VERSION ""

NS_ :

BS_:

BU_: VMCU TPM RCIOM FCIOM FAS ECUspare4 EBS EAS CCIOM BPMU APM

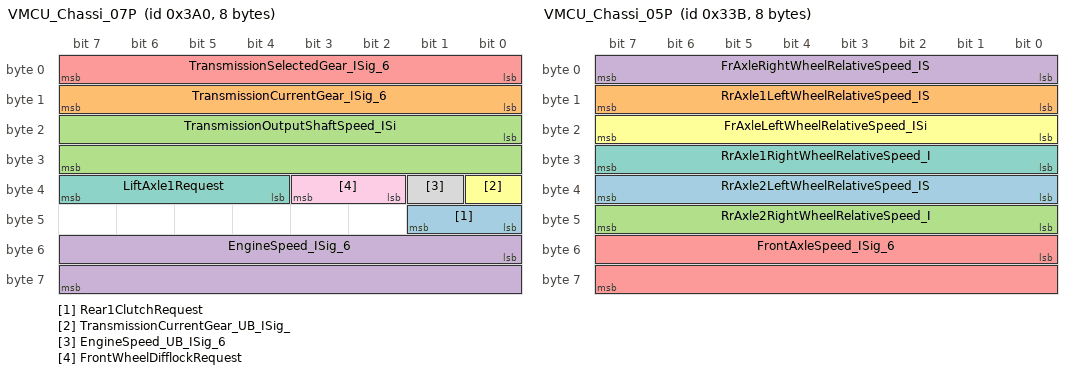
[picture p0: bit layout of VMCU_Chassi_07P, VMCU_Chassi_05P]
BO_ 928 VMCU_Chassi_07P: 8 VMCU
 SG_ Rear1ClutchRequest : 40|2@1+ (1,0) [0|0] ""  RCIOM
 SG_ TransmissionCurrentGear_ISig_6 : 8|8@1+ (1,-125) [-125|130] "GearValue"  CCIOM,APM
 SG_ TransmissionOutputShaftSpeed_ISi : 16|16@1+ (0.125,0) [0|8191.875] "rpm"  APM
 SG_ EngineSpeed_ISig_6 : 48|16@1+ (0.125,0) [0|8191.875] "rpm"  APM,FAS,CCIOM
 SG_ TransmissionSelectedGear_ISig_6 : 0|8@1+ (1,-125) [-125|130] "GearValue"  CCIOM
 SG_ TransmissionCurrentGear_UB_ISig_ : 32|1@1+ (1,0) [0|0] ""  APM,CCIOM
 SG_ LiftAxle1Request : 36|4@1+ (1,0) [0|0] ""  RCIOM
 SG_ EngineSpeed_UB_ISig_6 : 33|1@1+ (1,0) [0|0] ""  CCIOM,FAS,APM
 SG_ FrontWheelDifflockRequest : 34|2@1+ (1,0) [0|0] ""  CCIOM

BO_ 827 VMCU_Chassi_05P: 8 VMCU
 SG_ RrAxle2LeftWheelRelativeSpeed_IS : 32|8@1+ (0.0625,-7.8125) [-7.8125|8.125] "Km_per_h"  APM
 SG_ RrAxle1LeftWheelRelativeSpeed_IS : 8|8@1+ (0.0625,-7.8125) [-7.8125|8.125] "Km_per_h"  APM
 SG_ RrAxle2RightWheelRelativeSpeed_I : 40|8@1+ (0.0625,-7.8125) [-7.8125|8.125] "Km_per_h"  APM
 SG_ FrAxleRightWheelRelativeSpeed_IS : 0|8@1+ (0.0625,-7.8125) [-7.8125|8.125] "Km_per_h"  APM,RCIOM
 SG_ FrontAxleSpeed_ISig_6 : 48|16@1+ (0.00390625,0) [0|255.99609375] "Km_per_h"  CCIOM,APM,RCIOM
 SG_ FrAxleLeftWheelRelativeSpeed_ISi : 16|8@1+ (0.0625,-7.8125) [-7.8125|8.125] "Km_per_h"  RCIOM,APM
 SG_ RrAxle1RightWheelRelativeSpeed_I : 24|8@1+ (0.0625,-7.8125) [-7.8125|8.125] "Km_per_h"  APM

BO_ 537 VMCU_Chassi_04P: 8 VMCU
 SG_ RampLevelStorageRequest_ISig_6 : 16|4@1+ (1,0) [0|0] ""  RCIOM
 SG_ LevelStrokeRequest_ISig_6 : 32|2@1+ (1,0) [0|0] ""  RCIOM
 SG_ RideHeightFunctionRequest_UB_ISi : 63|1@1+ (1,0) [0|0] ""  RCIOM
 SG_ BBSystemProhibitControlRequest_I : 30|2@1+ (1,0) [0|0] ""  RCIOM
 SG_ RideHeightFunctionRequest_ISig_6 : 12|4@1+ (1,0) [0|0] ""  RCIOM
 SG_ BBSystemAlternatLoadDistribReq_I : 59|2@1+ (1,0) [0|0] ""  RCIOM
 SG_ AltLoadDistribution_rqst_ISig_6 : 56|3@1+ (1,0) [0|0] ""  RCIOM
 SG_ FerryFunctionRequest_ISig_6 : 28|2@1+ (1,0) [0|0] ""  RCIOM
 SG_ FerryFunctionSwitchChangeReq_ISi : 61|2@1+ (1,0) [0|0] ""  RCIOM
 SG_ FirstAxleLowerPrioRequested_ISig : 50|3@1+ (1,0) [0|0] ""  RCIOM
 SG_ LiftAxle1AutoLiftRequest_UB_ISig : 23|1@1+ (1,0) [0|0] ""  RCIOM
 SG_ BBSystemSpeedDepDriveLevelReq_IS : 26|2@1+ (1,0) [0|0] ""  RCIOM
 SG_ LiftAxle1LiftPositionRequest_UB_ : 39|1@1+ (1,0) [0|0] ""  RCIOM
 SG_ LoadDistributionChangeRequest_UB : 47|1@1+ (1,0) [0|0] ""  RCIOM
 SG_ LoadDistributionChangeRequest_IS : 48|2@1+ (1,0) [0|0] ""  RCIOM
 SG_ BBSystemAlternatLoadDistribReq_U : 55|1@1+ (1,0) [0|0] ""  RCIOM
 SG_ BBSystemKneelRequest_ISig_6 : 8|2@1+ (1,0) [0|0] ""  RCIOM
 SG_ LiftAxle1LiftPositionRequest_ISi : 36|3@1+ (1,0) [0|0] ""  RCIOM
 SG_ LiftAxle2AutoLiftRequest_ISig_6 : 40|2@1+ (1,0) [0|0] ""  RCIOM
 SG_ StopLevelChangeRequest_ISig_6 : 24|2@1+ (1,0) [0|0] ""  RCIOM
 SG_ RideHeightStorageRequest_ISig_6 : 4|4@1+ (1,0) [0|0] ""  RCIOM
 SG_ RampLevelRequest_ISig_6 : 0|4@1+ (1,0) [0|0] ""  RCIOM
 SG_ LiftAxle1AutoLiftRequest_ISig_6 : 34|2@1+ (1,0) [0|0] ""  RCIOM
 SG_ FirstAxleLowerPrioRequested_UB_I : 53|1@1+ (1,0) [0|0] ""  RCIOM
 SG_ LiftAxle2AutoLiftRequest_UB_ISig : 42|1@1+ (1,0) [0|0] ""  RCIOM
 SG_ AltLoadDistribution_rqst_UB_ISig : 54|1@1+ (1,0) [0|0] ""  RCIOM
 SG_ LiftAxle2LiftPositionRequest_UB_ : 46|1@1+ (1,0) [0|0] ""  RCIOM
 SG_ FerryFunctionRequest_UB_ISig_6 : 10|1@1+ (1,0) [0|0] ""  RCIOM
 SG_ LiftAxle2LiftPositionRequest_ISi : 43|3@1+ (1,0) [0|0] ""  RCIOM

BO_ 531 VMCU_Chassi_02P: 8 VMCU
 SG_ TrailerBrakePres_rqst_UB : 31|1@1+ (1,0) [0|0] ""  CCIOM
 SG_ GearLeverPosition_UB_ISig_6 : 48|1@1+ (1,0) [0|0] ""  APM,CCIOM
 SG_ WS_Washing_cmd : 6|2@1+ (1,0) [0|0] ""  FCIOM
 SG_ FrAxleDiffLockActvnDriverRqst_IS : 36|2@1+ (1,0) [0|0] ""  CCIOM
 SG_ FuncIndIlluminationLevel_ISig_6 : 24|3@1+ (1,0) [0|0] ""  APM
 SG_ TrailerBrakePres_rqst : 56|8@1+ (8,0) [0|2040] "kPa"  CCIOM
 SG_ ASREngineControlActive_ISig_6 : 38|2@1+ (1,0) [0|0] ""  FAS
 SG_ TransmissionDrivelineEngaged_ISi : 16|2@1+ (1,0) [0|0] ""  CCIOM,APM
 SG_ ReverseWarning_rqst_ISig_6 : 0|2@1+ (1,0) [0|0] ""  APM,RCIOM
 SG_ ASREngineControlActive_UB_ISig_6 : 13|1@1+ (1,0) [0|0] ""  FAS
 SG_ SplitBoxDifflockActvnDrvrRqst_UB : 50|1@1+ (1,0) [0|0] ""  CCIOM,EBS
 SG_ FogLight_Rear_cmd : 2|2@1+ (1,0) [0|0] ""  CCIOM,RCIOM
 SG_ FogLight_Front_cmd_ISig_6 : 8|2@1+ (1,0) [0|0] ""  FCIOM
 SG_ ASRBrakeControlActive_UB_ISig_6 : 12|1@1+ (1,0) [0|0] ""  EAS,FAS,APM
 SG_ TransmissionDrivelineEngaged_UB_ : 51|1@1+ (1,0) [0|0] ""  APM,CCIOM
 SG_ SplitBoxDifflockActvnDrvrRqst_IS : 22|2@1+ (1,0) [0|0] ""  EBS,CCIOM
 SG_ AntiLockBrakingActive_ISig_6 : 4|2@1+ (1,0) [0|0] ""  APM,FAS,EAS
 SG_ ASRBrakeControlActive_ISig_6 : 18|2@1+ (1,0) [0|0] ""  FAS,EAS,APM
 SG_ GearLeverPosition_ISig_6 : 27|4@1+ (1,0) [0|0] ""  CCIOM,APM
 SG_ ClutchPedalPosition_ISig_6 : 40|8@1+ (0.4,0) [0|102] "Percent"  APM
 SG_ TransmissionShiftInProcess_UB_IS : 52|1@1+ (1,0) [0|0] ""  APM
 SG_ BackToDriveReq_ISig_6 : 14|2@1+ (1,0) [0|0] ""  RCIOM
 SG_ FrAxleDiffLockActvnDriverRqst_UB : 49|1@1+ (1,0) [0|0] ""  CCIOM
 SG_ TransmissionShiftInProcess_ISig_ : 10|2@1+ (1,0) [0|0] ""  APM
 SG_ EngineTorqueMode_ISig_6 : 32|4@1+ (1,0) [0|0] ""  APM

BO_ 392 VMCU_Chassi_01P: 8 VMCU
 SG_ WorkingLightChassisOutp_cmd : 62|2@1+ (1,0) [0|0] ""  CCIOM
 SG_ PositionLight_cmd : 10|2@1+ (1,0) [0|0] ""  FCIOM,RCIOM
 SG_ StaticCornerLight_cmd : 52|3@1+ (1,0) [0|0] ""  FCIOM
 SG_ ExtraMainBeam_cmd : 14|2@1+ (1,0) [0|0] ""  FCIOM
 SG_ BacklightCmd_ISig_6 : 27|5@1+ (1,0) [0|0] ""  APM
 SG_ DirectionIndicatorLights_cmd : 16|3@1+ (1,0) [0|0] ""  RCIOM,FCIOM,CCIOM
 SG_ DirectionIndicatorLights_rqst : 24|3@1+ (1,0) [0|0] ""  FCIOM
 SG_ DriverEngineShutOff_rqst : 8|2@1+ (1,0) [0|0] ""  APM
 SG_ DippedBeam_cmd : 0|2@1+ (1,0) [0|0] ""  FCIOM,RCIOM
 SG_ BrakePedalPosition_ISig_6 : 32|8@1+ (0.4,0) [0|102] "Percent"  RCIOM,APM
 SG_ AcctrPedalKickDownSw_stat_ISig_6 : 12|2@1+ (1,0) [0|0] ""  APM
 SG_ HeadLightLevel_cmd : 56|6@1+ (1,-16) [-16|47] ""  FCIOM,CCIOM
 SG_ DRL_cmd : 4|2@1+ (1,0) [0|0] ""  RCIOM,FCIOM
 SG_ AcceleratorPedalLowIdleSwitch_IS : 2|2@1+ (1,0) [0|0] ""  APM
 SG_ MainBeam_cmd_ISig_6 : 19|3@1+ (1,0) [0|0] ""  FCIOM,RCIOM
 SG_ Hazard_rqst_ISig_6 : 6|2@1+ (1,0) [0|0] ""  FCIOM
 SG_ VehicleMode_ISig_6 : 48|4@1+ (1,0) [0|0] ""  FAS,CCIOM,TPM,RCIOM,FCIOM,APM,EAS,BPMU
 SG_ VehicleMode_UB_ISig_6 : 55|1@1+ (1,0) [0|0] ""  BPMU,EAS,APM,FAS,CCIOM,RCIOM,TPM,FCIOM
 SG_ AcceleratorPedalPosition1_ISig_6 : 40|8@1+ (0.4,0) [0|102] "Percent"  APM,CCIOM,RCIOM

BO_ 2671902706 TesterFuncDiagMsg_Chassi: 8 VMCU
 SG_ FuncDiagDataTester_ISig_6 : 0|64@1+ (1,0) [0|0] ""  APM,CCIOM,EAS,RCIOM,BPMU,FAS,TPM,FCIOM

BO_ 1248 TPM_Chassi_07P: 8 TPM
 SG_ TPMMateTrailerResp_ISig_6 : 0|3@1+ (1,0) [0|0] ""  VMCU
 SG_ Trailer2TPMLeakageWarning_UB_ISi : 30|1@1+ (1,0) [0|0] ""  VMCU
 SG_ TruckTPMPressureWarning_UB_ISig_ : 28|1@1+ (1,0) [0|0] ""  VMCU
 SG_ TPMAutomaticMating_ISig_6 : 16|2@1+ (1,0) [0|0] ""  VMCU
 SG_ Trailer1TPMPressureWarning_ISig_ : 24|3@1+ (1,0) [0|0] ""  VMCU
 SG_ Trailer1TPMPressureWarning_UB_IS : 32|1@1+ (1,0) [0|0] ""  VMCU
 SG_ TPMMateTrailerResp_UB_ISig_6 : 27|1@1+ (1,0) [0|0] ""  VMCU
 SG_ Trailer2TPMPressureWarning_UB_IS : 33|1@1+ (1,0) [0|0] ""  VMCU
 SG_ Trailer2TPMPressureWarning_ISig_ : 21|3@1+ (1,0) [0|0] ""  VMCU
 SG_ Trailer1TPMMatedStatus_ISig_6 : 11|2@1+ (1,0) [0|0] ""  VMCU
 SG_ Trailer1TPMLeakageWarning_ISig_6 : 18|3@1+ (1,0) [0|0] ""  VMCU
 SG_ Trailer2TPMMatedStatus_ISig_6 : 6|2@1+ (1,0) [0|0] ""  VMCU
 SG_ TruckTPMLeakageWarning_UB_ISig_6 : 29|1@1+ (1,0) [0|0] ""  VMCU
 SG_ TruckTPMPressureWarning_ISig_6 : 3|3@1+ (1,0) [0|0] ""  VMCU
 SG_ Trailer1TPMLeakageWarning_UB_ISi : 31|1@1+ (1,0) [0|0] ""  VMCU
 SG_ TruckTPMLeakageWarning_ISig_6 : 8|3@1+ (1,0) [0|0] ""  VMCU
 SG_ Trailer2TPMLeakageWarning_ISig_6 : 13|3@1+ (1,0) [0|0] ""  VMCU

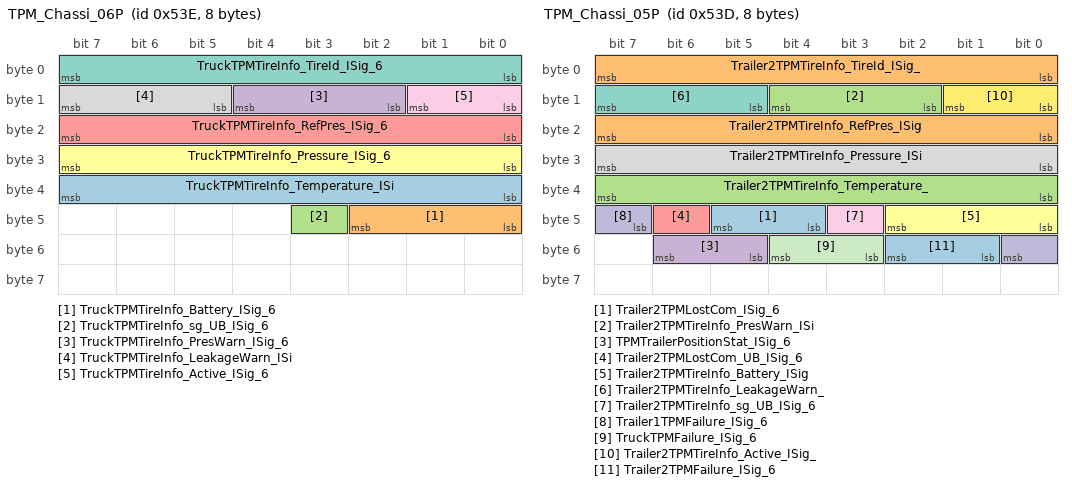
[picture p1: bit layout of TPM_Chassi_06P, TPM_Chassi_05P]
BO_ 1342 TPM_Chassi_06P: 8 TPM
 SG_ TruckTPMTireInfo_Temperature_ISi : 32|8@1+ (1,-50) [-50|205] "DegreeC"  VMCU
 SG_ TruckTPMTireInfo_Battery_ISig_6 : 40|3@1+ (1,0) [0|0] ""  VMCU
 SG_ TruckTPMTireInfo_sg_UB_ISig_6 : 43|1@1+ (1,0) [0|0] ""  VMCU
 SG_ TruckTPMTireInfo_PresWarn_ISig_6 : 10|3@1+ (1,0) [0|0] ""  VMCU
 SG_ TruckTPMTireInfo_RefPres_ISig_6 : 16|8@1+ (10,0) [0|2550] "kPa"  VMCU
 SG_ TruckTPMTireInfo_Pressure_ISig_6 : 24|8@1+ (10,0) [0|2550] "kPa"  VMCU
 SG_ TruckTPMTireInfo_TireId_ISig_6 : 0|8@1+ (1,0) [0|255] "NotApplicable"  VMCU
 SG_ TruckTPMTireInfo_LeakageWarn_ISi : 13|3@1+ (1,0) [0|0] ""  VMCU
 SG_ TruckTPMTireInfo_Active_ISig_6 : 8|2@1+ (1,0) [0|0] ""  VMCU

BO_ 1341 TPM_Chassi_05P: 8 TPM
 SG_ Trailer2TPMLostCom_ISig_6 : 44|2@1+ (1,0) [0|0] ""  VMCU
 SG_ Trailer2TPMTireInfo_RefPres_ISig : 16|8@1+ (10,0) [0|2550] "kPa"  VMCU
 SG_ Trailer2TPMTireInfo_PresWarn_ISi : 10|3@1+ (1,0) [0|0] ""  VMCU
 SG_ TPMTrailerPositionStat_ISig_6 : 53|2@1+ (1,0) [0|0] ""  VMCU
 SG_ Trailer2TPMLostCom_UB_ISig_6 : 46|1@1+ (1,0) [0|0] ""  VMCU
 SG_ Trailer2TPMTireInfo_Battery_ISig : 40|3@1+ (1,0) [0|0] ""  VMCU
 SG_ Trailer2TPMTireInfo_LeakageWarn_ : 13|3@1+ (1,0) [0|0] ""  VMCU
 SG_ Trailer2TPMTireInfo_Pressure_ISi : 24|8@1+ (10,0) [0|2550] "kPa"  VMCU
 SG_ Trailer2TPMTireInfo_sg_UB_ISig_6 : 43|1@1+ (1,0) [0|0] ""  VMCU
 SG_ Trailer1TPMFailure_ISig_6 : 47|2@1+ (1,0) [0|0] ""  VMCU
 SG_ TruckTPMFailure_ISig_6 : 51|2@1+ (1,0) [0|0] ""  VMCU
 SG_ Trailer2TPMTireInfo_Active_ISig_ : 8|2@1+ (1,0) [0|0] ""  VMCU
 SG_ Trailer2TPMFailure_ISig_6 : 49|2@1+ (1,0) [0|0] ""  VMCU
 SG_ Trailer2TPMTireInfo_TireId_ISig_ : 0|8@1+ (1,0) [0|255] "NotApplicable"  VMCU
 SG_ Trailer2TPMTireInfo_Temperature_ : 32|8@1+ (1,-50) [-50|205] "DegreeC"  VMCU

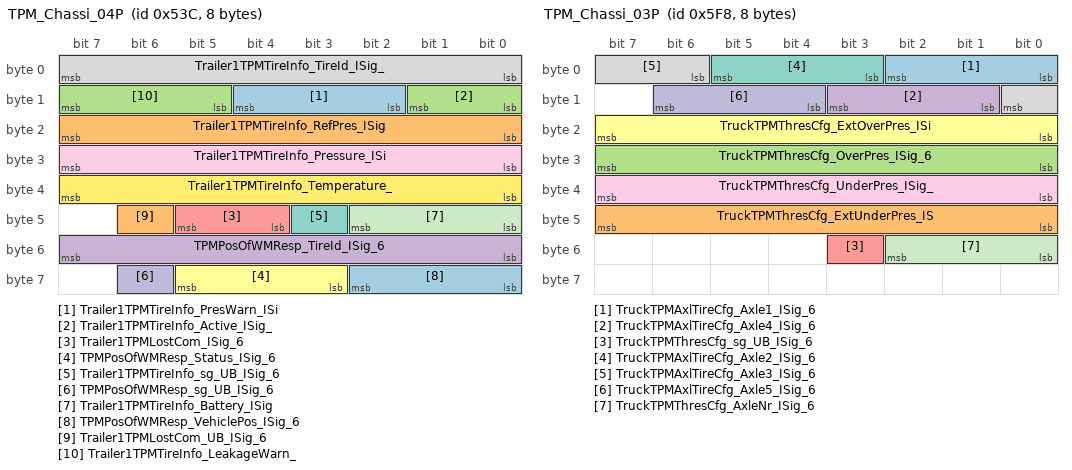
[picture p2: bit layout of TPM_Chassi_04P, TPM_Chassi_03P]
BO_ 1340 TPM_Chassi_04P: 8 TPM
 SG_ Trailer1TPMTireInfo_PresWarn_ISi : 10|3@1+ (1,0) [0|0] ""  VMCU
 SG_ Trailer1TPMTireInfo_RefPres_ISig : 16|8@1+ (10,0) [0|2550] "kPa"  VMCU
 SG_ Trailer1TPMTireInfo_Active_ISig_ : 8|2@1+ (1,0) [0|0] ""  VMCU
 SG_ TPMPosOfWMResp_TireId_ISig_6 : 48|8@1+ (1,0) [0|255] "NotApplicable"  VMCU
 SG_ Trailer1TPMLostCom_ISig_6 : 44|2@1+ (1,0) [0|0] ""  VMCU
 SG_ TPMPosOfWMResp_Status_ISig_6 : 59|3@1+ (1,0) [0|0] ""  VMCU
 SG_ Trailer1TPMTireInfo_sg_UB_ISig_6 : 43|1@1+ (1,0) [0|0] ""  VMCU
 SG_ Trailer1TPMTireInfo_TireId_ISig_ : 0|8@1+ (1,0) [0|255] "NotApplicable"  VMCU
 SG_ Trailer1TPMTireInfo_Pressure_ISi : 24|8@1+ (10,0) [0|2550] "kPa"  VMCU
 SG_ TPMPosOfWMResp_sg_UB_ISig_6 : 62|1@1+ (1,0) [0|0] ""  VMCU
 SG_ Trailer1TPMTireInfo_Battery_ISig : 40|3@1+ (1,0) [0|0] ""  VMCU
 SG_ Trailer1TPMTireInfo_Temperature_ : 32|8@1+ (1,-50) [-50|205] "DegreeC"  VMCU
 SG_ TPMPosOfWMResp_VehiclePos_ISig_6 : 56|3@1+ (1,0) [0|0] ""  VMCU
 SG_ Trailer1TPMLostCom_UB_ISig_6 : 46|1@1+ (1,0) [0|0] ""  VMCU
 SG_ Trailer1TPMTireInfo_LeakageWarn_ : 13|3@1+ (1,0) [0|0] ""  VMCU

BO_ 1528 TPM_Chassi_03P: 8 TPM
 SG_ TruckTPMAxlTireCfg_Axle1_ISig_6 : 0|3@1+ (1,0) [0|0] ""  VMCU
 SG_ TruckTPMThresCfg_ExtUnderPres_IS : 40|8@1+ (1,-125) [-125|130] "Percent"  VMCU
 SG_ TruckTPMThresCfg_OverPres_ISig_6 : 24|8@1+ (1,-125) [-125|130] "Percent"  VMCU
 SG_ TruckTPMAxlTireCfg_Axle4_ISig_6 : 9|3@1+ (1,0) [0|0] ""  VMCU
 SG_ TruckTPMThresCfg_sg_UB_ISig_6 : 51|1@1+ (1,0) [0|0] ""  VMCU
 SG_ TruckTPMThresCfg_ExtOverPres_ISi : 16|8@1+ (1,-125) [-125|130] "Percent"  VMCU
 SG_ TruckTPMAxlTireCfg_Axle2_ISig_6 : 3|3@1+ (1,0) [0|0] ""  VMCU
 SG_ TruckTPMAxlTireCfg_Axle3_ISig_6 : 6|3@1+ (1,0) [0|0] ""  VMCU
 SG_ TruckTPMThresCfg_UnderPres_ISig_ : 32|8@1+ (1,-125) [-125|130] "Percent"  VMCU
 SG_ TruckTPMAxlTireCfg_Axle5_ISig_6 : 12|3@1+ (1,0) [0|0] ""  VMCU
 SG_ TruckTPMThresCfg_AxleNr_ISig_6 : 48|3@1+ (1,0) [0|0] ""  VMCU

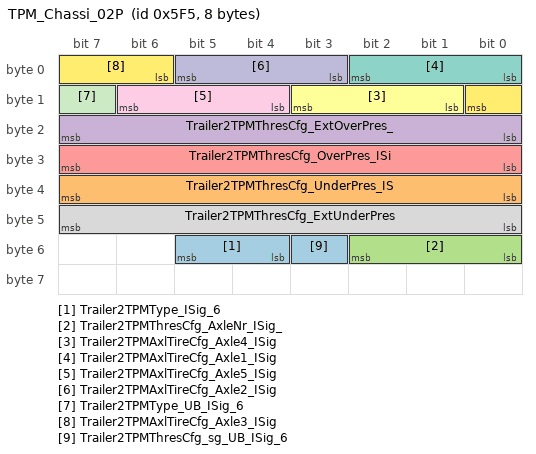
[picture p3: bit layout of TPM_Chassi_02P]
BO_ 1525 TPM_Chassi_02P: 8 TPM
 SG_ Trailer2TPMType_ISig_6 : 52|2@1+ (1,0) [0|0] ""  VMCU
 SG_ Trailer2TPMThresCfg_UnderPres_IS : 32|8@1+ (1,-125) [-125|130] "Percent"  VMCU
 SG_ Trailer2TPMThresCfg_AxleNr_ISig_ : 48|3@1+ (1,0) [0|0] ""  VMCU
 SG_ Trailer2TPMThresCfg_ExtOverPres_ : 16|8@1+ (1,-125) [-125|130] "Percent"  VMCU
 SG_ Trailer2TPMThresCfg_OverPres_ISi : 24|8@1+ (1,-125) [-125|130] "Percent"  VMCU
 SG_ Trailer2TPMAxlTireCfg_Axle4_ISig : 9|3@1+ (1,0) [0|0] ""  VMCU
 SG_ Trailer2TPMAxlTireCfg_Axle1_ISig : 0|3@1+ (1,0) [0|0] ""  VMCU
 SG_ Trailer2TPMThresCfg_ExtUnderPres : 40|8@1+ (1,-125) [-125|130] "Percent"  VMCU
 SG_ Trailer2TPMAxlTireCfg_Axle5_ISig : 12|3@1+ (1,0) [0|0] ""  VMCU
 SG_ Trailer2TPMAxlTireCfg_Axle2_ISig : 3|3@1+ (1,0) [0|0] ""  VMCU
 SG_ Trailer2TPMType_UB_ISig_6 : 15|1@1+ (1,0) [0|0] ""  VMCU
 SG_ Trailer2TPMAxlTireCfg_Axle3_ISig : 6|3@1+ (1,0) [0|0] ""  VMCU
 SG_ Trailer2TPMThresCfg_sg_UB_ISig_6 : 51|1@1+ (1,0) [0|0] ""  VMCU

CM_ SG_ 928 TransmissionCurrentGear_ISig_6 "254 Error ; 255 Not available";
CM_ SG_ 928 TransmissionOutputShaftSpeed_ISi "65024 - 65279 Error ; 65280 - 65535 Not available";
CM_ SG_ 928 EngineSpeed_ISig_6 "65024 - 65279 Error ; 65280 - 65535 Not available";
CM_ SG_ 928 TransmissionSelectedGear_ISig_6 "254 Error ; 255 Not available";
CM_ BO_ 827 "This is a sporadic message but this message comes periodically because all signal in the message are gatewayed signals from BB1 and they are periodical there. If there is no traffic on BB1 this message is not sent on Chassi network.";
CM_ SG_ 827 RrAxle2LeftWheelRelativeSpeed_IS "254 Error ; 255 Not available";
CM_ SG_ 827 RrAxle1LeftWheelRelativeSpeed_IS "254 Error ; 255 Not available";
CM_ SG_ 827 RrAxle2RightWheelRelativeSpeed_I "254 Error ; 255 Not available";
CM_ SG_ 827 FrAxleRightWheelRelativeSpeed_IS "254 Error ; 255 Not available";
CM_ SG_ 827 FrontAxleSpeed_ISig_6 "65024 - 65279 Error ; 65280 - 65535 Not available";
CM_ SG_ 827 FrAxleLeftWheelRelativeSpeed_ISi "254 Error ; 255 Not available";
CM_ SG_ 827 RrAxle1RightWheelRelativeSpeed_I "254 Error ; 255 Not available";
CM_ SG_ 531 TrailerBrakePres_rqst "254 Error ; 255 Not available";
CM_ SG_ 531 ClutchPedalPosition_ISig_6 "254 Error ; 255 Not available";
CM_ SG_ 392 BrakePedalPosition_ISig_6 "254 Error ; 255 Not available";
CM_ SG_ 392 HeadLightLevel_cmd "62 Error ; 63 Not available";
CM_ SG_ 392 AcceleratorPedalPosition1_ISig_6 "254 Error ; 255 Not available";
CM_ SG_ 1342 TruckTPMTireInfo_Temperature_ISi "251-253	Spare; 254 Error; 255 NotAvailable;";
CM_ SG_ 1342 TruckTPMTireInfo_RefPres_ISig_6 "251-253 Spare; 254 Error; 255 NotAvailable;";
CM_ SG_ 1342 TruckTPMTireInfo_Pressure_ISig_6 "251-253 Spare; 254 Error; 255 NotAvailable;";
CM_ SG_ 1341 Trailer2TPMTireInfo_RefPres_ISig "251-253 Spare; 254 Error; 255 NotAvailable;";
CM_ SG_ 1341 Trailer2TPMTireInfo_Pressure_ISi "251-253 Spare; 254 Error; 255 NotAvailable;";
CM_ SG_ 1341 Trailer2TPMTireInfo_Temperature_ "251-253	Spare; 254 Error; 255 NotAvailable;";
CM_ SG_ 1340 Trailer1TPMTireInfo_RefPres_ISig "251-253 Spare; 254 Error; 255 NotAvailable;";
CM_ SG_ 1340 Trailer1TPMTireInfo_Pressure_ISi "251-253 Spare; 254 Error; 255 NotAvailable;";
CM_ SG_ 1340 Trailer1TPMTireInfo_Temperature_ "251-253	Spare; 254 Error; 255 NotAvailable;";
BA_DEF_ BO_  "GenMsgStartDelayTime" INT 0 0;
BA_DEF_ BO_  "GenMsgDelayTime" INT 0 0;
BA_DEF_ BO_  "GenMsgCycleTime" INT 0 0;
BA_DEF_ BO_  "GenMsgSendType" ENUM  "Cyclic","NotUsed","NotUsed","NotUsed","NotUsed","NotUsed","NotUsed","IfActive","NoMsgSendType","NotUsed";
BA_DEF_ SG_  "GenSigStartValue" INT 0 0;
BA_DEF_ SG_  "GenSigInactiveValue" INT 0 0;
BA_DEF_ SG_  "GenSigCycleTimeActive" INT 0 0;
BA_DEF_ SG_  "GenSigCycleTime" INT 0 0;
BA_DEF_ SG_  "GenSigSendType" ENUM  "Cyclic","OnWrite","OnWriteWithRepetition","OnChange","OnChangeWithRepetition","IfActive","IfActiveWithRepetition","NoSigSendType","NotUsed","NotUsed","NotUsed","NotUsed","NotUsed";
BA_DEF_ BO_  "VFrameFormat" ENUM  "StandardCAN","ExtendedCAN","reserved","J1939PG";
BA_DEF_ SG_  "SigType" ENUM  "Default","Range","RangeSigned","ASCII","Discrete","Control","ReferencePGN","DTC","StringDelimiter","StringLength","StringLengthControl";
BA_DEF_ SG_  "SeToolVersion_SIGNAL" STRING ;
BA_DEF_ SG_  "SeToolUniqueID_SIGNAL" STRING ;
BA_DEF_ SG_  "SeToolName_SIGNAL" STRING ;
BA_DEF_ SG_  "SeToolItemID_SIGNAL" STRING ;
BA_DEF_ SG_  "SeToolAncestorID_SIGNAL" STRING ;
BA_DEF_ SG_  "Platform_VMCU1_Sig" ENUM  "No","Yes";
BA_DEF_ BO_  "NmAsrMessage" ENUM  "No","Yes";
BA_DEF_ SG_  "NeedsUpdateBit" ENUM  "No","Yes";
BA_DEF_ SG_  "MmAnSignal" ENUM  "No","Yes";
BA_DEF_ SG_  "GenSigMaxLatency" INT 0 65535;
BA_DEF_ SG_  "GenSigILSupport" ENUM  "Yes","No";
BA_DEF_ BO_  "GenMsgRequestable" INT 0 1;
BA_DEF_ BO_  "GenMsgILSupport" ENUM  "No","Yes";
BA_DEF_ BO_  "DiagUUDTResponse" ENUM  "No","Yes";
BA_DEF_ BO_  "DiagState" ENUM  "No","Yes";
BA_DEF_ BO_  "DiagResponse" ENUM  "No","Yes";
BA_DEF_ BO_  "DiagRequest" ENUM  "No","Yes";
BA_DEF_ BO_  "DiagConnection" HEX 0 65535;
BA_DEF_ BO_  "CanTpFcFrameId" HEX 0 2147483647;
BA_DEF_ BO_  "CanTpBs" INT 0 255;
BA_DEF_ SG_  "SystemSignalLongSymbol" STRING ;
BA_DEF_REL_ BU_SG_REL_  "GenSigTimeoutTime" INT 0 65535;
BA_DEF_REL_ BU_SG_REL_  "GenSigFirstTimeoutTime" INT 0 65535;
BA_DEF_DEF_  "GenMsgStartDelayTime" 0;
BA_DEF_DEF_  "GenMsgDelayTime" 0;
BA_DEF_DEF_  "GenMsgCycleTime" 0;
BA_DEF_DEF_  "GenMsgSendType" "Cyclic";
BA_DEF_DEF_  "GenSigStartValue" 0;
BA_DEF_DEF_  "GenSigInactiveValue" 0;
BA_DEF_DEF_  "GenSigCycleTimeActive" 0;
BA_DEF_DEF_  "GenSigCycleTime" 0;
BA_DEF_DEF_  "GenSigSendType" "Cyclic";
BA_DEF_DEF_  "VFrameFormat" "ExtendedCAN";
BA_DEF_DEF_  "SigType" "Default";
BA_DEF_DEF_  "SeToolVersion_SIGNAL" "";
BA_DEF_DEF_  "SeToolUniqueID_SIGNAL" "";
BA_DEF_DEF_  "SeToolName_SIGNAL" "";
BA_DEF_DEF_  "SeToolItemID_SIGNAL" "";
BA_DEF_DEF_  "SeToolAncestorID_SIGNAL" "";
BA_DEF_DEF_  "Platform_VMCU1_Sig" "No";
BA_DEF_DEF_  "NmAsrMessage" "No";
BA_DEF_DEF_  "NeedsUpdateBit" "No";
BA_DEF_DEF_  "MmAnSignal" "No";
BA_DEF_DEF_  "GenSigMaxLatency" 0;
BA_DEF_DEF_  "GenSigILSupport" "Yes";
BA_DEF_DEF_  "GenMsgRequestable" 1;
BA_DEF_DEF_  "GenMsgILSupport" "Yes";
BA_DEF_DEF_  "DiagUUDTResponse" "No";
BA_DEF_DEF_  "DiagState" "No";
BA_DEF_DEF_  "DiagResponse" "No";
BA_DEF_DEF_  "DiagRequest" "No";
BA_DEF_DEF_  "DiagConnection" 0;
BA_DEF_DEF_  "CanTpFcFrameId" 2147483647;
BA_DEF_DEF_  "CanTpBs" 255;
BA_DEF_DEF_REL_ "GenSigTimeoutTime" 0;
BA_DEF_DEF_REL_ "GenSigFirstTimeoutTime" 0;
BA_DEF_DEF_  "SystemSignalLongSymbol" "";
BA_ "VFrameFormat" BO_ 928 0;
BA_ "GenMsgCycleTime" BO_ 928 45;
BA_ "GenMsgStartDelayTime" BO_ 928 20;
BA_ "VFrameFormat" BO_ 827 0;
BA_ "GenMsgSendType" BO_ 827 8;
BA_ "GenMsgDelayTime" BO_ 827 25;
BA_ "VFrameFormat" BO_ 537 0;
BA_ "GenMsgCycleTime" BO_ 537 20;
BA_ "GenMsgStartDelayTime" BO_ 537 15;
BA_ "VFrameFormat" BO_ 531 0;
BA_ "GenMsgCycleTime" BO_ 531 20;
BA_ "VFrameFormat" BO_ 392 0;
BA_ "GenMsgCycleTime" BO_ 392 10;
BA_ "DiagConnection" BO_ 2671902706 61987;
BA_ "DiagState" BO_ 2671902706 1;
BA_ "GenMsgILSupport" BO_ 2671902706 0;
BA_ "GenMsgSendType" BO_ 2671902706 8;
BA_ "VFrameFormat" BO_ 1248 0;
BA_ "GenMsgCycleTime" BO_ 1248 100;
BA_ "GenMsgStartDelayTime" BO_ 1248 15;
BA_ "VFrameFormat" BO_ 1342 0;
BA_ "GenMsgCycleTime" BO_ 1342 200;
BA_ "GenMsgStartDelayTime" BO_ 1342 20;
BA_ "VFrameFormat" BO_ 1341 0;
BA_ "GenMsgCycleTime" BO_ 1341 200;
BA_ "GenMsgStartDelayTime" BO_ 1341 25;
BA_ "VFrameFormat" BO_ 1340 0;
BA_ "GenMsgCycleTime" BO_ 1340 200;
BA_ "GenMsgStartDelayTime" BO_ 1340 55;
BA_ "VFrameFormat" BO_ 1528 0;
BA_ "GenMsgCycleTime" BO_ 1528 1000;
BA_ "GenMsgStartDelayTime" BO_ 1528 135;
BA_ "VFrameFormat" BO_ 1525 0;
BA_ "GenMsgCycleTime" BO_ 1525 1000;
BA_ "GenMsgStartDelayTime" BO_ 1525 140;
BA_ "GenSigCycleTime" SG_ 928 Rear1ClutchRequest 100;
BA_ "GenSigCycleTimeActive" SG_ 928 Rear1ClutchRequest 100;
BA_ "GenSigStartValue" SG_ 928 Rear1ClutchRequest 3;
BA_ "Platform_VMCU1_Sig" SG_ 928 Rear1ClutchRequest 1;
BA_ "GenSigCycleTime" SG_ 928 TransmissionCurrentGear_ISig_6 100;
BA_ "GenSigCycleTimeActive" SG_ 928 TransmissionCurrentGear_ISig_6 100;
BA_ "GenSigStartValue" SG_ 928 TransmissionCurrentGear_ISig_6 255;
BA_ "GenSigMaxLatency" SG_ 928 TransmissionCurrentGear_ISig_6 52;
BA_ "NeedsUpdateBit" SG_ 928 TransmissionCurrentGear_ISig_6 1;
BA_ "Platform_VMCU1_Sig" SG_ 928 TransmissionCurrentGear_ISig_6 1;
BA_ "SeToolAncestorID_SIGNAL" SG_ 928 TransmissionCurrentGear_ISig_6 "x0000001D0412E700";
BA_ "SeToolItemID_SIGNAL" SG_ 928 TransmissionCurrentGear_ISig_6 "x0000001D0412E700";
BA_ "SeToolName_SIGNAL" SG_ 928 TransmissionCurrentGear_ISig_6 "TransmissionCurrentGear";
BA_ "SeToolVersion_SIGNAL" SG_ 928 TransmissionCurrentGear_ISig_6 "1";
BA_ "GenSigCycleTime" SG_ 928 TransmissionOutputShaftSpeed_ISi 100;
BA_ "GenSigCycleTimeActive" SG_ 928 TransmissionOutputShaftSpeed_ISi 100;
BA_ "GenSigStartValue" SG_ 928 TransmissionOutputShaftSpeed_ISi 65535;
BA_ "GenSigMaxLatency" SG_ 928 TransmissionOutputShaftSpeed_ISi 52;
BA_ "Platform_VMCU1_Sig" SG_ 928 TransmissionOutputShaftSpeed_ISi 1;
BA_ "SeToolAncestorID_SIGNAL" SG_ 928 TransmissionOutputShaftSpeed_ISi "x0000001D0412AAA9";
BA_ "SeToolItemID_SIGNAL" SG_ 928 TransmissionOutputShaftSpeed_ISi "x0000001D0412AAA9";
BA_ "SeToolName_SIGNAL" SG_ 928 TransmissionOutputShaftSpeed_ISi "TransmissionOutputShaftSpeed";
BA_ "SeToolVersion_SIGNAL" SG_ 928 TransmissionOutputShaftSpeed_ISi "1";
BA_ "SystemSignalLongSymbol" SG_ 928 TransmissionOutputShaftSpeed_ISi "TransmissionOutputShaftSpeed_ISig_6";
BA_ "GenSigCycleTime" SG_ 928 EngineSpeed_ISig_6 100;
BA_ "GenSigCycleTimeActive" SG_ 928 EngineSpeed_ISig_6 100;
BA_ "GenSigStartValue" SG_ 928 EngineSpeed_ISig_6 65535;
BA_ "GenSigMaxLatency" SG_ 928 EngineSpeed_ISig_6 54;
BA_ "NeedsUpdateBit" SG_ 928 EngineSpeed_ISig_6 1;
BA_ "Platform_VMCU1_Sig" SG_ 928 EngineSpeed_ISig_6 1;
BA_ "SeToolAncestorID_SIGNAL" SG_ 928 EngineSpeed_ISig_6 "x0000001D0410BACF";
BA_ "SeToolItemID_SIGNAL" SG_ 928 EngineSpeed_ISig_6 "x0000001D0410BACF";
BA_ "SeToolName_SIGNAL" SG_ 928 EngineSpeed_ISig_6 "EngineSpeed_status";
BA_ "SeToolVersion_SIGNAL" SG_ 928 EngineSpeed_ISig_6 "1";
BA_ "GenSigCycleTime" SG_ 928 TransmissionSelectedGear_ISig_6 100;
BA_ "GenSigCycleTimeActive" SG_ 928 TransmissionSelectedGear_ISig_6 100;
BA_ "GenSigStartValue" SG_ 928 TransmissionSelectedGear_ISig_6 255;
BA_ "GenSigMaxLatency" SG_ 928 TransmissionSelectedGear_ISig_6 52;
BA_ "Platform_VMCU1_Sig" SG_ 928 TransmissionSelectedGear_ISig_6 1;
BA_ "SeToolAncestorID_SIGNAL" SG_ 928 TransmissionSelectedGear_ISig_6 "x0000001D0416F5A6";
BA_ "SeToolItemID_SIGNAL" SG_ 928 TransmissionSelectedGear_ISig_6 "x0000001D0416F5A6";
BA_ "SeToolName_SIGNAL" SG_ 928 TransmissionSelectedGear_ISig_6 "TransmissionSelectedGear";
BA_ "SeToolVersion_SIGNAL" SG_ 928 TransmissionSelectedGear_ISig_6 "1";
BA_ "GenSigSendType" SG_ 928 TransmissionCurrentGear_UB_ISig_ 7;
BA_ "Platform_VMCU1_Sig" SG_ 928 TransmissionCurrentGear_UB_ISig_ 1;
BA_ "SystemSignalLongSymbol" SG_ 928 TransmissionCurrentGear_UB_ISig_ "TransmissionCurrentGear_UB_ISig_6";
BA_ "GenSigCycleTime" SG_ 928 LiftAxle1Request 100;
BA_ "GenSigCycleTimeActive" SG_ 928 LiftAxle1Request 100;
BA_ "GenSigStartValue" SG_ 928 LiftAxle1Request 15;
BA_ "Platform_VMCU1_Sig" SG_ 928 LiftAxle1Request 1;
BA_ "GenSigSendType" SG_ 928 EngineSpeed_UB_ISig_6 7;
BA_ "Platform_VMCU1_Sig" SG_ 928 EngineSpeed_UB_ISig_6 1;
BA_ "GenSigCycleTime" SG_ 928 FrontWheelDifflockRequest 100;
BA_ "GenSigCycleTimeActive" SG_ 928 FrontWheelDifflockRequest 100;
BA_ "GenSigStartValue" SG_ 928 FrontWheelDifflockRequest 3;
BA_ "Platform_VMCU1_Sig" SG_ 928 FrontWheelDifflockRequest 1;
BA_ "GenSigSendType" SG_ 827 RrAxle2LeftWheelRelativeSpeed_IS 1;
BA_ "GenSigStartValue" SG_ 827 RrAxle2LeftWheelRelativeSpeed_IS 255;
BA_ "Platform_VMCU1_Sig" SG_ 827 RrAxle2LeftWheelRelativeSpeed_IS 1;
BA_ "SeToolAncestorID_SIGNAL" SG_ 827 RrAxle2LeftWheelRelativeSpeed_IS "x0000001D041519D1";
BA_ "SeToolItemID_SIGNAL" SG_ 827 RrAxle2LeftWheelRelativeSpeed_IS "x0000001D041519D1";
BA_ "SeToolName_SIGNAL" SG_ 827 RrAxle2LeftWheelRelativeSpeed_IS "RelativeSpeedRearAxle#2LeftWheel";
BA_ "SeToolVersion_SIGNAL" SG_ 827 RrAxle2LeftWheelRelativeSpeed_IS "1";
BA_ "SystemSignalLongSymbol" SG_ 827 RrAxle2LeftWheelRelativeSpeed_IS "RrAxle2LeftWheelRelativeSpeed_ISig_6";
BA_ "GenSigSendType" SG_ 827 RrAxle1LeftWheelRelativeSpeed_IS 1;
BA_ "GenSigStartValue" SG_ 827 RrAxle1LeftWheelRelativeSpeed_IS 255;
BA_ "Platform_VMCU1_Sig" SG_ 827 RrAxle1LeftWheelRelativeSpeed_IS 1;
BA_ "SeToolAncestorID_SIGNAL" SG_ 827 RrAxle1LeftWheelRelativeSpeed_IS "x0000001D041519CB";
BA_ "SeToolItemID_SIGNAL" SG_ 827 RrAxle1LeftWheelRelativeSpeed_IS "x0000001D041519CB";
BA_ "SeToolName_SIGNAL" SG_ 827 RrAxle1LeftWheelRelativeSpeed_IS "RelativeSpeedRearAxle#1LeftWheel";
BA_ "SeToolVersion_SIGNAL" SG_ 827 RrAxle1LeftWheelRelativeSpeed_IS "1";
BA_ "SystemSignalLongSymbol" SG_ 827 RrAxle1LeftWheelRelativeSpeed_IS "RrAxle1LeftWheelRelativeSpeed_ISig_6";
BA_ "GenSigSendType" SG_ 827 RrAxle2RightWheelRelativeSpeed_I 1;
BA_ "GenSigStartValue" SG_ 827 RrAxle2RightWheelRelativeSpeed_I 255;
BA_ "Platform_VMCU1_Sig" SG_ 827 RrAxle2RightWheelRelativeSpeed_I 1;
BA_ "SeToolAncestorID_SIGNAL" SG_ 827 RrAxle2RightWheelRelativeSpeed_I "x0000001D041519D3";
BA_ "SeToolItemID_SIGNAL" SG_ 827 RrAxle2RightWheelRelativeSpeed_I "x0000001D041519D3";
BA_ "SeToolName_SIGNAL" SG_ 827 RrAxle2RightWheelRelativeSpeed_I "RelativeSpeedRearAxle#2RightWheel";
BA_ "SeToolVersion_SIGNAL" SG_ 827 RrAxle2RightWheelRelativeSpeed_I "1";
BA_ "SystemSignalLongSymbol" SG_ 827 RrAxle2RightWheelRelativeSpeed_I "RrAxle2RightWheelRelativeSpeed_ISig_6";
BA_ "GenSigSendType" SG_ 827 FrAxleRightWheelRelativeSpeed_IS 1;
BA_ "GenSigStartValue" SG_ 827 FrAxleRightWheelRelativeSpeed_IS 255;
BA_ "GenSigMaxLatency" SG_ 827 FrAxleRightWheelRelativeSpeed_IS 50;
BA_ "Platform_VMCU1_Sig" SG_ 827 FrAxleRightWheelRelativeSpeed_IS 1;
BA_ "SeToolAncestorID_SIGNAL" SG_ 827 FrAxleRightWheelRelativeSpeed_IS "x0000001D041519BA";
BA_ "SeToolItemID_SIGNAL" SG_ 827 FrAxleRightWheelRelativeSpeed_IS "x0000001D041519BA";
BA_ "SeToolName_SIGNAL" SG_ 827 FrAxleRightWheelRelativeSpeed_IS "RelativeSpeedFrontAxleRightWheel";
BA_ "SeToolVersion_SIGNAL" SG_ 827 FrAxleRightWheelRelativeSpeed_IS "1";
BA_ "SystemSignalLongSymbol" SG_ 827 FrAxleRightWheelRelativeSpeed_IS "FrAxleRightWheelRelativeSpeed_ISig_6";
BA_ "GenSigSendType" SG_ 827 FrontAxleSpeed_ISig_6 1;
BA_ "GenSigStartValue" SG_ 827 FrontAxleSpeed_ISig_6 65535;
BA_ "GenSigMaxLatency" SG_ 827 FrontAxleSpeed_ISig_6 50;
BA_ "Platform_VMCU1_Sig" SG_ 827 FrontAxleSpeed_ISig_6 1;
BA_ "SeToolAncestorID_SIGNAL" SG_ 827 FrontAxleSpeed_ISig_6 "x0000001D041519B4";
BA_ "SeToolItemID_SIGNAL" SG_ 827 FrontAxleSpeed_ISig_6 "x0000001D041519B4";
BA_ "SeToolName_SIGNAL" SG_ 827 FrontAxleSpeed_ISig_6 "FrontAxleSpeed";
BA_ "SeToolVersion_SIGNAL" SG_ 827 FrontAxleSpeed_ISig_6 "1";
BA_ "GenSigSendType" SG_ 827 FrAxleLeftWheelRelativeSpeed_ISi 1;
BA_ "GenSigStartValue" SG_ 827 FrAxleLeftWheelRelativeSpeed_ISi 255;
BA_ "GenSigMaxLatency" SG_ 827 FrAxleLeftWheelRelativeSpeed_ISi 50;
BA_ "Platform_VMCU1_Sig" SG_ 827 FrAxleLeftWheelRelativeSpeed_ISi 1;
BA_ "SeToolAncestorID_SIGNAL" SG_ 827 FrAxleLeftWheelRelativeSpeed_ISi "x0000001D041519B8";
BA_ "SeToolItemID_SIGNAL" SG_ 827 FrAxleLeftWheelRelativeSpeed_ISi "x0000001D041519B8";
BA_ "SeToolName_SIGNAL" SG_ 827 FrAxleLeftWheelRelativeSpeed_ISi "RelativeSpeedFrontAxleLeftWheel";
BA_ "SeToolVersion_SIGNAL" SG_ 827 FrAxleLeftWheelRelativeSpeed_ISi "1";
BA_ "SystemSignalLongSymbol" SG_ 827 FrAxleLeftWheelRelativeSpeed_ISi "FrAxleLeftWheelRelativeSpeed_ISig_6";
BA_ "GenSigSendType" SG_ 827 RrAxle1RightWheelRelativeSpeed_I 1;
BA_ "GenSigStartValue" SG_ 827 RrAxle1RightWheelRelativeSpeed_I 255;
BA_ "Platform_VMCU1_Sig" SG_ 827 RrAxle1RightWheelRelativeSpeed_I 1;
BA_ "SeToolAncestorID_SIGNAL" SG_ 827 RrAxle1RightWheelRelativeSpeed_I "x0000001D041519CD";
BA_ "SeToolItemID_SIGNAL" SG_ 827 RrAxle1RightWheelRelativeSpeed_I "x0000001D041519CD";
BA_ "SeToolName_SIGNAL" SG_ 827 RrAxle1RightWheelRelativeSpeed_I "RelativeSpeedRearAxle#1RightWheel";
BA_ "SeToolVersion_SIGNAL" SG_ 827 RrAxle1RightWheelRelativeSpeed_I "1";
BA_ "SystemSignalLongSymbol" SG_ 827 RrAxle1RightWheelRelativeSpeed_I "RrAxle1RightWheelRelativeSpeed_ISig_6";
BA_ "GenSigCycleTime" SG_ 537 RampLevelStorageRequest_ISig_6 100;
BA_ "GenSigCycleTimeActive" SG_ 537 RampLevelStorageRequest_ISig_6 100;
BA_ "GenSigStartValue" SG_ 537 RampLevelStorageRequest_ISig_6 15;
BA_ "GenSigMaxLatency" SG_ 537 RampLevelStorageRequest_ISig_6 29;
BA_ "Platform_VMCU1_Sig" SG_ 537 RampLevelStorageRequest_ISig_6 1;
BA_ "SeToolAncestorID_SIGNAL" SG_ 537 RampLevelStorageRequest_ISig_6 "x0000001D041301E3";
BA_ "SeToolItemID_SIGNAL" SG_ 537 RampLevelStorageRequest_ISig_6 "x0000001D041301E3";
BA_ "SeToolName_SIGNAL" SG_ 537 RampLevelStorageRequest_ISig_6 "RampLevelStorageRequest";
BA_ "SeToolVersion_SIGNAL" SG_ 537 RampLevelStorageRequest_ISig_6 "1";
BA_ "GenSigCycleTime" SG_ 537 LevelStrokeRequest_ISig_6 100;
BA_ "GenSigCycleTimeActive" SG_ 537 LevelStrokeRequest_ISig_6 100;
BA_ "GenSigStartValue" SG_ 537 LevelStrokeRequest_ISig_6 3;
BA_ "GenSigMaxLatency" SG_ 537 LevelStrokeRequest_ISig_6 29;
BA_ "Platform_VMCU1_Sig" SG_ 537 LevelStrokeRequest_ISig_6 1;
BA_ "SeToolAncestorID_SIGNAL" SG_ 537 LevelStrokeRequest_ISig_6 "x0000001D0413029C";
BA_ "SeToolItemID_SIGNAL" SG_ 537 LevelStrokeRequest_ISig_6 "x0000001D0413029C";
BA_ "SeToolName_SIGNAL" SG_ 537 LevelStrokeRequest_ISig_6 "LevelStrokeRequest";
BA_ "SeToolVersion_SIGNAL" SG_ 537 LevelStrokeRequest_ISig_6 "1";
BA_ "GenSigSendType" SG_ 537 RideHeightFunctionRequest_UB_ISi 7;
BA_ "Platform_VMCU1_Sig" SG_ 537 RideHeightFunctionRequest_UB_ISi 1;
BA_ "SystemSignalLongSymbol" SG_ 537 RideHeightFunctionRequest_UB_ISi "RideHeightFunctionRequest_UB_ISig_6";
BA_ "GenSigCycleTime" SG_ 537 BBSystemProhibitControlRequest_I 100;
BA_ "GenSigCycleTimeActive" SG_ 537 BBSystemProhibitControlRequest_I 100;
BA_ "GenSigStartValue" SG_ 537 BBSystemProhibitControlRequest_I 3;
BA_ "Platform_VMCU1_Sig" SG_ 537 BBSystemProhibitControlRequest_I 1;
BA_ "SystemSignalLongSymbol" SG_ 537 BBSystemProhibitControlRequest_I "BBSystemProhibitControlRequest_ISig_6";
BA_ "GenSigCycleTime" SG_ 537 RideHeightFunctionRequest_ISig_6 100;
BA_ "GenSigCycleTimeActive" SG_ 537 RideHeightFunctionRequest_ISig_6 100;
BA_ "GenSigStartValue" SG_ 537 RideHeightFunctionRequest_ISig_6 15;
BA_ "GenSigMaxLatency" SG_ 537 RideHeightFunctionRequest_ISig_6 29;
BA_ "NeedsUpdateBit" SG_ 537 RideHeightFunctionRequest_ISig_6 1;
BA_ "Platform_VMCU1_Sig" SG_ 537 RideHeightFunctionRequest_ISig_6 1;
BA_ "SeToolAncestorID_SIGNAL" SG_ 537 RideHeightFunctionRequest_ISig_6 "x0000001D0412F86D";
BA_ "SeToolItemID_SIGNAL" SG_ 537 RideHeightFunctionRequest_ISig_6 "x0000001D043FB86B";
BA_ "SeToolName_SIGNAL" SG_ 537 RideHeightFunctionRequest_ISig_6 "RideHeightFunctionRequest";
BA_ "SeToolVersion_SIGNAL" SG_ 537 RideHeightFunctionRequest_ISig_6 "2";
BA_ "GenSigCycleTime" SG_ 537 BBSystemAlternatLoadDistribReq_I 100;
BA_ "GenSigCycleTimeActive" SG_ 537 BBSystemAlternatLoadDistribReq_I 100;
BA_ "GenSigStartValue" SG_ 537 BBSystemAlternatLoadDistribReq_I 3;
BA_ "NeedsUpdateBit" SG_ 537 BBSystemAlternatLoadDistribReq_I 1;
BA_ "Platform_VMCU1_Sig" SG_ 537 BBSystemAlternatLoadDistribReq_I 1;
BA_ "SystemSignalLongSymbol" SG_ 537 BBSystemAlternatLoadDistribReq_I "BBSystemAlternatLoadDistribReq_ISig_6";
BA_ "GenSigCycleTime" SG_ 537 AltLoadDistribution_rqst_ISig_6 100;
BA_ "GenSigCycleTimeActive" SG_ 537 AltLoadDistribution_rqst_ISig_6 100;
BA_ "GenSigStartValue" SG_ 537 AltLoadDistribution_rqst_ISig_6 7;
BA_ "GenSigMaxLatency" SG_ 537 AltLoadDistribution_rqst_ISig_6 29;
BA_ "NeedsUpdateBit" SG_ 537 AltLoadDistribution_rqst_ISig_6 1;
BA_ "Platform_VMCU1_Sig" SG_ 537 AltLoadDistribution_rqst_ISig_6 1;
BA_ "SeToolAncestorID_SIGNAL" SG_ 537 AltLoadDistribution_rqst_ISig_6 "x0000001D04189EA3";
BA_ "SeToolItemID_SIGNAL" SG_ 537 AltLoadDistribution_rqst_ISig_6 "x0000001D04189EA3";
BA_ "SeToolName_SIGNAL" SG_ 537 AltLoadDistribution_rqst_ISig_6 "AlternativeLoadDistributionRequest";
BA_ "SeToolVersion_SIGNAL" SG_ 537 AltLoadDistribution_rqst_ISig_6 "1";
BA_ "GenSigCycleTime" SG_ 537 FerryFunctionRequest_ISig_6 100;
BA_ "GenSigCycleTimeActive" SG_ 537 FerryFunctionRequest_ISig_6 100;
BA_ "GenSigStartValue" SG_ 537 FerryFunctionRequest_ISig_6 3;
BA_ "GenSigMaxLatency" SG_ 537 FerryFunctionRequest_ISig_6 29;
BA_ "NeedsUpdateBit" SG_ 537 FerryFunctionRequest_ISig_6 1;
BA_ "Platform_VMCU1_Sig" SG_ 537 FerryFunctionRequest_ISig_6 1;
BA_ "SeToolAncestorID_SIGNAL" SG_ 537 FerryFunctionRequest_ISig_6 "x0000001D04131411";
BA_ "SeToolItemID_SIGNAL" SG_ 537 FerryFunctionRequest_ISig_6 "x0000001D04131411";
BA_ "SeToolName_SIGNAL" SG_ 537 FerryFunctionRequest_ISig_6 "FerryFunctionRequest";
BA_ "SeToolVersion_SIGNAL" SG_ 537 FerryFunctionRequest_ISig_6 "1";
BA_ "GenSigCycleTime" SG_ 537 FerryFunctionSwitchChangeReq_ISi 100;
BA_ "GenSigCycleTimeActive" SG_ 537 FerryFunctionSwitchChangeReq_ISi 100;
BA_ "GenSigStartValue" SG_ 537 FerryFunctionSwitchChangeReq_ISi 3;
BA_ "Platform_VMCU1_Sig" SG_ 537 FerryFunctionSwitchChangeReq_ISi 1;
BA_ "SystemSignalLongSymbol" SG_ 537 FerryFunctionSwitchChangeReq_ISi "FerryFunctionSwitchChangeReq_ISig_6";
BA_ "GenSigCycleTime" SG_ 537 FirstAxleLowerPrioRequested_ISig 100;
BA_ "GenSigCycleTimeActive" SG_ 537 FirstAxleLowerPrioRequested_ISig 100;
BA_ "GenSigStartValue" SG_ 537 FirstAxleLowerPrioRequested_ISig 7;
BA_ "NeedsUpdateBit" SG_ 537 FirstAxleLowerPrioRequested_ISig 1;
BA_ "SystemSignalLongSymbol" SG_ 537 FirstAxleLowerPrioRequested_ISig "FirstAxleLowerPrioRequested_ISig_6";
BA_ "GenSigSendType" SG_ 537 LiftAxle1AutoLiftRequest_UB_ISig 7;
BA_ "Platform_VMCU1_Sig" SG_ 537 LiftAxle1AutoLiftRequest_UB_ISig 1;
BA_ "SystemSignalLongSymbol" SG_ 537 LiftAxle1AutoLiftRequest_UB_ISig "LiftAxle1AutoLiftRequest_UB_ISig_6";
BA_ "GenSigCycleTime" SG_ 537 BBSystemSpeedDepDriveLevelReq_IS 100;
BA_ "GenSigCycleTimeActive" SG_ 537 BBSystemSpeedDepDriveLevelReq_IS 100;
BA_ "GenSigStartValue" SG_ 537 BBSystemSpeedDepDriveLevelReq_IS 3;
BA_ "Platform_VMCU1_Sig" SG_ 537 BBSystemSpeedDepDriveLevelReq_IS 1;
BA_ "SystemSignalLongSymbol" SG_ 537 BBSystemSpeedDepDriveLevelReq_IS "BBSystemSpeedDepDriveLevelReq_ISig_6";
BA_ "GenSigSendType" SG_ 537 LiftAxle1LiftPositionRequest_UB_ 7;
BA_ "Platform_VMCU1_Sig" SG_ 537 LiftAxle1LiftPositionRequest_UB_ 1;
BA_ "SystemSignalLongSymbol" SG_ 537 LiftAxle1LiftPositionRequest_UB_ "LiftAxle1LiftPositionRequest_UB_ISig_6";
BA_ "GenSigSendType" SG_ 537 LoadDistributionChangeRequest_UB 7;
BA_ "Platform_VMCU1_Sig" SG_ 537 LoadDistributionChangeRequest_UB 1;
BA_ "SystemSignalLongSymbol" SG_ 537 LoadDistributionChangeRequest_UB "LoadDistributionChangeRequest_UB_ISig_6";
BA_ "GenSigCycleTime" SG_ 537 LoadDistributionChangeRequest_IS 100;
BA_ "GenSigCycleTimeActive" SG_ 537 LoadDistributionChangeRequest_IS 100;
BA_ "GenSigStartValue" SG_ 537 LoadDistributionChangeRequest_IS 3;
BA_ "GenSigMaxLatency" SG_ 537 LoadDistributionChangeRequest_IS 29;
BA_ "NeedsUpdateBit" SG_ 537 LoadDistributionChangeRequest_IS 1;
BA_ "Platform_VMCU1_Sig" SG_ 537 LoadDistributionChangeRequest_IS 1;
BA_ "SeToolAncestorID_SIGNAL" SG_ 537 LoadDistributionChangeRequest_IS "x0000001D04176D2B";
BA_ "SeToolItemID_SIGNAL" SG_ 537 LoadDistributionChangeRequest_IS "x0000001D04176D2B";
BA_ "SeToolName_SIGNAL" SG_ 537 LoadDistributionChangeRequest_IS "LoadDistributionChangeRequest";
BA_ "SeToolVersion_SIGNAL" SG_ 537 LoadDistributionChangeRequest_IS "1";
BA_ "SystemSignalLongSymbol" SG_ 537 LoadDistributionChangeRequest_IS "LoadDistributionChangeRequest_ISig_6";
BA_ "GenSigSendType" SG_ 537 BBSystemAlternatLoadDistribReq_U 7;
BA_ "Platform_VMCU1_Sig" SG_ 537 BBSystemAlternatLoadDistribReq_U 1;
BA_ "SystemSignalLongSymbol" SG_ 537 BBSystemAlternatLoadDistribReq_U "BBSystemAlternatLoadDistribReq_UB_ISig_6";
BA_ "GenSigCycleTime" SG_ 537 BBSystemKneelRequest_ISig_6 100;
BA_ "GenSigCycleTimeActive" SG_ 537 BBSystemKneelRequest_ISig_6 100;
BA_ "GenSigStartValue" SG_ 537 BBSystemKneelRequest_ISig_6 3;
BA_ "Platform_VMCU1_Sig" SG_ 537 BBSystemKneelRequest_ISig_6 1;
BA_ "GenSigCycleTime" SG_ 537 LiftAxle1LiftPositionRequest_ISi 100;
BA_ "GenSigCycleTimeActive" SG_ 537 LiftAxle1LiftPositionRequest_ISi 100;
BA_ "GenSigStartValue" SG_ 537 LiftAxle1LiftPositionRequest_ISi 7;
BA_ "GenSigMaxLatency" SG_ 537 LiftAxle1LiftPositionRequest_ISi 29;
BA_ "NeedsUpdateBit" SG_ 537 LiftAxle1LiftPositionRequest_ISi 1;
BA_ "Platform_VMCU1_Sig" SG_ 537 LiftAxle1LiftPositionRequest_ISi 1;
BA_ "SeToolAncestorID_SIGNAL" SG_ 537 LiftAxle1LiftPositionRequest_ISi "x0000001D04176891";
BA_ "SeToolItemID_SIGNAL" SG_ 537 LiftAxle1LiftPositionRequest_ISi "x0000001D04176891";
BA_ "SeToolName_SIGNAL" SG_ 537 LiftAxle1LiftPositionRequest_ISi "LiftAxle1LiftPositionRequest";
BA_ "SeToolVersion_SIGNAL" SG_ 537 LiftAxle1LiftPositionRequest_ISi "1";
BA_ "SystemSignalLongSymbol" SG_ 537 LiftAxle1LiftPositionRequest_ISi "LiftAxle1LiftPositionRequest_ISig_6";
BA_ "GenSigCycleTime" SG_ 537 LiftAxle2AutoLiftRequest_ISig_6 100;
BA_ "GenSigCycleTimeActive" SG_ 537 LiftAxle2AutoLiftRequest_ISig_6 100;
BA_ "GenSigStartValue" SG_ 537 LiftAxle2AutoLiftRequest_ISig_6 3;
BA_ "GenSigMaxLatency" SG_ 537 LiftAxle2AutoLiftRequest_ISig_6 29;
BA_ "NeedsUpdateBit" SG_ 537 LiftAxle2AutoLiftRequest_ISig_6 1;
BA_ "Platform_VMCU1_Sig" SG_ 537 LiftAxle2AutoLiftRequest_ISig_6 1;
BA_ "SeToolAncestorID_SIGNAL" SG_ 537 LiftAxle2AutoLiftRequest_ISig_6 "x0000001D0417683F";
BA_ "SeToolItemID_SIGNAL" SG_ 537 LiftAxle2AutoLiftRequest_ISig_6 "x0000001D0417683F";
BA_ "SeToolName_SIGNAL" SG_ 537 LiftAxle2AutoLiftRequest_ISig_6 "LiftAxle2AutoLiftRequest";
BA_ "SeToolVersion_SIGNAL" SG_ 537 LiftAxle2AutoLiftRequest_ISig_6 "1";
BA_ "GenSigCycleTime" SG_ 537 StopLevelChangeRequest_ISig_6 100;
BA_ "GenSigCycleTimeActive" SG_ 537 StopLevelChangeRequest_ISig_6 100;
BA_ "GenSigStartValue" SG_ 537 StopLevelChangeRequest_ISig_6 3;
BA_ "GenSigMaxLatency" SG_ 537 StopLevelChangeRequest_ISig_6 29;
BA_ "Platform_VMCU1_Sig" SG_ 537 StopLevelChangeRequest_ISig_6 1;
BA_ "SeToolAncestorID_SIGNAL" SG_ 537 StopLevelChangeRequest_ISig_6 "x0000001D041301E9";
BA_ "SeToolItemID_SIGNAL" SG_ 537 StopLevelChangeRequest_ISig_6 "x0000001D041301E9";
BA_ "SeToolName_SIGNAL" SG_ 537 StopLevelChangeRequest_ISig_6 "StopLevelChangeRequest";
BA_ "SeToolVersion_SIGNAL" SG_ 537 StopLevelChangeRequest_ISig_6 "1";
BA_ "GenSigCycleTime" SG_ 537 RideHeightStorageRequest_ISig_6 100;
BA_ "GenSigCycleTimeActive" SG_ 537 RideHeightStorageRequest_ISig_6 100;
BA_ "GenSigStartValue" SG_ 537 RideHeightStorageRequest_ISig_6 15;
BA_ "GenSigMaxLatency" SG_ 537 RideHeightStorageRequest_ISig_6 29;
BA_ "Platform_VMCU1_Sig" SG_ 537 RideHeightStorageRequest_ISig_6 1;
BA_ "SeToolAncestorID_SIGNAL" SG_ 537 RideHeightStorageRequest_ISig_6 "x0000001D041302B5";
BA_ "SeToolItemID_SIGNAL" SG_ 537 RideHeightStorageRequest_ISig_6 "x0000001D041302B5";
BA_ "SeToolName_SIGNAL" SG_ 537 RideHeightStorageRequest_ISig_6 "RideHeightStorageRequest";
BA_ "SeToolVersion_SIGNAL" SG_ 537 RideHeightStorageRequest_ISig_6 "1";
BA_ "GenSigCycleTime" SG_ 537 RampLevelRequest_ISig_6 100;
BA_ "GenSigCycleTimeActive" SG_ 537 RampLevelRequest_ISig_6 100;
BA_ "GenSigStartValue" SG_ 537 RampLevelRequest_ISig_6 15;
BA_ "GenSigMaxLatency" SG_ 537 RampLevelRequest_ISig_6 29;
BA_ "Platform_VMCU1_Sig" SG_ 537 RampLevelRequest_ISig_6 1;
BA_ "SeToolAncestorID_SIGNAL" SG_ 537 RampLevelRequest_ISig_6 "x0000001D041301DB";
BA_ "SeToolItemID_SIGNAL" SG_ 537 RampLevelRequest_ISig_6 "x0000001D041301DB";
BA_ "SeToolName_SIGNAL" SG_ 537 RampLevelRequest_ISig_6 "RampLevelRequest";
BA_ "SeToolVersion_SIGNAL" SG_ 537 RampLevelRequest_ISig_6 "1";
BA_ "GenSigCycleTime" SG_ 537 LiftAxle1AutoLiftRequest_ISig_6 100;
BA_ "GenSigCycleTimeActive" SG_ 537 LiftAxle1AutoLiftRequest_ISig_6 100;
BA_ "GenSigStartValue" SG_ 537 LiftAxle1AutoLiftRequest_ISig_6 3;
BA_ "GenSigMaxLatency" SG_ 537 LiftAxle1AutoLiftRequest_ISig_6 29;
BA_ "NeedsUpdateBit" SG_ 537 LiftAxle1AutoLiftRequest_ISig_6 1;
BA_ "Platform_VMCU1_Sig" SG_ 537 LiftAxle1AutoLiftRequest_ISig_6 1;
BA_ "SeToolAncestorID_SIGNAL" SG_ 537 LiftAxle1AutoLiftRequest_ISig_6 "x0000001D0417688D";
BA_ "SeToolItemID_SIGNAL" SG_ 537 LiftAxle1AutoLiftRequest_ISig_6 "x0000001D0417688D";
BA_ "SeToolName_SIGNAL" SG_ 537 LiftAxle1AutoLiftRequest_ISig_6 "LiftAxle1AutoLiftRequest";
BA_ "SeToolVersion_SIGNAL" SG_ 537 LiftAxle1AutoLiftRequest_ISig_6 "1";
BA_ "GenSigSendType" SG_ 537 FirstAxleLowerPrioRequested_UB_I 7;
BA_ "SystemSignalLongSymbol" SG_ 537 FirstAxleLowerPrioRequested_UB_I "FirstAxleLowerPrioRequested_UB_ISig_6";
BA_ "GenSigSendType" SG_ 537 LiftAxle2AutoLiftRequest_UB_ISig 7;
BA_ "Platform_VMCU1_Sig" SG_ 537 LiftAxle2AutoLiftRequest_UB_ISig 1;
BA_ "SystemSignalLongSymbol" SG_ 537 LiftAxle2AutoLiftRequest_UB_ISig "LiftAxle2AutoLiftRequest_UB_ISig_6";
BA_ "GenSigSendType" SG_ 537 AltLoadDistribution_rqst_UB_ISig 7;
BA_ "Platform_VMCU1_Sig" SG_ 537 AltLoadDistribution_rqst_UB_ISig 1;
BA_ "SystemSignalLongSymbol" SG_ 537 AltLoadDistribution_rqst_UB_ISig "AltLoadDistribution_rqst_UB_ISig_6";
BA_ "GenSigSendType" SG_ 537 LiftAxle2LiftPositionRequest_UB_ 7;
BA_ "Platform_VMCU1_Sig" SG_ 537 LiftAxle2LiftPositionRequest_UB_ 1;
BA_ "SystemSignalLongSymbol" SG_ 537 LiftAxle2LiftPositionRequest_UB_ "LiftAxle2LiftPositionRequest_UB_ISig_6";
BA_ "GenSigSendType" SG_ 537 FerryFunctionRequest_UB_ISig_6 7;
BA_ "Platform_VMCU1_Sig" SG_ 537 FerryFunctionRequest_UB_ISig_6 1;
BA_ "GenSigCycleTime" SG_ 537 LiftAxle2LiftPositionRequest_ISi 100;
BA_ "GenSigCycleTimeActive" SG_ 537 LiftAxle2LiftPositionRequest_ISi 100;
BA_ "GenSigStartValue" SG_ 537 LiftAxle2LiftPositionRequest_ISi 7;
BA_ "GenSigMaxLatency" SG_ 537 LiftAxle2LiftPositionRequest_ISi 29;
BA_ "NeedsUpdateBit" SG_ 537 LiftAxle2LiftPositionRequest_ISi 1;
BA_ "Platform_VMCU1_Sig" SG_ 537 LiftAxle2LiftPositionRequest_ISi 1;
BA_ "SeToolAncestorID_SIGNAL" SG_ 537 LiftAxle2LiftPositionRequest_ISi "x0000001D0417683A";
BA_ "SeToolItemID_SIGNAL" SG_ 537 LiftAxle2LiftPositionRequest_ISi "x0000001D0417683A";
BA_ "SeToolName_SIGNAL" SG_ 537 LiftAxle2LiftPositionRequest_ISi "LiftAxle2LiftPositionRequest";
BA_ "SeToolVersion_SIGNAL" SG_ 537 LiftAxle2LiftPositionRequest_ISi "1";
BA_ "SystemSignalLongSymbol" SG_ 537 LiftAxle2LiftPositionRequest_ISi "LiftAxle2LiftPositionRequest_ISig_6";
BA_ "GenSigSendType" SG_ 531 TrailerBrakePres_rqst_UB 7;
BA_ "Platform_VMCU1_Sig" SG_ 531 TrailerBrakePres_rqst_UB 1;
BA_ "GenSigSendType" SG_ 531 GearLeverPosition_UB_ISig_6 7;
BA_ "Platform_VMCU1_Sig" SG_ 531 GearLeverPosition_UB_ISig_6 1;
BA_ "GenSigCycleTime" SG_ 531 WS_Washing_cmd 100;
BA_ "GenSigCycleTimeActive" SG_ 531 WS_Washing_cmd 100;
BA_ "GenSigStartValue" SG_ 531 WS_Washing_cmd 3;
BA_ "GenSigMaxLatency" SG_ 531 WS_Washing_cmd 24;
BA_ "Platform_VMCU1_Sig" SG_ 531 WS_Washing_cmd 1;
BA_ "SeToolAncestorID_SIGNAL" SG_ 531 WS_Washing_cmd "x0000001D04104F87";
BA_ "SeToolItemID_SIGNAL" SG_ 531 WS_Washing_cmd "x0000001D041CE4A4";
BA_ "SeToolName_SIGNAL" SG_ 531 WS_Washing_cmd "WS_Washing_cmd";
BA_ "SeToolVersion_SIGNAL" SG_ 531 WS_Washing_cmd "2";
BA_ "GenSigCycleTime" SG_ 531 FrAxleDiffLockActvnDriverRqst_IS 100;
BA_ "GenSigCycleTimeActive" SG_ 531 FrAxleDiffLockActvnDriverRqst_IS 100;
BA_ "GenSigStartValue" SG_ 531 FrAxleDiffLockActvnDriverRqst_IS 3;
BA_ "GenSigMaxLatency" SG_ 531 FrAxleDiffLockActvnDriverRqst_IS 35;
BA_ "NeedsUpdateBit" SG_ 531 FrAxleDiffLockActvnDriverRqst_IS 1;
BA_ "Platform_VMCU1_Sig" SG_ 531 FrAxleDiffLockActvnDriverRqst_IS 1;
BA_ "SystemSignalLongSymbol" SG_ 531 FrAxleDiffLockActvnDriverRqst_IS "FrAxleDiffLockActvnDriverRqst_ISig_6";
BA_ "GenSigCycleTime" SG_ 531 FuncIndIlluminationLevel_ISig_6 100;
BA_ "GenSigCycleTimeActive" SG_ 531 FuncIndIlluminationLevel_ISig_6 100;
BA_ "GenSigStartValue" SG_ 531 FuncIndIlluminationLevel_ISig_6 1;
BA_ "GenSigMaxLatency" SG_ 531 FuncIndIlluminationLevel_ISig_6 24;
BA_ "Platform_VMCU1_Sig" SG_ 531 FuncIndIlluminationLevel_ISig_6 1;
BA_ "SeToolAncestorID_SIGNAL" SG_ 531 FuncIndIlluminationLevel_ISig_6 "x0000001D043A8396";
BA_ "SeToolItemID_SIGNAL" SG_ 531 FuncIndIlluminationLevel_ISig_6 "x0000001D043A8396";
BA_ "SeToolName_SIGNAL" SG_ 531 FuncIndIlluminationLevel_ISig_6 "FuncIndIlluminationLevel";
BA_ "SeToolVersion_SIGNAL" SG_ 531 FuncIndIlluminationLevel_ISig_6 "1";
BA_ "GenSigCycleTime" SG_ 531 TrailerBrakePres_rqst 100;
BA_ "GenSigCycleTimeActive" SG_ 531 TrailerBrakePres_rqst 100;
BA_ "GenSigStartValue" SG_ 531 TrailerBrakePres_rqst 255;
BA_ "GenSigMaxLatency" SG_ 531 TrailerBrakePres_rqst 35;
BA_ "NeedsUpdateBit" SG_ 531 TrailerBrakePres_rqst 1;
BA_ "Platform_VMCU1_Sig" SG_ 531 TrailerBrakePres_rqst 1;
BA_ "GenSigCycleTime" SG_ 531 ASREngineControlActive_ISig_6 100;
BA_ "GenSigCycleTimeActive" SG_ 531 ASREngineControlActive_ISig_6 100;
BA_ "GenSigStartValue" SG_ 531 ASREngineControlActive_ISig_6 3;
BA_ "NeedsUpdateBit" SG_ 531 ASREngineControlActive_ISig_6 1;
BA_ "Platform_VMCU1_Sig" SG_ 531 ASREngineControlActive_ISig_6 1;
BA_ "SeToolAncestorID_SIGNAL" SG_ 531 ASREngineControlActive_ISig_6 "x0000001D04125C4F";
BA_ "SeToolItemID_SIGNAL" SG_ 531 ASREngineControlActive_ISig_6 "x0000001D04125C4F";
BA_ "SeToolName_SIGNAL" SG_ 531 ASREngineControlActive_ISig_6 "ASREngineControlActive";
BA_ "SeToolVersion_SIGNAL" SG_ 531 ASREngineControlActive_ISig_6 "1";
BA_ "GenSigCycleTime" SG_ 531 TransmissionDrivelineEngaged_ISi 100;
BA_ "GenSigCycleTimeActive" SG_ 531 TransmissionDrivelineEngaged_ISi 100;
BA_ "GenSigStartValue" SG_ 531 TransmissionDrivelineEngaged_ISi 3;
BA_ "GenSigMaxLatency" SG_ 531 TransmissionDrivelineEngaged_ISi 24;
BA_ "NeedsUpdateBit" SG_ 531 TransmissionDrivelineEngaged_ISi 1;
BA_ "Platform_VMCU1_Sig" SG_ 531 TransmissionDrivelineEngaged_ISi 1;
BA_ "SeToolAncestorID_SIGNAL" SG_ 531 TransmissionDrivelineEngaged_ISi "x0000001D0410CEC8";
BA_ "SeToolItemID_SIGNAL" SG_ 531 TransmissionDrivelineEngaged_ISi "x0000001D0410CEC8";
BA_ "SeToolName_SIGNAL" SG_ 531 TransmissionDrivelineEngaged_ISi "TransmissionDrivelineEngaged";
BA_ "SeToolVersion_SIGNAL" SG_ 531 TransmissionDrivelineEngaged_ISi "1";
BA_ "SystemSignalLongSymbol" SG_ 531 TransmissionDrivelineEngaged_ISi "TransmissionDrivelineEngaged_ISig_6";
BA_ "GenSigCycleTime" SG_ 531 ReverseWarning_rqst_ISig_6 100;
BA_ "GenSigCycleTimeActive" SG_ 531 ReverseWarning_rqst_ISig_6 100;
BA_ "GenSigStartValue" SG_ 531 ReverseWarning_rqst_ISig_6 3;
BA_ "GenSigMaxLatency" SG_ 531 ReverseWarning_rqst_ISig_6 24;
BA_ "Platform_VMCU1_Sig" SG_ 531 ReverseWarning_rqst_ISig_6 1;
BA_ "SeToolAncestorID_SIGNAL" SG_ 531 ReverseWarning_rqst_ISig_6 "x0000001D042783B3";
BA_ "SeToolItemID_SIGNAL" SG_ 531 ReverseWarning_rqst_ISig_6 "x0000001D042783B3";
BA_ "SeToolName_SIGNAL" SG_ 531 ReverseWarning_rqst_ISig_6 "ReverseWarning_rqst";
BA_ "SeToolVersion_SIGNAL" SG_ 531 ReverseWarning_rqst_ISig_6 "1";
BA_ "GenSigSendType" SG_ 531 ASREngineControlActive_UB_ISig_6 7;
BA_ "Platform_VMCU1_Sig" SG_ 531 ASREngineControlActive_UB_ISig_6 1;
BA_ "GenSigSendType" SG_ 531 SplitBoxDifflockActvnDrvrRqst_UB 7;
BA_ "Platform_VMCU1_Sig" SG_ 531 SplitBoxDifflockActvnDrvrRqst_UB 1;
BA_ "SystemSignalLongSymbol" SG_ 531 SplitBoxDifflockActvnDrvrRqst_UB "SplitBoxDifflockActvnDrvrRqst_UB_ISig_6";
BA_ "GenSigCycleTime" SG_ 531 FogLight_Rear_cmd 100;
BA_ "GenSigCycleTimeActive" SG_ 531 FogLight_Rear_cmd 100;
BA_ "GenSigStartValue" SG_ 531 FogLight_Rear_cmd 3;
BA_ "GenSigMaxLatency" SG_ 531 FogLight_Rear_cmd 24;
BA_ "Platform_VMCU1_Sig" SG_ 531 FogLight_Rear_cmd 1;
BA_ "SeToolAncestorID_SIGNAL" SG_ 531 FogLight_Rear_cmd "x0000001D04135258";
BA_ "SeToolItemID_SIGNAL" SG_ 531 FogLight_Rear_cmd "x0000001D04384FF9";
BA_ "SeToolName_SIGNAL" SG_ 531 FogLight_Rear_cmd "FogLight_Rear_cmd";
BA_ "SeToolVersion_SIGNAL" SG_ 531 FogLight_Rear_cmd "2";
BA_ "GenSigCycleTime" SG_ 531 FogLight_Front_cmd_ISig_6 100;
BA_ "GenSigCycleTimeActive" SG_ 531 FogLight_Front_cmd_ISig_6 100;
BA_ "GenSigStartValue" SG_ 531 FogLight_Front_cmd_ISig_6 3;
BA_ "GenSigMaxLatency" SG_ 531 FogLight_Front_cmd_ISig_6 24;
BA_ "Platform_VMCU1_Sig" SG_ 531 FogLight_Front_cmd_ISig_6 1;
BA_ "SeToolAncestorID_SIGNAL" SG_ 531 FogLight_Front_cmd_ISig_6 "x0000001D04135140";
BA_ "SeToolItemID_SIGNAL" SG_ 531 FogLight_Front_cmd_ISig_6 "x0000001D04384FD1";
BA_ "SeToolName_SIGNAL" SG_ 531 FogLight_Front_cmd_ISig_6 "FogLight_Front_cmd";
BA_ "SeToolVersion_SIGNAL" SG_ 531 FogLight_Front_cmd_ISig_6 "2";
BA_ "GenSigSendType" SG_ 531 ASRBrakeControlActive_UB_ISig_6 7;
BA_ "Platform_VMCU1_Sig" SG_ 531 ASRBrakeControlActive_UB_ISig_6 1;
BA_ "GenSigSendType" SG_ 531 TransmissionDrivelineEngaged_UB_ 7;
BA_ "Platform_VMCU1_Sig" SG_ 531 TransmissionDrivelineEngaged_UB_ 1;
BA_ "SystemSignalLongSymbol" SG_ 531 TransmissionDrivelineEngaged_UB_ "TransmissionDrivelineEngaged_UB_ISig_6";
BA_ "GenSigCycleTime" SG_ 531 SplitBoxDifflockActvnDrvrRqst_IS 100;
BA_ "GenSigCycleTimeActive" SG_ 531 SplitBoxDifflockActvnDrvrRqst_IS 100;
BA_ "GenSigStartValue" SG_ 531 SplitBoxDifflockActvnDrvrRqst_IS 3;
BA_ "GenSigMaxLatency" SG_ 531 SplitBoxDifflockActvnDrvrRqst_IS 35;
BA_ "NeedsUpdateBit" SG_ 531 SplitBoxDifflockActvnDrvrRqst_IS 1;
BA_ "Platform_VMCU1_Sig" SG_ 531 SplitBoxDifflockActvnDrvrRqst_IS 1;
BA_ "SystemSignalLongSymbol" SG_ 531 SplitBoxDifflockActvnDrvrRqst_IS "SplitBoxDifflockActvnDrvrRqst_ISig_6";
BA_ "GenSigCycleTime" SG_ 531 AntiLockBrakingActive_ISig_6 100;
BA_ "GenSigCycleTimeActive" SG_ 531 AntiLockBrakingActive_ISig_6 100;
BA_ "GenSigStartValue" SG_ 531 AntiLockBrakingActive_ISig_6 3;
BA_ "GenSigMaxLatency" SG_ 531 AntiLockBrakingActive_ISig_6 24;
BA_ "Platform_VMCU1_Sig" SG_ 531 AntiLockBrakingActive_ISig_6 1;
BA_ "SeToolAncestorID_SIGNAL" SG_ 531 AntiLockBrakingActive_ISig_6 "x0000001D0410DB7B";
BA_ "SeToolItemID_SIGNAL" SG_ 531 AntiLockBrakingActive_ISig_6 "x0000001D0410DB7B";
BA_ "SeToolName_SIGNAL" SG_ 531 AntiLockBrakingActive_ISig_6 "Anti-LockBraking(ABS)Active";
BA_ "SeToolVersion_SIGNAL" SG_ 531 AntiLockBrakingActive_ISig_6 "1";
BA_ "GenSigCycleTime" SG_ 531 ASRBrakeControlActive_ISig_6 100;
BA_ "GenSigCycleTimeActive" SG_ 531 ASRBrakeControlActive_ISig_6 100;
BA_ "GenSigStartValue" SG_ 531 ASRBrakeControlActive_ISig_6 3;
BA_ "GenSigMaxLatency" SG_ 531 ASRBrakeControlActive_ISig_6 24;
BA_ "NeedsUpdateBit" SG_ 531 ASRBrakeControlActive_ISig_6 1;
BA_ "Platform_VMCU1_Sig" SG_ 531 ASRBrakeControlActive_ISig_6 1;
BA_ "SeToolAncestorID_SIGNAL" SG_ 531 ASRBrakeControlActive_ISig_6 "x0000001D04125C74";
BA_ "SeToolItemID_SIGNAL" SG_ 531 ASRBrakeControlActive_ISig_6 "x0000001D04125C74";
BA_ "SeToolName_SIGNAL" SG_ 531 ASRBrakeControlActive_ISig_6 "ASRBrakeControlActive";
BA_ "SeToolVersion_SIGNAL" SG_ 531 ASRBrakeControlActive_ISig_6 "1";
BA_ "GenSigCycleTime" SG_ 531 GearLeverPosition_ISig_6 100;
BA_ "GenSigCycleTimeActive" SG_ 531 GearLeverPosition_ISig_6 100;
BA_ "GenSigStartValue" SG_ 531 GearLeverPosition_ISig_6 15;
BA_ "GenSigMaxLatency" SG_ 531 GearLeverPosition_ISig_6 24;
BA_ "NeedsUpdateBit" SG_ 531 GearLeverPosition_ISig_6 1;
BA_ "Platform_VMCU1_Sig" SG_ 531 GearLeverPosition_ISig_6 1;
BA_ "SeToolAncestorID_SIGNAL" SG_ 531 GearLeverPosition_ISig_6 "x0000001D0412B683";
BA_ "SeToolItemID_SIGNAL" SG_ 531 GearLeverPosition_ISig_6 "x0000001D0412B683";
BA_ "SeToolName_SIGNAL" SG_ 531 GearLeverPosition_ISig_6 "GearLeverPosition";
BA_ "SeToolVersion_SIGNAL" SG_ 531 GearLeverPosition_ISig_6 "1";
BA_ "GenSigCycleTime" SG_ 531 ClutchPedalPosition_ISig_6 100;
BA_ "GenSigCycleTimeActive" SG_ 531 ClutchPedalPosition_ISig_6 100;
BA_ "GenSigStartValue" SG_ 531 ClutchPedalPosition_ISig_6 255;
BA_ "GenSigMaxLatency" SG_ 531 ClutchPedalPosition_ISig_6 35;
BA_ "Platform_VMCU1_Sig" SG_ 531 ClutchPedalPosition_ISig_6 1;
BA_ "GenSigSendType" SG_ 531 TransmissionShiftInProcess_UB_IS 7;
BA_ "Platform_VMCU1_Sig" SG_ 531 TransmissionShiftInProcess_UB_IS 1;
BA_ "SystemSignalLongSymbol" SG_ 531 TransmissionShiftInProcess_UB_IS "TransmissionShiftInProcess_UB_ISig_6";
BA_ "GenSigCycleTime" SG_ 531 BackToDriveReq_ISig_6 100;
BA_ "GenSigCycleTimeActive" SG_ 531 BackToDriveReq_ISig_6 100;
BA_ "GenSigStartValue" SG_ 531 BackToDriveReq_ISig_6 3;
BA_ "Platform_VMCU1_Sig" SG_ 531 BackToDriveReq_ISig_6 1;
BA_ "GenSigSendType" SG_ 531 FrAxleDiffLockActvnDriverRqst_UB 7;
BA_ "Platform_VMCU1_Sig" SG_ 531 FrAxleDiffLockActvnDriverRqst_UB 1;
BA_ "SystemSignalLongSymbol" SG_ 531 FrAxleDiffLockActvnDriverRqst_UB "FrAxleDiffLockActvnDriverRqst_UB_ISig_6";
BA_ "GenSigCycleTime" SG_ 531 TransmissionShiftInProcess_ISig_ 100;
BA_ "GenSigCycleTimeActive" SG_ 531 TransmissionShiftInProcess_ISig_ 100;
BA_ "GenSigStartValue" SG_ 531 TransmissionShiftInProcess_ISig_ 3;
BA_ "GenSigMaxLatency" SG_ 531 TransmissionShiftInProcess_ISig_ 24;
BA_ "NeedsUpdateBit" SG_ 531 TransmissionShiftInProcess_ISig_ 1;
BA_ "Platform_VMCU1_Sig" SG_ 531 TransmissionShiftInProcess_ISig_ 1;
BA_ "SeToolAncestorID_SIGNAL" SG_ 531 TransmissionShiftInProcess_ISig_ "x0000001D0410D0F1";
BA_ "SeToolItemID_SIGNAL" SG_ 531 TransmissionShiftInProcess_ISig_ "x0000001D0410D0F1";
BA_ "SeToolName_SIGNAL" SG_ 531 TransmissionShiftInProcess_ISig_ "TransmissionShiftInProcess";
BA_ "SeToolVersion_SIGNAL" SG_ 531 TransmissionShiftInProcess_ISig_ "1";
BA_ "SystemSignalLongSymbol" SG_ 531 TransmissionShiftInProcess_ISig_ "TransmissionShiftInProcess_ISig_6";
BA_ "GenSigCycleTime" SG_ 531 EngineTorqueMode_ISig_6 100;
BA_ "GenSigCycleTimeActive" SG_ 531 EngineTorqueMode_ISig_6 100;
BA_ "GenSigStartValue" SG_ 531 EngineTorqueMode_ISig_6 15;
BA_ "GenSigMaxLatency" SG_ 531 EngineTorqueMode_ISig_6 24;
BA_ "Platform_VMCU1_Sig" SG_ 531 EngineTorqueMode_ISig_6 1;
BA_ "SeToolAncestorID_SIGNAL" SG_ 531 EngineTorqueMode_ISig_6 "x0000001D0414E4FD";
BA_ "SeToolItemID_SIGNAL" SG_ 531 EngineTorqueMode_ISig_6 "x0000001D0414E4FD";
BA_ "SeToolName_SIGNAL" SG_ 531 EngineTorqueMode_ISig_6 "EngineTorqueMode";
BA_ "SeToolVersion_SIGNAL" SG_ 531 EngineTorqueMode_ISig_6 "1";
BA_ "GenSigCycleTime" SG_ 392 WorkingLightChassisOutp_cmd 100;
BA_ "GenSigCycleTimeActive" SG_ 392 WorkingLightChassisOutp_cmd 100;
BA_ "GenSigStartValue" SG_ 392 WorkingLightChassisOutp_cmd 3;
BA_ "Platform_VMCU1_Sig" SG_ 392 WorkingLightChassisOutp_cmd 1;
BA_ "GenSigCycleTime" SG_ 392 PositionLight_cmd 100;
BA_ "GenSigCycleTimeActive" SG_ 392 PositionLight_cmd 100;
BA_ "GenSigStartValue" SG_ 392 PositionLight_cmd 3;
BA_ "GenSigMaxLatency" SG_ 392 PositionLight_cmd 24;
BA_ "Platform_VMCU1_Sig" SG_ 392 PositionLight_cmd 1;
BA_ "SeToolAncestorID_SIGNAL" SG_ 392 PositionLight_cmd "x0000001D04135133";
BA_ "SeToolItemID_SIGNAL" SG_ 392 PositionLight_cmd "x0000001D043845D0";
BA_ "SeToolName_SIGNAL" SG_ 392 PositionLight_cmd "PositionLight_cmd";
BA_ "SeToolVersion_SIGNAL" SG_ 392 PositionLight_cmd "2";
BA_ "GenSigCycleTime" SG_ 392 StaticCornerLight_cmd 100;
BA_ "GenSigCycleTimeActive" SG_ 392 StaticCornerLight_cmd 100;
BA_ "GenSigInactiveValue" SG_ 392 StaticCornerLight_cmd 7;
BA_ "GenSigStartValue" SG_ 392 StaticCornerLight_cmd 7;
BA_ "Platform_VMCU1_Sig" SG_ 392 StaticCornerLight_cmd 1;
BA_ "GenSigCycleTime" SG_ 392 ExtraMainBeam_cmd 100;
BA_ "GenSigCycleTimeActive" SG_ 392 ExtraMainBeam_cmd 100;
BA_ "GenSigStartValue" SG_ 392 ExtraMainBeam_cmd 3;
BA_ "GenSigMaxLatency" SG_ 392 ExtraMainBeam_cmd 35;
BA_ "Platform_VMCU1_Sig" SG_ 392 ExtraMainBeam_cmd 1;
BA_ "GenSigCycleTime" SG_ 392 BacklightCmd_ISig_6 100;
BA_ "GenSigCycleTimeActive" SG_ 392 BacklightCmd_ISig_6 100;
BA_ "GenSigMaxLatency" SG_ 392 BacklightCmd_ISig_6 23;
BA_ "Platform_VMCU1_Sig" SG_ 392 BacklightCmd_ISig_6 1;
BA_ "SeToolAncestorID_SIGNAL" SG_ 392 BacklightCmd_ISig_6 "x0000001D0439DDD1";
BA_ "SeToolItemID_SIGNAL" SG_ 392 BacklightCmd_ISig_6 "x0000001D043A84D3";
BA_ "SeToolName_SIGNAL" SG_ 392 BacklightCmd_ISig_6 "BacklightCmd";
BA_ "SeToolVersion_SIGNAL" SG_ 392 BacklightCmd_ISig_6 "2";
BA_ "GenSigCycleTime" SG_ 392 DirectionIndicatorLights_cmd 100;
BA_ "GenSigCycleTimeActive" SG_ 392 DirectionIndicatorLights_cmd 100;
BA_ "GenSigStartValue" SG_ 392 DirectionIndicatorLights_cmd 7;
BA_ "GenSigMaxLatency" SG_ 392 DirectionIndicatorLights_cmd 23;
BA_ "Platform_VMCU1_Sig" SG_ 392 DirectionIndicatorLights_cmd 1;
BA_ "SeToolAncestorID_SIGNAL" SG_ 392 DirectionIndicatorLights_cmd "x0000001D0413510D";
BA_ "SeToolItemID_SIGNAL" SG_ 392 DirectionIndicatorLights_cmd "x0000001D04384501";
BA_ "SeToolName_SIGNAL" SG_ 392 DirectionIndicatorLights_cmd "DirectionIndicatorLights_cmd";
BA_ "SeToolVersion_SIGNAL" SG_ 392 DirectionIndicatorLights_cmd "3";
BA_ "GenSigCycleTime" SG_ 392 DirectionIndicatorLights_rqst 100;
BA_ "GenSigCycleTimeActive" SG_ 392 DirectionIndicatorLights_rqst 100;
BA_ "GenSigStartValue" SG_ 392 DirectionIndicatorLights_rqst 7;
BA_ "GenSigMaxLatency" SG_ 392 DirectionIndicatorLights_rqst 23;
BA_ "Platform_VMCU1_Sig" SG_ 392 DirectionIndicatorLights_rqst 1;
BA_ "SeToolAncestorID_SIGNAL" SG_ 392 DirectionIndicatorLights_rqst "x0000001D04134ABF";
BA_ "SeToolItemID_SIGNAL" SG_ 392 DirectionIndicatorLights_rqst "x0000001D042DB5E8";
BA_ "SeToolName_SIGNAL" SG_ 392 DirectionIndicatorLights_rqst "DirectionIndicatorLights_rqst";
BA_ "SeToolVersion_SIGNAL" SG_ 392 DirectionIndicatorLights_rqst "3";
BA_ "GenSigCycleTime" SG_ 392 DriverEngineShutOff_rqst 100;
BA_ "GenSigCycleTimeActive" SG_ 392 DriverEngineShutOff_rqst 100;
BA_ "GenSigStartValue" SG_ 392 DriverEngineShutOff_rqst 3;
BA_ "Platform_VMCU1_Sig" SG_ 392 DriverEngineShutOff_rqst 1;
BA_ "SeToolAncestorID_SIGNAL" SG_ 392 DriverEngineShutOff_rqst "x0000001D041A825D";
BA_ "SeToolItemID_SIGNAL" SG_ 392 DriverEngineShutOff_rqst "x0000001D041A825D";
BA_ "SeToolName_SIGNAL" SG_ 392 DriverEngineShutOff_rqst "DriverEngineShutOff_rqst";
BA_ "SeToolVersion_SIGNAL" SG_ 392 DriverEngineShutOff_rqst "1";
BA_ "GenSigCycleTime" SG_ 392 DippedBeam_cmd 100;
BA_ "GenSigCycleTimeActive" SG_ 392 DippedBeam_cmd 100;
BA_ "GenSigStartValue" SG_ 392 DippedBeam_cmd 3;
BA_ "GenSigMaxLatency" SG_ 392 DippedBeam_cmd 23;
BA_ "Platform_VMCU1_Sig" SG_ 392 DippedBeam_cmd 1;
BA_ "SeToolAncestorID_SIGNAL" SG_ 392 DippedBeam_cmd "x0000001D04181D37";
BA_ "SeToolItemID_SIGNAL" SG_ 392 DippedBeam_cmd "x0000001D04383E74";
BA_ "SeToolName_SIGNAL" SG_ 392 DippedBeam_cmd "DippedBeam_cmd";
BA_ "SeToolVersion_SIGNAL" SG_ 392 DippedBeam_cmd "2";
BA_ "GenSigCycleTime" SG_ 392 BrakePedalPosition_ISig_6 100;
BA_ "GenSigCycleTimeActive" SG_ 392 BrakePedalPosition_ISig_6 100;
BA_ "GenSigStartValue" SG_ 392 BrakePedalPosition_ISig_6 255;
BA_ "GenSigMaxLatency" SG_ 392 BrakePedalPosition_ISig_6 23;
BA_ "Platform_VMCU1_Sig" SG_ 392 BrakePedalPosition_ISig_6 1;
BA_ "SeToolAncestorID_SIGNAL" SG_ 392 BrakePedalPosition_ISig_6 "x0000001D04104A99";
BA_ "SeToolItemID_SIGNAL" SG_ 392 BrakePedalPosition_ISig_6 "x0000001D04104A99";
BA_ "SeToolName_SIGNAL" SG_ 392 BrakePedalPosition_ISig_6 "BrakePedalPosition";
BA_ "SeToolVersion_SIGNAL" SG_ 392 BrakePedalPosition_ISig_6 "1";
BA_ "GenSigCycleTime" SG_ 392 AcctrPedalKickDownSw_stat_ISig_6 100;
BA_ "GenSigCycleTimeActive" SG_ 392 AcctrPedalKickDownSw_stat_ISig_6 100;
BA_ "GenSigStartValue" SG_ 392 AcctrPedalKickDownSw_stat_ISig_6 3;
BA_ "GenSigMaxLatency" SG_ 392 AcctrPedalKickDownSw_stat_ISig_6 23;
BA_ "Platform_VMCU1_Sig" SG_ 392 AcctrPedalKickDownSw_stat_ISig_6 1;
BA_ "SeToolAncestorID_SIGNAL" SG_ 392 AcctrPedalKickDownSw_stat_ISig_6 "x0000001D0414E38D";
BA_ "SeToolItemID_SIGNAL" SG_ 392 AcctrPedalKickDownSw_stat_ISig_6 "x0000001D0428D480";
BA_ "SeToolName_SIGNAL" SG_ 392 AcctrPedalKickDownSw_stat_ISig_6 "AcceleratorPedalKickDwnSwtchStat";
BA_ "SeToolVersion_SIGNAL" SG_ 392 AcctrPedalKickDownSw_stat_ISig_6 "2";
BA_ "GenSigCycleTime" SG_ 392 HeadLightLevel_cmd 100;
BA_ "GenSigCycleTimeActive" SG_ 392 HeadLightLevel_cmd 100;
BA_ "GenSigStartValue" SG_ 392 HeadLightLevel_cmd 63;
BA_ "Platform_VMCU1_Sig" SG_ 392 HeadLightLevel_cmd 1;
BA_ "GenSigCycleTime" SG_ 392 DRL_cmd 100;
BA_ "GenSigCycleTimeActive" SG_ 392 DRL_cmd 100;
BA_ "GenSigStartValue" SG_ 392 DRL_cmd 3;
BA_ "GenSigMaxLatency" SG_ 392 DRL_cmd 23;
BA_ "Platform_VMCU1_Sig" SG_ 392 DRL_cmd 1;
BA_ "SeToolAncestorID_SIGNAL" SG_ 392 DRL_cmd "x0000001D041811E7";
BA_ "SeToolItemID_SIGNAL" SG_ 392 DRL_cmd "x0000001D04383E67";
BA_ "SeToolName_SIGNAL" SG_ 392 DRL_cmd "DRL_cmd";
BA_ "SeToolVersion_SIGNAL" SG_ 392 DRL_cmd "2";
BA_ "GenSigCycleTime" SG_ 392 AcceleratorPedalLowIdleSwitch_IS 100;
BA_ "GenSigCycleTimeActive" SG_ 392 AcceleratorPedalLowIdleSwitch_IS 100;
BA_ "GenSigStartValue" SG_ 392 AcceleratorPedalLowIdleSwitch_IS 3;
BA_ "GenSigMaxLatency" SG_ 392 AcceleratorPedalLowIdleSwitch_IS 23;
BA_ "Platform_VMCU1_Sig" SG_ 392 AcceleratorPedalLowIdleSwitch_IS 1;
BA_ "SeToolAncestorID_SIGNAL" SG_ 392 AcceleratorPedalLowIdleSwitch_IS "x0000001D0414E508";
BA_ "SeToolItemID_SIGNAL" SG_ 392 AcceleratorPedalLowIdleSwitch_IS "x0000001D0414E508";
BA_ "SeToolName_SIGNAL" SG_ 392 AcceleratorPedalLowIdleSwitch_IS "AcceleratorPedalLowIdleSwitch";
BA_ "SeToolVersion_SIGNAL" SG_ 392 AcceleratorPedalLowIdleSwitch_IS "1";
BA_ "SystemSignalLongSymbol" SG_ 392 AcceleratorPedalLowIdleSwitch_IS "AcceleratorPedalLowIdleSwitch_ISig_6";
BA_ "GenSigCycleTime" SG_ 392 MainBeam_cmd_ISig_6 100;
BA_ "GenSigCycleTimeActive" SG_ 392 MainBeam_cmd_ISig_6 100;
BA_ "GenSigStartValue" SG_ 392 MainBeam_cmd_ISig_6 7;
BA_ "GenSigMaxLatency" SG_ 392 MainBeam_cmd_ISig_6 23;
BA_ "Platform_VMCU1_Sig" SG_ 392 MainBeam_cmd_ISig_6 1;
BA_ "SeToolAncestorID_SIGNAL" SG_ 392 MainBeam_cmd_ISig_6 "x0000001D04134EB4";
BA_ "SeToolItemID_SIGNAL" SG_ 392 MainBeam_cmd_ISig_6 "x0000001D04383E5C";
BA_ "SeToolName_SIGNAL" SG_ 392 MainBeam_cmd_ISig_6 "MainBeam_cmd";
BA_ "SeToolVersion_SIGNAL" SG_ 392 MainBeam_cmd_ISig_6 "4";
BA_ "GenSigCycleTime" SG_ 392 Hazard_rqst_ISig_6 100;
BA_ "GenSigCycleTimeActive" SG_ 392 Hazard_rqst_ISig_6 100;
BA_ "GenSigStartValue" SG_ 392 Hazard_rqst_ISig_6 3;
BA_ "GenSigMaxLatency" SG_ 392 Hazard_rqst_ISig_6 23;
BA_ "Platform_VMCU1_Sig" SG_ 392 Hazard_rqst_ISig_6 1;
BA_ "SeToolAncestorID_SIGNAL" SG_ 392 Hazard_rqst_ISig_6 "x0000001D04134A95";
BA_ "SeToolItemID_SIGNAL" SG_ 392 Hazard_rqst_ISig_6 "x0000001D04134A95";
BA_ "SeToolName_SIGNAL" SG_ 392 Hazard_rqst_ISig_6 "Hazard_rqst";
BA_ "SeToolVersion_SIGNAL" SG_ 392 Hazard_rqst_ISig_6 "1";
BA_ "GenSigCycleTime" SG_ 392 VehicleMode_ISig_6 100;
BA_ "GenSigCycleTimeActive" SG_ 392 VehicleMode_ISig_6 100;
BA_ "GenSigStartValue" SG_ 392 VehicleMode_ISig_6 15;
BA_ "NeedsUpdateBit" SG_ 392 VehicleMode_ISig_6 1;
BA_ "Platform_VMCU1_Sig" SG_ 392 VehicleMode_ISig_6 1;
BA_ "GenSigSendType" SG_ 392 VehicleMode_UB_ISig_6 7;
BA_ "Platform_VMCU1_Sig" SG_ 392 VehicleMode_UB_ISig_6 1;
BA_ "GenSigCycleTime" SG_ 392 AcceleratorPedalPosition1_ISig_6 100;
BA_ "GenSigCycleTimeActive" SG_ 392 AcceleratorPedalPosition1_ISig_6 100;
BA_ "GenSigStartValue" SG_ 392 AcceleratorPedalPosition1_ISig_6 255;
BA_ "GenSigMaxLatency" SG_ 392 AcceleratorPedalPosition1_ISig_6 23;
BA_ "Platform_VMCU1_Sig" SG_ 392 AcceleratorPedalPosition1_ISig_6 1;
BA_ "SeToolAncestorID_SIGNAL" SG_ 392 AcceleratorPedalPosition1_ISig_6 "x0000001D0410BACD";
BA_ "SeToolItemID_SIGNAL" SG_ 392 AcceleratorPedalPosition1_ISig_6 "x0000001D04227E9E";
BA_ "SeToolName_SIGNAL" SG_ 392 AcceleratorPedalPosition1_ISig_6 "AcceleratorPedalPosition1";
BA_ "SeToolVersion_SIGNAL" SG_ 392 AcceleratorPedalPosition1_ISig_6 "2";
BA_ "GenSigSendType" SG_ 2671902706 FuncDiagDataTester_ISig_6 7;
BA_ "Platform_VMCU1_Sig" SG_ 2671902706 FuncDiagDataTester_ISig_6 1;
BA_ "GenSigCycleTime" SG_ 1248 TPMMateTrailerResp_ISig_6 100;
BA_ "GenSigCycleTimeActive" SG_ 1248 TPMMateTrailerResp_ISig_6 100;
BA_ "GenSigStartValue" SG_ 1248 TPMMateTrailerResp_ISig_6 7;
BA_ "NeedsUpdateBit" SG_ 1248 TPMMateTrailerResp_ISig_6 1;
BA_ "Platform_VMCU1_Sig" SG_ 1248 TPMMateTrailerResp_ISig_6 1;
BA_ "GenSigSendType" SG_ 1248 Trailer2TPMLeakageWarning_UB_ISi 7;
BA_ "GenSigCycleTime" SG_ 1248 Trailer2TPMLeakageWarning_UB_ISi 100;
BA_ "GenSigCycleTimeActive" SG_ 1248 Trailer2TPMLeakageWarning_UB_ISi 100;
BA_ "Platform_VMCU1_Sig" SG_ 1248 Trailer2TPMLeakageWarning_UB_ISi 1;
BA_ "SystemSignalLongSymbol" SG_ 1248 Trailer2TPMLeakageWarning_UB_ISi "Trailer2TPMLeakageWarning_UB_ISig_6";
BA_ "GenSigSendType" SG_ 1248 TruckTPMPressureWarning_UB_ISig_ 7;
BA_ "GenSigCycleTime" SG_ 1248 TruckTPMPressureWarning_UB_ISig_ 100;
BA_ "GenSigCycleTimeActive" SG_ 1248 TruckTPMPressureWarning_UB_ISig_ 100;
BA_ "Platform_VMCU1_Sig" SG_ 1248 TruckTPMPressureWarning_UB_ISig_ 1;
BA_ "SystemSignalLongSymbol" SG_ 1248 TruckTPMPressureWarning_UB_ISig_ "TruckTPMPressureWarning_UB_ISig_6";
BA_ "GenSigCycleTime" SG_ 1248 TPMAutomaticMating_ISig_6 100;
BA_ "GenSigCycleTimeActive" SG_ 1248 TPMAutomaticMating_ISig_6 100;
BA_ "GenSigStartValue" SG_ 1248 TPMAutomaticMating_ISig_6 3;
BA_ "Platform_VMCU1_Sig" SG_ 1248 TPMAutomaticMating_ISig_6 1;
BA_ "GenSigCycleTime" SG_ 1248 Trailer1TPMPressureWarning_ISig_ 100;
BA_ "GenSigCycleTimeActive" SG_ 1248 Trailer1TPMPressureWarning_ISig_ 100;
BA_ "GenSigStartValue" SG_ 1248 Trailer1TPMPressureWarning_ISig_ 7;
BA_ "NeedsUpdateBit" SG_ 1248 Trailer1TPMPressureWarning_ISig_ 1;
BA_ "Platform_VMCU1_Sig" SG_ 1248 Trailer1TPMPressureWarning_ISig_ 1;
BA_ "SystemSignalLongSymbol" SG_ 1248 Trailer1TPMPressureWarning_ISig_ "Trailer1TPMPressureWarning_ISig_6";
BA_ "GenSigSendType" SG_ 1248 Trailer1TPMPressureWarning_UB_IS 7;
BA_ "GenSigCycleTime" SG_ 1248 Trailer1TPMPressureWarning_UB_IS 100;
BA_ "GenSigCycleTimeActive" SG_ 1248 Trailer1TPMPressureWarning_UB_IS 100;
BA_ "Platform_VMCU1_Sig" SG_ 1248 Trailer1TPMPressureWarning_UB_IS 1;
BA_ "SystemSignalLongSymbol" SG_ 1248 Trailer1TPMPressureWarning_UB_IS "Trailer1TPMPressureWarning_UB_ISig_6";
BA_ "GenSigSendType" SG_ 1248 TPMMateTrailerResp_UB_ISig_6 7;
BA_ "GenSigCycleTime" SG_ 1248 TPMMateTrailerResp_UB_ISig_6 100;
BA_ "GenSigCycleTimeActive" SG_ 1248 TPMMateTrailerResp_UB_ISig_6 100;
BA_ "Platform_VMCU1_Sig" SG_ 1248 TPMMateTrailerResp_UB_ISig_6 1;
BA_ "GenSigSendType" SG_ 1248 Trailer2TPMPressureWarning_UB_IS 7;
BA_ "GenSigCycleTime" SG_ 1248 Trailer2TPMPressureWarning_UB_IS 100;
BA_ "GenSigCycleTimeActive" SG_ 1248 Trailer2TPMPressureWarning_UB_IS 100;
BA_ "Platform_VMCU1_Sig" SG_ 1248 Trailer2TPMPressureWarning_UB_IS 1;
BA_ "SystemSignalLongSymbol" SG_ 1248 Trailer2TPMPressureWarning_UB_IS "Trailer2TPMPressureWarning_UB_ISig_6";
BA_ "GenSigCycleTime" SG_ 1248 Trailer2TPMPressureWarning_ISig_ 100;
BA_ "GenSigCycleTimeActive" SG_ 1248 Trailer2TPMPressureWarning_ISig_ 100;
BA_ "GenSigStartValue" SG_ 1248 Trailer2TPMPressureWarning_ISig_ 7;
BA_ "NeedsUpdateBit" SG_ 1248 Trailer2TPMPressureWarning_ISig_ 1;
BA_ "Platform_VMCU1_Sig" SG_ 1248 Trailer2TPMPressureWarning_ISig_ 1;
BA_ "SystemSignalLongSymbol" SG_ 1248 Trailer2TPMPressureWarning_ISig_ "Trailer2TPMPressureWarning_ISig_6";
BA_ "GenSigCycleTime" SG_ 1248 Trailer1TPMMatedStatus_ISig_6 100;
BA_ "GenSigCycleTimeActive" SG_ 1248 Trailer1TPMMatedStatus_ISig_6 100;
BA_ "GenSigStartValue" SG_ 1248 Trailer1TPMMatedStatus_ISig_6 3;
BA_ "Platform_VMCU1_Sig" SG_ 1248 Trailer1TPMMatedStatus_ISig_6 1;
BA_ "GenSigCycleTime" SG_ 1248 Trailer1TPMLeakageWarning_ISig_6 100;
BA_ "GenSigCycleTimeActive" SG_ 1248 Trailer1TPMLeakageWarning_ISig_6 100;
BA_ "GenSigStartValue" SG_ 1248 Trailer1TPMLeakageWarning_ISig_6 7;
BA_ "NeedsUpdateBit" SG_ 1248 Trailer1TPMLeakageWarning_ISig_6 1;
BA_ "Platform_VMCU1_Sig" SG_ 1248 Trailer1TPMLeakageWarning_ISig_6 1;
BA_ "GenSigCycleTime" SG_ 1248 Trailer2TPMMatedStatus_ISig_6 100;
BA_ "GenSigCycleTimeActive" SG_ 1248 Trailer2TPMMatedStatus_ISig_6 100;
BA_ "GenSigStartValue" SG_ 1248 Trailer2TPMMatedStatus_ISig_6 3;
BA_ "Platform_VMCU1_Sig" SG_ 1248 Trailer2TPMMatedStatus_ISig_6 1;
BA_ "GenSigSendType" SG_ 1248 TruckTPMLeakageWarning_UB_ISig_6 7;
BA_ "GenSigCycleTime" SG_ 1248 TruckTPMLeakageWarning_UB_ISig_6 100;
BA_ "GenSigCycleTimeActive" SG_ 1248 TruckTPMLeakageWarning_UB_ISig_6 100;
BA_ "Platform_VMCU1_Sig" SG_ 1248 TruckTPMLeakageWarning_UB_ISig_6 1;
BA_ "GenSigCycleTime" SG_ 1248 TruckTPMPressureWarning_ISig_6 100;
BA_ "GenSigCycleTimeActive" SG_ 1248 TruckTPMPressureWarning_ISig_6 100;
BA_ "GenSigStartValue" SG_ 1248 TruckTPMPressureWarning_ISig_6 7;
BA_ "NeedsUpdateBit" SG_ 1248 TruckTPMPressureWarning_ISig_6 1;
BA_ "Platform_VMCU1_Sig" SG_ 1248 TruckTPMPressureWarning_ISig_6 1;
BA_ "GenSigSendType" SG_ 1248 Trailer1TPMLeakageWarning_UB_ISi 7;
BA_ "GenSigCycleTime" SG_ 1248 Trailer1TPMLeakageWarning_UB_ISi 100;
BA_ "GenSigCycleTimeActive" SG_ 1248 Trailer1TPMLeakageWarning_UB_ISi 100;
BA_ "Platform_VMCU1_Sig" SG_ 1248 Trailer1TPMLeakageWarning_UB_ISi 1;
BA_ "SystemSignalLongSymbol" SG_ 1248 Trailer1TPMLeakageWarning_UB_ISi "Trailer1TPMLeakageWarning_UB_ISig_6";
BA_ "GenSigCycleTime" SG_ 1248 TruckTPMLeakageWarning_ISig_6 100;
BA_ "GenSigCycleTimeActive" SG_ 1248 TruckTPMLeakageWarning_ISig_6 100;
BA_ "GenSigStartValue" SG_ 1248 TruckTPMLeakageWarning_ISig_6 7;
BA_ "NeedsUpdateBit" SG_ 1248 TruckTPMLeakageWarning_ISig_6 1;
BA_ "Platform_VMCU1_Sig" SG_ 1248 TruckTPMLeakageWarning_ISig_6 1;
BA_ "GenSigCycleTime" SG_ 1248 Trailer2TPMLeakageWarning_ISig_6 100;
BA_ "GenSigCycleTimeActive" SG_ 1248 Trailer2TPMLeakageWarning_ISig_6 100;
BA_ "GenSigStartValue" SG_ 1248 Trailer2TPMLeakageWarning_ISig_6 7;
BA_ "NeedsUpdateBit" SG_ 1248 Trailer2TPMLeakageWarning_ISig_6 1;
BA_ "Platform_VMCU1_Sig" SG_ 1248 Trailer2TPMLeakageWarning_ISig_6 1;
BA_ "GenSigCycleTime" SG_ 1342 TruckTPMTireInfo_Temperature_ISi 100;
BA_ "GenSigCycleTimeActive" SG_ 1342 TruckTPMTireInfo_Temperature_ISi 100;
BA_ "GenSigStartValue" SG_ 1342 TruckTPMTireInfo_Temperature_ISi 255;
BA_ "NeedsUpdateBit" SG_ 1342 TruckTPMTireInfo_Temperature_ISi 1;
BA_ "Platform_VMCU1_Sig" SG_ 1342 TruckTPMTireInfo_Temperature_ISi 1;
BA_ "SystemSignalLongSymbol" SG_ 1342 TruckTPMTireInfo_Temperature_ISi "TruckTPMTireInfo_Temperature_ISig_6";
BA_ "GenSigCycleTime" SG_ 1342 TruckTPMTireInfo_Battery_ISig_6 100;
BA_ "GenSigCycleTimeActive" SG_ 1342 TruckTPMTireInfo_Battery_ISig_6 100;
BA_ "GenSigStartValue" SG_ 1342 TruckTPMTireInfo_Battery_ISig_6 7;
BA_ "NeedsUpdateBit" SG_ 1342 TruckTPMTireInfo_Battery_ISig_6 1;
BA_ "Platform_VMCU1_Sig" SG_ 1342 TruckTPMTireInfo_Battery_ISig_6 1;
BA_ "GenSigSendType" SG_ 1342 TruckTPMTireInfo_sg_UB_ISig_6 7;
BA_ "GenSigCycleTime" SG_ 1342 TruckTPMTireInfo_sg_UB_ISig_6 100;
BA_ "GenSigCycleTimeActive" SG_ 1342 TruckTPMTireInfo_sg_UB_ISig_6 100;
BA_ "Platform_VMCU1_Sig" SG_ 1342 TruckTPMTireInfo_sg_UB_ISig_6 1;
BA_ "GenSigCycleTime" SG_ 1342 TruckTPMTireInfo_PresWarn_ISig_6 100;
BA_ "GenSigCycleTimeActive" SG_ 1342 TruckTPMTireInfo_PresWarn_ISig_6 100;
BA_ "GenSigStartValue" SG_ 1342 TruckTPMTireInfo_PresWarn_ISig_6 7;
BA_ "NeedsUpdateBit" SG_ 1342 TruckTPMTireInfo_PresWarn_ISig_6 1;
BA_ "Platform_VMCU1_Sig" SG_ 1342 TruckTPMTireInfo_PresWarn_ISig_6 1;
BA_ "GenSigCycleTime" SG_ 1342 TruckTPMTireInfo_RefPres_ISig_6 100;
BA_ "GenSigCycleTimeActive" SG_ 1342 TruckTPMTireInfo_RefPres_ISig_6 100;
BA_ "GenSigStartValue" SG_ 1342 TruckTPMTireInfo_RefPres_ISig_6 255;
BA_ "NeedsUpdateBit" SG_ 1342 TruckTPMTireInfo_RefPres_ISig_6 1;
BA_ "Platform_VMCU1_Sig" SG_ 1342 TruckTPMTireInfo_RefPres_ISig_6 1;
BA_ "GenSigCycleTime" SG_ 1342 TruckTPMTireInfo_Pressure_ISig_6 100;
BA_ "GenSigCycleTimeActive" SG_ 1342 TruckTPMTireInfo_Pressure_ISig_6 100;
BA_ "GenSigStartValue" SG_ 1342 TruckTPMTireInfo_Pressure_ISig_6 255;
BA_ "NeedsUpdateBit" SG_ 1342 TruckTPMTireInfo_Pressure_ISig_6 1;
BA_ "Platform_VMCU1_Sig" SG_ 1342 TruckTPMTireInfo_Pressure_ISig_6 1;
BA_ "GenSigCycleTime" SG_ 1342 TruckTPMTireInfo_TireId_ISig_6 100;
BA_ "GenSigCycleTimeActive" SG_ 1342 TruckTPMTireInfo_TireId_ISig_6 100;
BA_ "NeedsUpdateBit" SG_ 1342 TruckTPMTireInfo_TireId_ISig_6 1;
BA_ "Platform_VMCU1_Sig" SG_ 1342 TruckTPMTireInfo_TireId_ISig_6 1;
BA_ "GenSigCycleTime" SG_ 1342 TruckTPMTireInfo_LeakageWarn_ISi 100;
BA_ "GenSigCycleTimeActive" SG_ 1342 TruckTPMTireInfo_LeakageWarn_ISi 100;
BA_ "GenSigStartValue" SG_ 1342 TruckTPMTireInfo_LeakageWarn_ISi 7;
BA_ "NeedsUpdateBit" SG_ 1342 TruckTPMTireInfo_LeakageWarn_ISi 1;
BA_ "Platform_VMCU1_Sig" SG_ 1342 TruckTPMTireInfo_LeakageWarn_ISi 1;
BA_ "SystemSignalLongSymbol" SG_ 1342 TruckTPMTireInfo_LeakageWarn_ISi "TruckTPMTireInfo_LeakageWarn_ISig_6";
BA_ "GenSigCycleTime" SG_ 1342 TruckTPMTireInfo_Active_ISig_6 100;
BA_ "GenSigCycleTimeActive" SG_ 1342 TruckTPMTireInfo_Active_ISig_6 100;
BA_ "GenSigStartValue" SG_ 1342 TruckTPMTireInfo_Active_ISig_6 3;
BA_ "NeedsUpdateBit" SG_ 1342 TruckTPMTireInfo_Active_ISig_6 1;
BA_ "Platform_VMCU1_Sig" SG_ 1342 TruckTPMTireInfo_Active_ISig_6 1;
BA_ "GenSigCycleTime" SG_ 1341 Trailer2TPMLostCom_ISig_6 100;
BA_ "GenSigCycleTimeActive" SG_ 1341 Trailer2TPMLostCom_ISig_6 100;
BA_ "GenSigStartValue" SG_ 1341 Trailer2TPMLostCom_ISig_6 3;
BA_ "NeedsUpdateBit" SG_ 1341 Trailer2TPMLostCom_ISig_6 1;
BA_ "Platform_VMCU1_Sig" SG_ 1341 Trailer2TPMLostCom_ISig_6 1;
BA_ "GenSigCycleTime" SG_ 1341 Trailer2TPMTireInfo_RefPres_ISig 100;
BA_ "GenSigCycleTimeActive" SG_ 1341 Trailer2TPMTireInfo_RefPres_ISig 100;
BA_ "GenSigStartValue" SG_ 1341 Trailer2TPMTireInfo_RefPres_ISig 255;
BA_ "NeedsUpdateBit" SG_ 1341 Trailer2TPMTireInfo_RefPres_ISig 1;
BA_ "Platform_VMCU1_Sig" SG_ 1341 Trailer2TPMTireInfo_RefPres_ISig 1;
BA_ "SystemSignalLongSymbol" SG_ 1341 Trailer2TPMTireInfo_RefPres_ISig "Trailer2TPMTireInfo_RefPres_ISig_6";
BA_ "GenSigCycleTime" SG_ 1341 Trailer2TPMTireInfo_PresWarn_ISi 100;
BA_ "GenSigCycleTimeActive" SG_ 1341 Trailer2TPMTireInfo_PresWarn_ISi 100;
BA_ "GenSigStartValue" SG_ 1341 Trailer2TPMTireInfo_PresWarn_ISi 7;
BA_ "NeedsUpdateBit" SG_ 1341 Trailer2TPMTireInfo_PresWarn_ISi 1;
BA_ "Platform_VMCU1_Sig" SG_ 1341 Trailer2TPMTireInfo_PresWarn_ISi 1;
BA_ "SystemSignalLongSymbol" SG_ 1341 Trailer2TPMTireInfo_PresWarn_ISi "Trailer2TPMTireInfo_PresWarn_ISig_6";
BA_ "GenSigCycleTime" SG_ 1341 TPMTrailerPositionStat_ISig_6 100;
BA_ "GenSigCycleTimeActive" SG_ 1341 TPMTrailerPositionStat_ISig_6 100;
BA_ "GenSigStartValue" SG_ 1341 TPMTrailerPositionStat_ISig_6 3;
BA_ "Platform_VMCU1_Sig" SG_ 1341 TPMTrailerPositionStat_ISig_6 1;
BA_ "GenSigSendType" SG_ 1341 Trailer2TPMLostCom_UB_ISig_6 7;
BA_ "GenSigCycleTime" SG_ 1341 Trailer2TPMLostCom_UB_ISig_6 100;
BA_ "GenSigCycleTimeActive" SG_ 1341 Trailer2TPMLostCom_UB_ISig_6 100;
BA_ "Platform_VMCU1_Sig" SG_ 1341 Trailer2TPMLostCom_UB_ISig_6 1;
BA_ "GenSigCycleTime" SG_ 1341 Trailer2TPMTireInfo_Battery_ISig 100;
BA_ "GenSigCycleTimeActive" SG_ 1341 Trailer2TPMTireInfo_Battery_ISig 100;
BA_ "GenSigStartValue" SG_ 1341 Trailer2TPMTireInfo_Battery_ISig 7;
BA_ "NeedsUpdateBit" SG_ 1341 Trailer2TPMTireInfo_Battery_ISig 1;
BA_ "Platform_VMCU1_Sig" SG_ 1341 Trailer2TPMTireInfo_Battery_ISig 1;
BA_ "SystemSignalLongSymbol" SG_ 1341 Trailer2TPMTireInfo_Battery_ISig "Trailer2TPMTireInfo_Battery_ISig_6";
BA_ "GenSigCycleTime" SG_ 1341 Trailer2TPMTireInfo_LeakageWarn_ 100;
BA_ "GenSigCycleTimeActive" SG_ 1341 Trailer2TPMTireInfo_LeakageWarn_ 100;
BA_ "GenSigStartValue" SG_ 1341 Trailer2TPMTireInfo_LeakageWarn_ 7;
BA_ "NeedsUpdateBit" SG_ 1341 Trailer2TPMTireInfo_LeakageWarn_ 1;
BA_ "Platform_VMCU1_Sig" SG_ 1341 Trailer2TPMTireInfo_LeakageWarn_ 1;
BA_ "SystemSignalLongSymbol" SG_ 1341 Trailer2TPMTireInfo_LeakageWarn_ "Trailer2TPMTireInfo_LeakageWarn_ISig_6";
BA_ "GenSigCycleTime" SG_ 1341 Trailer2TPMTireInfo_Pressure_ISi 100;
BA_ "GenSigCycleTimeActive" SG_ 1341 Trailer2TPMTireInfo_Pressure_ISi 100;
BA_ "GenSigStartValue" SG_ 1341 Trailer2TPMTireInfo_Pressure_ISi 255;
BA_ "NeedsUpdateBit" SG_ 1341 Trailer2TPMTireInfo_Pressure_ISi 1;
BA_ "Platform_VMCU1_Sig" SG_ 1341 Trailer2TPMTireInfo_Pressure_ISi 1;
BA_ "SystemSignalLongSymbol" SG_ 1341 Trailer2TPMTireInfo_Pressure_ISi "Trailer2TPMTireInfo_Pressure_ISig_6";
BA_ "GenSigSendType" SG_ 1341 Trailer2TPMTireInfo_sg_UB_ISig_6 7;
BA_ "GenSigCycleTime" SG_ 1341 Trailer2TPMTireInfo_sg_UB_ISig_6 100;
BA_ "GenSigCycleTimeActive" SG_ 1341 Trailer2TPMTireInfo_sg_UB_ISig_6 100;
BA_ "Platform_VMCU1_Sig" SG_ 1341 Trailer2TPMTireInfo_sg_UB_ISig_6 1;
BA_ "GenSigCycleTime" SG_ 1341 Trailer1TPMFailure_ISig_6 100;
BA_ "GenSigCycleTimeActive" SG_ 1341 Trailer1TPMFailure_ISig_6 100;
BA_ "GenSigStartValue" SG_ 1341 Trailer1TPMFailure_ISig_6 3;
BA_ "Platform_VMCU1_Sig" SG_ 1341 Trailer1TPMFailure_ISig_6 1;
BA_ "GenSigCycleTime" SG_ 1341 TruckTPMFailure_ISig_6 100;
BA_ "GenSigCycleTimeActive" SG_ 1341 TruckTPMFailure_ISig_6 100;
BA_ "GenSigStartValue" SG_ 1341 TruckTPMFailure_ISig_6 3;
BA_ "Platform_VMCU1_Sig" SG_ 1341 TruckTPMFailure_ISig_6 1;
BA_ "GenSigCycleTime" SG_ 1341 Trailer2TPMTireInfo_Active_ISig_ 100;
BA_ "GenSigCycleTimeActive" SG_ 1341 Trailer2TPMTireInfo_Active_ISig_ 100;
BA_ "GenSigStartValue" SG_ 1341 Trailer2TPMTireInfo_Active_ISig_ 3;
BA_ "NeedsUpdateBit" SG_ 1341 Trailer2TPMTireInfo_Active_ISig_ 1;
BA_ "Platform_VMCU1_Sig" SG_ 1341 Trailer2TPMTireInfo_Active_ISig_ 1;
BA_ "SystemSignalLongSymbol" SG_ 1341 Trailer2TPMTireInfo_Active_ISig_ "Trailer2TPMTireInfo_Active_ISig_6";
BA_ "GenSigCycleTime" SG_ 1341 Trailer2TPMFailure_ISig_6 100;
BA_ "GenSigCycleTimeActive" SG_ 1341 Trailer2TPMFailure_ISig_6 100;
BA_ "GenSigStartValue" SG_ 1341 Trailer2TPMFailure_ISig_6 3;
BA_ "Platform_VMCU1_Sig" SG_ 1341 Trailer2TPMFailure_ISig_6 1;
BA_ "GenSigCycleTime" SG_ 1341 Trailer2TPMTireInfo_TireId_ISig_ 100;
BA_ "GenSigCycleTimeActive" SG_ 1341 Trailer2TPMTireInfo_TireId_ISig_ 100;
BA_ "NeedsUpdateBit" SG_ 1341 Trailer2TPMTireInfo_TireId_ISig_ 1;
BA_ "Platform_VMCU1_Sig" SG_ 1341 Trailer2TPMTireInfo_TireId_ISig_ 1;
BA_ "SystemSignalLongSymbol" SG_ 1341 Trailer2TPMTireInfo_TireId_ISig_ "Trailer2TPMTireInfo_TireId_ISig_6";
BA_ "GenSigCycleTime" SG_ 1341 Trailer2TPMTireInfo_Temperature_ 100;
BA_ "GenSigCycleTimeActive" SG_ 1341 Trailer2TPMTireInfo_Temperature_ 100;
BA_ "GenSigStartValue" SG_ 1341 Trailer2TPMTireInfo_Temperature_ 255;
BA_ "NeedsUpdateBit" SG_ 1341 Trailer2TPMTireInfo_Temperature_ 1;
BA_ "Platform_VMCU1_Sig" SG_ 1341 Trailer2TPMTireInfo_Temperature_ 1;
BA_ "SystemSignalLongSymbol" SG_ 1341 Trailer2TPMTireInfo_Temperature_ "Trailer2TPMTireInfo_Temperature_ISig_6";
BA_ "GenSigCycleTime" SG_ 1340 Trailer1TPMTireInfo_PresWarn_ISi 100;
BA_ "GenSigCycleTimeActive" SG_ 1340 Trailer1TPMTireInfo_PresWarn_ISi 100;
BA_ "GenSigStartValue" SG_ 1340 Trailer1TPMTireInfo_PresWarn_ISi 7;
BA_ "NeedsUpdateBit" SG_ 1340 Trailer1TPMTireInfo_PresWarn_ISi 1;
BA_ "Platform_VMCU1_Sig" SG_ 1340 Trailer1TPMTireInfo_PresWarn_ISi 1;
BA_ "SystemSignalLongSymbol" SG_ 1340 Trailer1TPMTireInfo_PresWarn_ISi "Trailer1TPMTireInfo_PresWarn_ISig_6";
BA_ "GenSigCycleTime" SG_ 1340 Trailer1TPMTireInfo_RefPres_ISig 100;
BA_ "GenSigCycleTimeActive" SG_ 1340 Trailer1TPMTireInfo_RefPres_ISig 100;
BA_ "GenSigStartValue" SG_ 1340 Trailer1TPMTireInfo_RefPres_ISig 255;
BA_ "NeedsUpdateBit" SG_ 1340 Trailer1TPMTireInfo_RefPres_ISig 1;
BA_ "Platform_VMCU1_Sig" SG_ 1340 Trailer1TPMTireInfo_RefPres_ISig 1;
BA_ "SystemSignalLongSymbol" SG_ 1340 Trailer1TPMTireInfo_RefPres_ISig "Trailer1TPMTireInfo_RefPres_ISig_6";
BA_ "GenSigCycleTime" SG_ 1340 Trailer1TPMTireInfo_Active_ISig_ 100;
BA_ "GenSigCycleTimeActive" SG_ 1340 Trailer1TPMTireInfo_Active_ISig_ 100;
BA_ "GenSigStartValue" SG_ 1340 Trailer1TPMTireInfo_Active_ISig_ 3;
BA_ "NeedsUpdateBit" SG_ 1340 Trailer1TPMTireInfo_Active_ISig_ 1;
BA_ "Platform_VMCU1_Sig" SG_ 1340 Trailer1TPMTireInfo_Active_ISig_ 1;
BA_ "SystemSignalLongSymbol" SG_ 1340 Trailer1TPMTireInfo_Active_ISig_ "Trailer1TPMTireInfo_Active_ISig_6";
BA_ "GenSigCycleTime" SG_ 1340 TPMPosOfWMResp_TireId_ISig_6 100;
BA_ "GenSigCycleTimeActive" SG_ 1340 TPMPosOfWMResp_TireId_ISig_6 100;
BA_ "NeedsUpdateBit" SG_ 1340 TPMPosOfWMResp_TireId_ISig_6 1;
BA_ "Platform_VMCU1_Sig" SG_ 1340 TPMPosOfWMResp_TireId_ISig_6 1;
BA_ "GenSigCycleTime" SG_ 1340 Trailer1TPMLostCom_ISig_6 100;
BA_ "GenSigCycleTimeActive" SG_ 1340 Trailer1TPMLostCom_ISig_6 100;
BA_ "GenSigStartValue" SG_ 1340 Trailer1TPMLostCom_ISig_6 3;
BA_ "NeedsUpdateBit" SG_ 1340 Trailer1TPMLostCom_ISig_6 1;
BA_ "Platform_VMCU1_Sig" SG_ 1340 Trailer1TPMLostCom_ISig_6 1;
BA_ "GenSigCycleTime" SG_ 1340 TPMPosOfWMResp_Status_ISig_6 100;
BA_ "GenSigCycleTimeActive" SG_ 1340 TPMPosOfWMResp_Status_ISig_6 100;
BA_ "GenSigStartValue" SG_ 1340 TPMPosOfWMResp_Status_ISig_6 7;
BA_ "NeedsUpdateBit" SG_ 1340 TPMPosOfWMResp_Status_ISig_6 1;
BA_ "Platform_VMCU1_Sig" SG_ 1340 TPMPosOfWMResp_Status_ISig_6 1;
BA_ "GenSigSendType" SG_ 1340 Trailer1TPMTireInfo_sg_UB_ISig_6 7;
BA_ "GenSigCycleTime" SG_ 1340 Trailer1TPMTireInfo_sg_UB_ISig_6 100;
BA_ "GenSigCycleTimeActive" SG_ 1340 Trailer1TPMTireInfo_sg_UB_ISig_6 100;
BA_ "Platform_VMCU1_Sig" SG_ 1340 Trailer1TPMTireInfo_sg_UB_ISig_6 1;
BA_ "GenSigCycleTime" SG_ 1340 Trailer1TPMTireInfo_TireId_ISig_ 100;
BA_ "GenSigCycleTimeActive" SG_ 1340 Trailer1TPMTireInfo_TireId_ISig_ 100;
BA_ "NeedsUpdateBit" SG_ 1340 Trailer1TPMTireInfo_TireId_ISig_ 1;
BA_ "Platform_VMCU1_Sig" SG_ 1340 Trailer1TPMTireInfo_TireId_ISig_ 1;
BA_ "SystemSignalLongSymbol" SG_ 1340 Trailer1TPMTireInfo_TireId_ISig_ "Trailer1TPMTireInfo_TireId_ISig_6";
BA_ "GenSigCycleTime" SG_ 1340 Trailer1TPMTireInfo_Pressure_ISi 100;
BA_ "GenSigCycleTimeActive" SG_ 1340 Trailer1TPMTireInfo_Pressure_ISi 100;
BA_ "GenSigStartValue" SG_ 1340 Trailer1TPMTireInfo_Pressure_ISi 255;
BA_ "NeedsUpdateBit" SG_ 1340 Trailer1TPMTireInfo_Pressure_ISi 1;
BA_ "Platform_VMCU1_Sig" SG_ 1340 Trailer1TPMTireInfo_Pressure_ISi 1;
BA_ "SystemSignalLongSymbol" SG_ 1340 Trailer1TPMTireInfo_Pressure_ISi "Trailer1TPMTireInfo_Pressure_ISig_6";
BA_ "GenSigSendType" SG_ 1340 TPMPosOfWMResp_sg_UB_ISig_6 7;
BA_ "GenSigCycleTime" SG_ 1340 TPMPosOfWMResp_sg_UB_ISig_6 100;
BA_ "GenSigCycleTimeActive" SG_ 1340 TPMPosOfWMResp_sg_UB_ISig_6 100;
BA_ "Platform_VMCU1_Sig" SG_ 1340 TPMPosOfWMResp_sg_UB_ISig_6 1;
BA_ "GenSigCycleTime" SG_ 1340 Trailer1TPMTireInfo_Battery_ISig 100;
BA_ "GenSigCycleTimeActive" SG_ 1340 Trailer1TPMTireInfo_Battery_ISig 100;
BA_ "GenSigStartValue" SG_ 1340 Trailer1TPMTireInfo_Battery_ISig 7;
BA_ "NeedsUpdateBit" SG_ 1340 Trailer1TPMTireInfo_Battery_ISig 1;
BA_ "Platform_VMCU1_Sig" SG_ 1340 Trailer1TPMTireInfo_Battery_ISig 1;
BA_ "SystemSignalLongSymbol" SG_ 1340 Trailer1TPMTireInfo_Battery_ISig "Trailer1TPMTireInfo_Battery_ISig_6";
BA_ "GenSigCycleTime" SG_ 1340 Trailer1TPMTireInfo_Temperature_ 100;
BA_ "GenSigCycleTimeActive" SG_ 1340 Trailer1TPMTireInfo_Temperature_ 100;
BA_ "GenSigStartValue" SG_ 1340 Trailer1TPMTireInfo_Temperature_ 255;
BA_ "NeedsUpdateBit" SG_ 1340 Trailer1TPMTireInfo_Temperature_ 1;
BA_ "Platform_VMCU1_Sig" SG_ 1340 Trailer1TPMTireInfo_Temperature_ 1;
BA_ "SystemSignalLongSymbol" SG_ 1340 Trailer1TPMTireInfo_Temperature_ "Trailer1TPMTireInfo_Temperature_ISig_6";
BA_ "GenSigCycleTime" SG_ 1340 TPMPosOfWMResp_VehiclePos_ISig_6 100;
BA_ "GenSigCycleTimeActive" SG_ 1340 TPMPosOfWMResp_VehiclePos_ISig_6 100;
BA_ "GenSigStartValue" SG_ 1340 TPMPosOfWMResp_VehiclePos_ISig_6 7;
BA_ "NeedsUpdateBit" SG_ 1340 TPMPosOfWMResp_VehiclePos_ISig_6 1;
BA_ "Platform_VMCU1_Sig" SG_ 1340 TPMPosOfWMResp_VehiclePos_ISig_6 1;
BA_ "GenSigSendType" SG_ 1340 Trailer1TPMLostCom_UB_ISig_6 7;
BA_ "GenSigCycleTime" SG_ 1340 Trailer1TPMLostCom_UB_ISig_6 100;
BA_ "GenSigCycleTimeActive" SG_ 1340 Trailer1TPMLostCom_UB_ISig_6 100;
BA_ "Platform_VMCU1_Sig" SG_ 1340 Trailer1TPMLostCom_UB_ISig_6 1;
BA_ "GenSigCycleTime" SG_ 1340 Trailer1TPMTireInfo_LeakageWarn_ 100;
BA_ "GenSigCycleTimeActive" SG_ 1340 Trailer1TPMTireInfo_LeakageWarn_ 100;
BA_ "GenSigStartValue" SG_ 1340 Trailer1TPMTireInfo_LeakageWarn_ 7;
BA_ "NeedsUpdateBit" SG_ 1340 Trailer1TPMTireInfo_LeakageWarn_ 1;
BA_ "Platform_VMCU1_Sig" SG_ 1340 Trailer1TPMTireInfo_LeakageWarn_ 1;
BA_ "SystemSignalLongSymbol" SG_ 1340 Trailer1TPMTireInfo_LeakageWarn_ "Trailer1TPMTireInfo_LeakageWarn_ISig_6";
BA_ "GenSigCycleTime" SG_ 1528 TruckTPMAxlTireCfg_Axle1_ISig_6 100;
BA_ "GenSigCycleTimeActive" SG_ 1528 TruckTPMAxlTireCfg_Axle1_ISig_6 100;
BA_ "GenSigStartValue" SG_ 1528 TruckTPMAxlTireCfg_Axle1_ISig_6 7;
BA_ "Platform_VMCU1_Sig" SG_ 1528 TruckTPMAxlTireCfg_Axle1_ISig_6 1;
BA_ "GenSigCycleTime" SG_ 1528 TruckTPMThresCfg_ExtUnderPres_IS 100;
BA_ "GenSigCycleTimeActive" SG_ 1528 TruckTPMThresCfg_ExtUnderPres_IS 100;
BA_ "GenSigStartValue" SG_ 1528 TruckTPMThresCfg_ExtUnderPres_IS 255;
BA_ "NeedsUpdateBit" SG_ 1528 TruckTPMThresCfg_ExtUnderPres_IS 1;
BA_ "Platform_VMCU1_Sig" SG_ 1528 TruckTPMThresCfg_ExtUnderPres_IS 1;
BA_ "SystemSignalLongSymbol" SG_ 1528 TruckTPMThresCfg_ExtUnderPres_IS "TruckTPMThresCfg_ExtUnderPres_ISig_6";
BA_ "GenSigCycleTime" SG_ 1528 TruckTPMThresCfg_OverPres_ISig_6 100;
BA_ "GenSigCycleTimeActive" SG_ 1528 TruckTPMThresCfg_OverPres_ISig_6 100;
BA_ "GenSigStartValue" SG_ 1528 TruckTPMThresCfg_OverPres_ISig_6 255;
BA_ "NeedsUpdateBit" SG_ 1528 TruckTPMThresCfg_OverPres_ISig_6 1;
BA_ "Platform_VMCU1_Sig" SG_ 1528 TruckTPMThresCfg_OverPres_ISig_6 1;
BA_ "GenSigCycleTime" SG_ 1528 TruckTPMAxlTireCfg_Axle4_ISig_6 100;
BA_ "GenSigCycleTimeActive" SG_ 1528 TruckTPMAxlTireCfg_Axle4_ISig_6 100;
BA_ "GenSigStartValue" SG_ 1528 TruckTPMAxlTireCfg_Axle4_ISig_6 7;
BA_ "Platform_VMCU1_Sig" SG_ 1528 TruckTPMAxlTireCfg_Axle4_ISig_6 1;
BA_ "GenSigSendType" SG_ 1528 TruckTPMThresCfg_sg_UB_ISig_6 7;
BA_ "GenSigCycleTime" SG_ 1528 TruckTPMThresCfg_sg_UB_ISig_6 100;
BA_ "GenSigCycleTimeActive" SG_ 1528 TruckTPMThresCfg_sg_UB_ISig_6 100;
BA_ "Platform_VMCU1_Sig" SG_ 1528 TruckTPMThresCfg_sg_UB_ISig_6 1;
BA_ "GenSigCycleTime" SG_ 1528 TruckTPMThresCfg_ExtOverPres_ISi 100;
BA_ "GenSigCycleTimeActive" SG_ 1528 TruckTPMThresCfg_ExtOverPres_ISi 100;
BA_ "GenSigStartValue" SG_ 1528 TruckTPMThresCfg_ExtOverPres_ISi 255;
BA_ "NeedsUpdateBit" SG_ 1528 TruckTPMThresCfg_ExtOverPres_ISi 1;
BA_ "Platform_VMCU1_Sig" SG_ 1528 TruckTPMThresCfg_ExtOverPres_ISi 1;
BA_ "SystemSignalLongSymbol" SG_ 1528 TruckTPMThresCfg_ExtOverPres_ISi "TruckTPMThresCfg_ExtOverPres_ISig_6";
BA_ "GenSigCycleTime" SG_ 1528 TruckTPMAxlTireCfg_Axle2_ISig_6 100;
BA_ "GenSigCycleTimeActive" SG_ 1528 TruckTPMAxlTireCfg_Axle2_ISig_6 100;
BA_ "GenSigStartValue" SG_ 1528 TruckTPMAxlTireCfg_Axle2_ISig_6 7;
BA_ "Platform_VMCU1_Sig" SG_ 1528 TruckTPMAxlTireCfg_Axle2_ISig_6 1;
BA_ "GenSigCycleTime" SG_ 1528 TruckTPMAxlTireCfg_Axle3_ISig_6 100;
BA_ "GenSigCycleTimeActive" SG_ 1528 TruckTPMAxlTireCfg_Axle3_ISig_6 100;
BA_ "GenSigStartValue" SG_ 1528 TruckTPMAxlTireCfg_Axle3_ISig_6 7;
BA_ "Platform_VMCU1_Sig" SG_ 1528 TruckTPMAxlTireCfg_Axle3_ISig_6 1;
BA_ "GenSigCycleTime" SG_ 1528 TruckTPMThresCfg_UnderPres_ISig_ 100;
BA_ "GenSigCycleTimeActive" SG_ 1528 TruckTPMThresCfg_UnderPres_ISig_ 100;
BA_ "GenSigStartValue" SG_ 1528 TruckTPMThresCfg_UnderPres_ISig_ 255;
BA_ "NeedsUpdateBit" SG_ 1528 TruckTPMThresCfg_UnderPres_ISig_ 1;
BA_ "Platform_VMCU1_Sig" SG_ 1528 TruckTPMThresCfg_UnderPres_ISig_ 1;
BA_ "SystemSignalLongSymbol" SG_ 1528 TruckTPMThresCfg_UnderPres_ISig_ "TruckTPMThresCfg_UnderPres_ISig_6";
BA_ "GenSigCycleTime" SG_ 1528 TruckTPMAxlTireCfg_Axle5_ISig_6 100;
BA_ "GenSigCycleTimeActive" SG_ 1528 TruckTPMAxlTireCfg_Axle5_ISig_6 100;
BA_ "GenSigStartValue" SG_ 1528 TruckTPMAxlTireCfg_Axle5_ISig_6 7;
BA_ "Platform_VMCU1_Sig" SG_ 1528 TruckTPMAxlTireCfg_Axle5_ISig_6 1;
BA_ "GenSigCycleTime" SG_ 1528 TruckTPMThresCfg_AxleNr_ISig_6 100;
BA_ "GenSigCycleTimeActive" SG_ 1528 TruckTPMThresCfg_AxleNr_ISig_6 100;
BA_ "GenSigStartValue" SG_ 1528 TruckTPMThresCfg_AxleNr_ISig_6 7;
BA_ "NeedsUpdateBit" SG_ 1528 TruckTPMThresCfg_AxleNr_ISig_6 1;
BA_ "Platform_VMCU1_Sig" SG_ 1528 TruckTPMThresCfg_AxleNr_ISig_6 1;
BA_ "GenSigCycleTime" SG_ 1525 Trailer2TPMType_ISig_6 100;
BA_ "GenSigCycleTimeActive" SG_ 1525 Trailer2TPMType_ISig_6 100;
BA_ "GenSigStartValue" SG_ 1525 Trailer2TPMType_ISig_6 3;
BA_ "NeedsUpdateBit" SG_ 1525 Trailer2TPMType_ISig_6 1;
BA_ "Platform_VMCU1_Sig" SG_ 1525 Trailer2TPMType_ISig_6 1;
BA_ "GenSigCycleTime" SG_ 1525 Trailer2TPMThresCfg_UnderPres_IS 100;
BA_ "GenSigCycleTimeActive" SG_ 1525 Trailer2TPMThresCfg_UnderPres_IS 100;
BA_ "GenSigStartValue" SG_ 1525 Trailer2TPMThresCfg_UnderPres_IS 255;
BA_ "NeedsUpdateBit" SG_ 1525 Trailer2TPMThresCfg_UnderPres_IS 1;
BA_ "Platform_VMCU1_Sig" SG_ 1525 Trailer2TPMThresCfg_UnderPres_IS 1;
BA_ "SystemSignalLongSymbol" SG_ 1525 Trailer2TPMThresCfg_UnderPres_IS "Trailer2TPMThresCfg_UnderPres_ISig_6";
BA_ "GenSigCycleTime" SG_ 1525 Trailer2TPMThresCfg_AxleNr_ISig_ 100;
BA_ "GenSigCycleTimeActive" SG_ 1525 Trailer2TPMThresCfg_AxleNr_ISig_ 100;
BA_ "GenSigStartValue" SG_ 1525 Trailer2TPMThresCfg_AxleNr_ISig_ 7;
BA_ "NeedsUpdateBit" SG_ 1525 Trailer2TPMThresCfg_AxleNr_ISig_ 1;
BA_ "Platform_VMCU1_Sig" SG_ 1525 Trailer2TPMThresCfg_AxleNr_ISig_ 1;
BA_ "SystemSignalLongSymbol" SG_ 1525 Trailer2TPMThresCfg_AxleNr_ISig_ "Trailer2TPMThresCfg_AxleNr_ISig_6";
BA_ "GenSigCycleTime" SG_ 1525 Trailer2TPMThresCfg_ExtOverPres_ 100;
BA_ "GenSigCycleTimeActive" SG_ 1525 Trailer2TPMThresCfg_ExtOverPres_ 100;
BA_ "GenSigStartValue" SG_ 1525 Trailer2TPMThresCfg_ExtOverPres_ 255;
BA_ "NeedsUpdateBit" SG_ 1525 Trailer2TPMThresCfg_ExtOverPres_ 1;
BA_ "Platform_VMCU1_Sig" SG_ 1525 Trailer2TPMThresCfg_ExtOverPres_ 1;
BA_ "SystemSignalLongSymbol" SG_ 1525 Trailer2TPMThresCfg_ExtOverPres_ "Trailer2TPMThresCfg_ExtOverPres_ISig_6";
BA_ "GenSigCycleTime" SG_ 1525 Trailer2TPMThresCfg_OverPres_ISi 100;
BA_ "GenSigCycleTimeActive" SG_ 1525 Trailer2TPMThresCfg_OverPres_ISi 100;
BA_ "GenSigStartValue" SG_ 1525 Trailer2TPMThresCfg_OverPres_ISi 255;
BA_ "NeedsUpdateBit" SG_ 1525 Trailer2TPMThresCfg_OverPres_ISi 1;
BA_ "Platform_VMCU1_Sig" SG_ 1525 Trailer2TPMThresCfg_OverPres_ISi 1;
BA_ "SystemSignalLongSymbol" SG_ 1525 Trailer2TPMThresCfg_OverPres_ISi "Trailer2TPMThresCfg_OverPres_ISig_6";
BA_ "GenSigCycleTime" SG_ 1525 Trailer2TPMAxlTireCfg_Axle4_ISig 100;
BA_ "GenSigCycleTimeActive" SG_ 1525 Trailer2TPMAxlTireCfg_Axle4_ISig 100;
BA_ "GenSigStartValue" SG_ 1525 Trailer2TPMAxlTireCfg_Axle4_ISig 7;
BA_ "Platform_VMCU1_Sig" SG_ 1525 Trailer2TPMAxlTireCfg_Axle4_ISig 1;
BA_ "SystemSignalLongSymbol" SG_ 1525 Trailer2TPMAxlTireCfg_Axle4_ISig "Trailer2TPMAxlTireCfg_Axle4_ISig_6";
BA_ "GenSigCycleTime" SG_ 1525 Trailer2TPMAxlTireCfg_Axle1_ISig 100;
BA_ "GenSigCycleTimeActive" SG_ 1525 Trailer2TPMAxlTireCfg_Axle1_ISig 100;
BA_ "GenSigStartValue" SG_ 1525 Trailer2TPMAxlTireCfg_Axle1_ISig 7;
BA_ "Platform_VMCU1_Sig" SG_ 1525 Trailer2TPMAxlTireCfg_Axle1_ISig 1;
BA_ "SystemSignalLongSymbol" SG_ 1525 Trailer2TPMAxlTireCfg_Axle1_ISig "Trailer2TPMAxlTireCfg_Axle1_ISig_6";
BA_ "GenSigCycleTime" SG_ 1525 Trailer2TPMThresCfg_ExtUnderPres 100;
BA_ "GenSigCycleTimeActive" SG_ 1525 Trailer2TPMThresCfg_ExtUnderPres 100;
BA_ "GenSigStartValue" SG_ 1525 Trailer2TPMThresCfg_ExtUnderPres 255;
BA_ "NeedsUpdateBit" SG_ 1525 Trailer2TPMThresCfg_ExtUnderPres 1;
BA_ "Platform_VMCU1_Sig" SG_ 1525 Trailer2TPMThresCfg_ExtUnderPres 1;
BA_ "SystemSignalLongSymbol" SG_ 1525 Trailer2TPMThresCfg_ExtUnderPres "Trailer2TPMThresCfg_ExtUnderPres_ISig_6";
BA_ "GenSigCycleTime" SG_ 1525 Trailer2TPMAxlTireCfg_Axle5_ISig 100;
BA_ "GenSigCycleTimeActive" SG_ 1525 Trailer2TPMAxlTireCfg_Axle5_ISig 100;
BA_ "GenSigStartValue" SG_ 1525 Trailer2TPMAxlTireCfg_Axle5_ISig 7;
BA_ "Platform_VMCU1_Sig" SG_ 1525 Trailer2TPMAxlTireCfg_Axle5_ISig 1;
BA_ "SystemSignalLongSymbol" SG_ 1525 Trailer2TPMAxlTireCfg_Axle5_ISig "Trailer2TPMAxlTireCfg_Axle5_ISig_6";
BA_ "GenSigCycleTime" SG_ 1525 Trailer2TPMAxlTireCfg_Axle2_ISig 100;
BA_ "GenSigCycleTimeActive" SG_ 1525 Trailer2TPMAxlTireCfg_Axle2_ISig 100;
BA_ "GenSigStartValue" SG_ 1525 Trailer2TPMAxlTireCfg_Axle2_ISig 7;
BA_ "Platform_VMCU1_Sig" SG_ 1525 Trailer2TPMAxlTireCfg_Axle2_ISig 1;
BA_ "SystemSignalLongSymbol" SG_ 1525 Trailer2TPMAxlTireCfg_Axle2_ISig "Trailer2TPMAxlTireCfg_Axle2_ISig_6";
BA_ "GenSigSendType" SG_ 1525 Trailer2TPMType_UB_ISig_6 7;
BA_ "Platform_VMCU1_Sig" SG_ 1525 Trailer2TPMType_UB_ISig_6 1;
BA_ "GenSigCycleTime" SG_ 1525 Trailer2TPMAxlTireCfg_Axle3_ISig 100;
BA_ "GenSigCycleTimeActive" SG_ 1525 Trailer2TPMAxlTireCfg_Axle3_ISig 100;
BA_ "GenSigStartValue" SG_ 1525 Trailer2TPMAxlTireCfg_Axle3_ISig 7;
BA_ "Platform_VMCU1_Sig" SG_ 1525 Trailer2TPMAxlTireCfg_Axle3_ISig 1;
BA_ "SystemSignalLongSymbol" SG_ 1525 Trailer2TPMAxlTireCfg_Axle3_ISig "Trailer2TPMAxlTireCfg_Axle3_ISig_6";
BA_ "GenSigSendType" SG_ 1525 Trailer2TPMThresCfg_sg_UB_ISig_6 7;
BA_ "GenSigCycleTime" SG_ 1525 Trailer2TPMThresCfg_sg_UB_ISig_6 100;
BA_ "GenSigCycleTimeActive" SG_ 1525 Trailer2TPMThresCfg_sg_UB_ISig_6 100;
BA_ "Platform_VMCU1_Sig" SG_ 1525 Trailer2TPMThresCfg_sg_UB_ISig_6 1;
BA_REL_ "GenSigFirstTimeoutTime" BU_SG_REL_ RCIOM SG_ 928 Rear1ClutchRequest 3000;
BA_REL_ "GenSigTimeoutTime" BU_SG_REL_ RCIOM SG_ 928 Rear1ClutchRequest 270;
BA_REL_ "GenSigFirstTimeoutTime" BU_SG_REL_ CCIOM SG_ 928 TransmissionCurrentGear_ISig_6 3000;
BA_REL_ "GenSigTimeoutTime" BU_SG_REL_ CCIOM SG_ 928 TransmissionCurrentGear_ISig_6 500;
BA_REL_ "GenSigFirstTimeoutTime" BU_SG_REL_ APM SG_ 928 TransmissionCurrentGear_ISig_6 3000;
BA_REL_ "GenSigTimeoutTime" BU_SG_REL_ APM SG_ 928 TransmissionCurrentGear_ISig_6 500;
BA_REL_ "GenSigFirstTimeoutTime" BU_SG_REL_ APM SG_ 928 TransmissionOutputShaftSpeed_ISi 3000;
BA_REL_ "GenSigTimeoutTime" BU_SG_REL_ APM SG_ 928 TransmissionOutputShaftSpeed_ISi 270;
BA_REL_ "GenSigFirstTimeoutTime" BU_SG_REL_ APM SG_ 928 EngineSpeed_ISig_6 3000;
BA_REL_ "GenSigTimeoutTime" BU_SG_REL_ APM SG_ 928 EngineSpeed_ISig_6 500;
BA_REL_ "GenSigFirstTimeoutTime" BU_SG_REL_ FAS SG_ 928 EngineSpeed_ISig_6 3000;
BA_REL_ "GenSigTimeoutTime" BU_SG_REL_ FAS SG_ 928 EngineSpeed_ISig_6 500;
BA_REL_ "GenSigFirstTimeoutTime" BU_SG_REL_ CCIOM SG_ 928 EngineSpeed_ISig_6 3000;
BA_REL_ "GenSigTimeoutTime" BU_SG_REL_ CCIOM SG_ 928 EngineSpeed_ISig_6 270;
BA_REL_ "GenSigFirstTimeoutTime" BU_SG_REL_ CCIOM SG_ 928 TransmissionSelectedGear_ISig_6 3000;
BA_REL_ "GenSigTimeoutTime" BU_SG_REL_ CCIOM SG_ 928 TransmissionSelectedGear_ISig_6 270;
BA_REL_ "GenSigFirstTimeoutTime" BU_SG_REL_ RCIOM SG_ 928 LiftAxle1Request 3000;
BA_REL_ "GenSigTimeoutTime" BU_SG_REL_ RCIOM SG_ 928 LiftAxle1Request 270;
BA_REL_ "GenSigFirstTimeoutTime" BU_SG_REL_ CCIOM SG_ 928 FrontWheelDifflockRequest 3000;
BA_REL_ "GenSigTimeoutTime" BU_SG_REL_ CCIOM SG_ 928 FrontWheelDifflockRequest 500;
BA_REL_ "GenSigFirstTimeoutTime" BU_SG_REL_ APM SG_ 827 RrAxle2LeftWheelRelativeSpeed_IS 3000;
BA_REL_ "GenSigTimeoutTime" BU_SG_REL_ APM SG_ 827 RrAxle2LeftWheelRelativeSpeed_IS 240;
BA_REL_ "GenSigFirstTimeoutTime" BU_SG_REL_ APM SG_ 827 RrAxle1LeftWheelRelativeSpeed_IS 3000;
BA_REL_ "GenSigTimeoutTime" BU_SG_REL_ APM SG_ 827 RrAxle1LeftWheelRelativeSpeed_IS 240;
BA_REL_ "GenSigFirstTimeoutTime" BU_SG_REL_ APM SG_ 827 RrAxle2RightWheelRelativeSpeed_I 3000;
BA_REL_ "GenSigTimeoutTime" BU_SG_REL_ APM SG_ 827 RrAxle2RightWheelRelativeSpeed_I 240;
BA_REL_ "GenSigFirstTimeoutTime" BU_SG_REL_ APM SG_ 827 FrAxleRightWheelRelativeSpeed_IS 3000;
BA_REL_ "GenSigTimeoutTime" BU_SG_REL_ APM SG_ 827 FrAxleRightWheelRelativeSpeed_IS 240;
BA_REL_ "GenSigFirstTimeoutTime" BU_SG_REL_ RCIOM SG_ 827 FrAxleRightWheelRelativeSpeed_IS 3000;
BA_REL_ "GenSigTimeoutTime" BU_SG_REL_ RCIOM SG_ 827 FrAxleRightWheelRelativeSpeed_IS 240;
BA_REL_ "GenSigFirstTimeoutTime" BU_SG_REL_ CCIOM SG_ 827 FrontAxleSpeed_ISig_6 3000;
BA_REL_ "GenSigTimeoutTime" BU_SG_REL_ CCIOM SG_ 827 FrontAxleSpeed_ISig_6 240;
BA_REL_ "GenSigFirstTimeoutTime" BU_SG_REL_ APM SG_ 827 FrontAxleSpeed_ISig_6 3000;
BA_REL_ "GenSigTimeoutTime" BU_SG_REL_ APM SG_ 827 FrontAxleSpeed_ISig_6 240;
BA_REL_ "GenSigFirstTimeoutTime" BU_SG_REL_ RCIOM SG_ 827 FrontAxleSpeed_ISig_6 3000;
BA_REL_ "GenSigTimeoutTime" BU_SG_REL_ RCIOM SG_ 827 FrontAxleSpeed_ISig_6 240;
BA_REL_ "GenSigFirstTimeoutTime" BU_SG_REL_ RCIOM SG_ 827 FrAxleLeftWheelRelativeSpeed_ISi 3000;
BA_REL_ "GenSigTimeoutTime" BU_SG_REL_ RCIOM SG_ 827 FrAxleLeftWheelRelativeSpeed_ISi 240;
BA_REL_ "GenSigFirstTimeoutTime" BU_SG_REL_ APM SG_ 827 FrAxleLeftWheelRelativeSpeed_ISi 3000;
BA_REL_ "GenSigTimeoutTime" BU_SG_REL_ APM SG_ 827 FrAxleLeftWheelRelativeSpeed_ISi 240;
BA_REL_ "GenSigFirstTimeoutTime" BU_SG_REL_ APM SG_ 827 RrAxle1RightWheelRelativeSpeed_I 3000;
BA_REL_ "GenSigTimeoutTime" BU_SG_REL_ APM SG_ 827 RrAxle1RightWheelRelativeSpeed_I 240;
BA_REL_ "GenSigFirstTimeoutTime" BU_SG_REL_ RCIOM SG_ 537 RampLevelStorageRequest_ISig_6 3000;
BA_REL_ "GenSigTimeoutTime" BU_SG_REL_ RCIOM SG_ 537 RampLevelStorageRequest_ISig_6 150;
BA_REL_ "GenSigFirstTimeoutTime" BU_SG_REL_ RCIOM SG_ 537 LevelStrokeRequest_ISig_6 3000;
BA_REL_ "GenSigTimeoutTime" BU_SG_REL_ RCIOM SG_ 537 LevelStrokeRequest_ISig_6 150;
BA_REL_ "GenSigFirstTimeoutTime" BU_SG_REL_ RCIOM SG_ 537 BBSystemProhibitControlRequest_I 3000;
BA_REL_ "GenSigTimeoutTime" BU_SG_REL_ RCIOM SG_ 537 BBSystemProhibitControlRequest_I 150;
BA_REL_ "GenSigFirstTimeoutTime" BU_SG_REL_ RCIOM SG_ 537 RideHeightFunctionRequest_ISig_6 3000;
BA_REL_ "GenSigTimeoutTime" BU_SG_REL_ RCIOM SG_ 537 RideHeightFunctionRequest_ISig_6 500;
BA_REL_ "GenSigFirstTimeoutTime" BU_SG_REL_ RCIOM SG_ 537 BBSystemAlternatLoadDistribReq_I 3000;
BA_REL_ "GenSigTimeoutTime" BU_SG_REL_ RCIOM SG_ 537 BBSystemAlternatLoadDistribReq_I 500;
BA_REL_ "GenSigFirstTimeoutTime" BU_SG_REL_ RCIOM SG_ 537 AltLoadDistribution_rqst_ISig_6 3000;
BA_REL_ "GenSigTimeoutTime" BU_SG_REL_ RCIOM SG_ 537 AltLoadDistribution_rqst_ISig_6 500;
BA_REL_ "GenSigFirstTimeoutTime" BU_SG_REL_ RCIOM SG_ 537 FerryFunctionRequest_ISig_6 3000;
BA_REL_ "GenSigTimeoutTime" BU_SG_REL_ RCIOM SG_ 537 FerryFunctionRequest_ISig_6 500;
BA_REL_ "GenSigFirstTimeoutTime" BU_SG_REL_ RCIOM SG_ 537 FerryFunctionSwitchChangeReq_ISi 3000;
BA_REL_ "GenSigTimeoutTime" BU_SG_REL_ RCIOM SG_ 537 FerryFunctionSwitchChangeReq_ISi 120;
BA_REL_ "GenSigFirstTimeoutTime" BU_SG_REL_ RCIOM SG_ 537 FirstAxleLowerPrioRequested_ISig 3000;
BA_REL_ "GenSigTimeoutTime" BU_SG_REL_ RCIOM SG_ 537 FirstAxleLowerPrioRequested_ISig 500;
BA_REL_ "GenSigFirstTimeoutTime" BU_SG_REL_ RCIOM SG_ 537 BBSystemSpeedDepDriveLevelReq_IS 3000;
BA_REL_ "GenSigTimeoutTime" BU_SG_REL_ RCIOM SG_ 537 BBSystemSpeedDepDriveLevelReq_IS 150;
BA_REL_ "GenSigFirstTimeoutTime" BU_SG_REL_ RCIOM SG_ 537 LoadDistributionChangeRequest_IS 3000;
BA_REL_ "GenSigTimeoutTime" BU_SG_REL_ RCIOM SG_ 537 LoadDistributionChangeRequest_IS 500;
BA_REL_ "GenSigFirstTimeoutTime" BU_SG_REL_ RCIOM SG_ 537 BBSystemKneelRequest_ISig_6 3000;
BA_REL_ "GenSigTimeoutTime" BU_SG_REL_ RCIOM SG_ 537 BBSystemKneelRequest_ISig_6 150;
BA_REL_ "GenSigFirstTimeoutTime" BU_SG_REL_ RCIOM SG_ 537 LiftAxle1LiftPositionRequest_ISi 3000;
BA_REL_ "GenSigTimeoutTime" BU_SG_REL_ RCIOM SG_ 537 LiftAxle1LiftPositionRequest_ISi 500;
BA_REL_ "GenSigFirstTimeoutTime" BU_SG_REL_ RCIOM SG_ 537 LiftAxle2AutoLiftRequest_ISig_6 3000;
BA_REL_ "GenSigTimeoutTime" BU_SG_REL_ RCIOM SG_ 537 LiftAxle2AutoLiftRequest_ISig_6 500;
BA_REL_ "GenSigFirstTimeoutTime" BU_SG_REL_ RCIOM SG_ 537 StopLevelChangeRequest_ISig_6 3000;
BA_REL_ "GenSigTimeoutTime" BU_SG_REL_ RCIOM SG_ 537 StopLevelChangeRequest_ISig_6 150;
BA_REL_ "GenSigFirstTimeoutTime" BU_SG_REL_ RCIOM SG_ 537 RideHeightStorageRequest_ISig_6 3000;
BA_REL_ "GenSigTimeoutTime" BU_SG_REL_ RCIOM SG_ 537 RideHeightStorageRequest_ISig_6 150;
BA_REL_ "GenSigFirstTimeoutTime" BU_SG_REL_ RCIOM SG_ 537 RampLevelRequest_ISig_6 3000;
BA_REL_ "GenSigTimeoutTime" BU_SG_REL_ RCIOM SG_ 537 RampLevelRequest_ISig_6 150;
BA_REL_ "GenSigFirstTimeoutTime" BU_SG_REL_ RCIOM SG_ 537 LiftAxle1AutoLiftRequest_ISig_6 3000;
BA_REL_ "GenSigTimeoutTime" BU_SG_REL_ RCIOM SG_ 537 LiftAxle1AutoLiftRequest_ISig_6 500;
BA_REL_ "GenSigFirstTimeoutTime" BU_SG_REL_ RCIOM SG_ 537 LiftAxle2LiftPositionRequest_ISi 3000;
BA_REL_ "GenSigTimeoutTime" BU_SG_REL_ RCIOM SG_ 537 LiftAxle2LiftPositionRequest_ISi 500;
BA_REL_ "GenSigFirstTimeoutTime" BU_SG_REL_ CCIOM SG_ 531 TrailerBrakePres_rqst_UB 3000;
BA_REL_ "GenSigTimeoutTime" BU_SG_REL_ CCIOM SG_ 531 TrailerBrakePres_rqst_UB 500;
BA_REL_ "GenSigFirstTimeoutTime" BU_SG_REL_ FCIOM SG_ 531 WS_Washing_cmd 3000;
BA_REL_ "GenSigTimeoutTime" BU_SG_REL_ FCIOM SG_ 531 WS_Washing_cmd 120;
BA_REL_ "GenSigFirstTimeoutTime" BU_SG_REL_ CCIOM SG_ 531 FrAxleDiffLockActvnDriverRqst_IS 3000;
BA_REL_ "GenSigTimeoutTime" BU_SG_REL_ CCIOM SG_ 531 FrAxleDiffLockActvnDriverRqst_IS 500;
BA_REL_ "GenSigFirstTimeoutTime" BU_SG_REL_ APM SG_ 531 FuncIndIlluminationLevel_ISig_6 3000;
BA_REL_ "GenSigTimeoutTime" BU_SG_REL_ APM SG_ 531 FuncIndIlluminationLevel_ISig_6 120;
BA_REL_ "GenSigFirstTimeoutTime" BU_SG_REL_ CCIOM SG_ 531 TrailerBrakePres_rqst 3000;
BA_REL_ "GenSigTimeoutTime" BU_SG_REL_ CCIOM SG_ 531 TrailerBrakePres_rqst 500;
BA_REL_ "GenSigFirstTimeoutTime" BU_SG_REL_ FAS SG_ 531 ASREngineControlActive_ISig_6 3000;
BA_REL_ "GenSigTimeoutTime" BU_SG_REL_ FAS SG_ 531 ASREngineControlActive_ISig_6 500;
BA_REL_ "GenSigFirstTimeoutTime" BU_SG_REL_ CCIOM SG_ 531 TransmissionDrivelineEngaged_ISi 3000;
BA_REL_ "GenSigTimeoutTime" BU_SG_REL_ CCIOM SG_ 531 TransmissionDrivelineEngaged_ISi 500;
BA_REL_ "GenSigFirstTimeoutTime" BU_SG_REL_ APM SG_ 531 TransmissionDrivelineEngaged_ISi 3000;
BA_REL_ "GenSigTimeoutTime" BU_SG_REL_ APM SG_ 531 TransmissionDrivelineEngaged_ISi 500;
BA_REL_ "GenSigFirstTimeoutTime" BU_SG_REL_ APM SG_ 531 ReverseWarning_rqst_ISig_6 3000;
BA_REL_ "GenSigTimeoutTime" BU_SG_REL_ APM SG_ 531 ReverseWarning_rqst_ISig_6 120;
BA_REL_ "GenSigFirstTimeoutTime" BU_SG_REL_ RCIOM SG_ 531 ReverseWarning_rqst_ISig_6 3000;
BA_REL_ "GenSigTimeoutTime" BU_SG_REL_ RCIOM SG_ 531 ReverseWarning_rqst_ISig_6 120;
BA_REL_ "GenSigFirstTimeoutTime" BU_SG_REL_ CCIOM SG_ 531 FogLight_Rear_cmd 3000;
BA_REL_ "GenSigTimeoutTime" BU_SG_REL_ CCIOM SG_ 531 FogLight_Rear_cmd 120;
BA_REL_ "GenSigFirstTimeoutTime" BU_SG_REL_ RCIOM SG_ 531 FogLight_Rear_cmd 3000;
BA_REL_ "GenSigTimeoutTime" BU_SG_REL_ RCIOM SG_ 531 FogLight_Rear_cmd 120;
BA_REL_ "GenSigFirstTimeoutTime" BU_SG_REL_ FCIOM SG_ 531 FogLight_Front_cmd_ISig_6 3000;
BA_REL_ "GenSigTimeoutTime" BU_SG_REL_ FCIOM SG_ 531 FogLight_Front_cmd_ISig_6 120;
BA_REL_ "GenSigFirstTimeoutTime" BU_SG_REL_ EBS SG_ 531 SplitBoxDifflockActvnDrvrRqst_IS 3000;
BA_REL_ "GenSigTimeoutTime" BU_SG_REL_ EBS SG_ 531 SplitBoxDifflockActvnDrvrRqst_IS 500;
BA_REL_ "GenSigFirstTimeoutTime" BU_SG_REL_ CCIOM SG_ 531 SplitBoxDifflockActvnDrvrRqst_IS 3000;
BA_REL_ "GenSigTimeoutTime" BU_SG_REL_ CCIOM SG_ 531 SplitBoxDifflockActvnDrvrRqst_IS 500;
BA_REL_ "GenSigFirstTimeoutTime" BU_SG_REL_ APM SG_ 531 AntiLockBrakingActive_ISig_6 3000;
BA_REL_ "GenSigTimeoutTime" BU_SG_REL_ APM SG_ 531 AntiLockBrakingActive_ISig_6 120;
BA_REL_ "GenSigFirstTimeoutTime" BU_SG_REL_ FAS SG_ 531 AntiLockBrakingActive_ISig_6 3000;
BA_REL_ "GenSigTimeoutTime" BU_SG_REL_ FAS SG_ 531 AntiLockBrakingActive_ISig_6 120;
BA_REL_ "GenSigFirstTimeoutTime" BU_SG_REL_ EAS SG_ 531 AntiLockBrakingActive_ISig_6 3000;
BA_REL_ "GenSigTimeoutTime" BU_SG_REL_ EAS SG_ 531 AntiLockBrakingActive_ISig_6 120;
BA_REL_ "GenSigFirstTimeoutTime" BU_SG_REL_ FAS SG_ 531 ASRBrakeControlActive_ISig_6 3000;
BA_REL_ "GenSigTimeoutTime" BU_SG_REL_ FAS SG_ 531 ASRBrakeControlActive_ISig_6 500;
BA_REL_ "GenSigFirstTimeoutTime" BU_SG_REL_ EAS SG_ 531 ASRBrakeControlActive_ISig_6 3000;
BA_REL_ "GenSigTimeoutTime" BU_SG_REL_ EAS SG_ 531 ASRBrakeControlActive_ISig_6 500;
BA_REL_ "GenSigFirstTimeoutTime" BU_SG_REL_ APM SG_ 531 ASRBrakeControlActive_ISig_6 3000;
BA_REL_ "GenSigTimeoutTime" BU_SG_REL_ APM SG_ 531 ASRBrakeControlActive_ISig_6 500;
BA_REL_ "GenSigFirstTimeoutTime" BU_SG_REL_ CCIOM SG_ 531 GearLeverPosition_ISig_6 3000;
BA_REL_ "GenSigTimeoutTime" BU_SG_REL_ CCIOM SG_ 531 GearLeverPosition_ISig_6 500;
BA_REL_ "GenSigFirstTimeoutTime" BU_SG_REL_ APM SG_ 531 GearLeverPosition_ISig_6 3000;
BA_REL_ "GenSigTimeoutTime" BU_SG_REL_ APM SG_ 531 GearLeverPosition_ISig_6 500;
BA_REL_ "GenSigFirstTimeoutTime" BU_SG_REL_ APM SG_ 531 ClutchPedalPosition_ISig_6 3000;
BA_REL_ "GenSigTimeoutTime" BU_SG_REL_ APM SG_ 531 ClutchPedalPosition_ISig_6 120;
BA_REL_ "GenSigFirstTimeoutTime" BU_SG_REL_ RCIOM SG_ 531 BackToDriveReq_ISig_6 3000;
BA_REL_ "GenSigTimeoutTime" BU_SG_REL_ RCIOM SG_ 531 BackToDriveReq_ISig_6 120;
BA_REL_ "GenSigFirstTimeoutTime" BU_SG_REL_ APM SG_ 531 TransmissionShiftInProcess_ISig_ 3000;
BA_REL_ "GenSigTimeoutTime" BU_SG_REL_ APM SG_ 531 TransmissionShiftInProcess_ISig_ 500;
BA_REL_ "GenSigFirstTimeoutTime" BU_SG_REL_ APM SG_ 531 EngineTorqueMode_ISig_6 3000;
BA_REL_ "GenSigTimeoutTime" BU_SG_REL_ APM SG_ 531 EngineTorqueMode_ISig_6 120;
BA_REL_ "GenSigFirstTimeoutTime" BU_SG_REL_ CCIOM SG_ 392 WorkingLightChassisOutp_cmd 3000;
BA_REL_ "GenSigTimeoutTime" BU_SG_REL_ CCIOM SG_ 392 WorkingLightChassisOutp_cmd 60;
BA_REL_ "GenSigFirstTimeoutTime" BU_SG_REL_ FCIOM SG_ 392 PositionLight_cmd 3000;
BA_REL_ "GenSigTimeoutTime" BU_SG_REL_ FCIOM SG_ 392 PositionLight_cmd 60;
BA_REL_ "GenSigFirstTimeoutTime" BU_SG_REL_ RCIOM SG_ 392 PositionLight_cmd 3000;
BA_REL_ "GenSigTimeoutTime" BU_SG_REL_ RCIOM SG_ 392 PositionLight_cmd 60;
BA_REL_ "GenSigFirstTimeoutTime" BU_SG_REL_ FCIOM SG_ 392 StaticCornerLight_cmd 3000;
BA_REL_ "GenSigTimeoutTime" BU_SG_REL_ FCIOM SG_ 392 StaticCornerLight_cmd 60;
BA_REL_ "GenSigFirstTimeoutTime" BU_SG_REL_ FCIOM SG_ 392 ExtraMainBeam_cmd 3000;
BA_REL_ "GenSigTimeoutTime" BU_SG_REL_ FCIOM SG_ 392 ExtraMainBeam_cmd 60;
BA_REL_ "GenSigFirstTimeoutTime" BU_SG_REL_ APM SG_ 392 BacklightCmd_ISig_6 3000;
BA_REL_ "GenSigTimeoutTime" BU_SG_REL_ APM SG_ 392 BacklightCmd_ISig_6 60;
BA_REL_ "GenSigFirstTimeoutTime" BU_SG_REL_ RCIOM SG_ 392 DirectionIndicatorLights_cmd 3000;
BA_REL_ "GenSigTimeoutTime" BU_SG_REL_ RCIOM SG_ 392 DirectionIndicatorLights_cmd 60;
BA_REL_ "GenSigFirstTimeoutTime" BU_SG_REL_ FCIOM SG_ 392 DirectionIndicatorLights_cmd 3000;
BA_REL_ "GenSigTimeoutTime" BU_SG_REL_ FCIOM SG_ 392 DirectionIndicatorLights_cmd 60;
BA_REL_ "GenSigFirstTimeoutTime" BU_SG_REL_ CCIOM SG_ 392 DirectionIndicatorLights_cmd 3000;
BA_REL_ "GenSigTimeoutTime" BU_SG_REL_ CCIOM SG_ 392 DirectionIndicatorLights_cmd 60;
BA_REL_ "GenSigFirstTimeoutTime" BU_SG_REL_ FCIOM SG_ 392 DirectionIndicatorLights_rqst 3000;
BA_REL_ "GenSigTimeoutTime" BU_SG_REL_ FCIOM SG_ 392 DirectionIndicatorLights_rqst 60;
BA_REL_ "GenSigFirstTimeoutTime" BU_SG_REL_ APM SG_ 392 DriverEngineShutOff_rqst 3000;
BA_REL_ "GenSigTimeoutTime" BU_SG_REL_ APM SG_ 392 DriverEngineShutOff_rqst 60;
BA_REL_ "GenSigFirstTimeoutTime" BU_SG_REL_ FCIOM SG_ 392 DippedBeam_cmd 3000;
BA_REL_ "GenSigTimeoutTime" BU_SG_REL_ FCIOM SG_ 392 DippedBeam_cmd 60;
BA_REL_ "GenSigFirstTimeoutTime" BU_SG_REL_ RCIOM SG_ 392 DippedBeam_cmd 3000;
BA_REL_ "GenSigTimeoutTime" BU_SG_REL_ RCIOM SG_ 392 DippedBeam_cmd 60;
BA_REL_ "GenSigFirstTimeoutTime" BU_SG_REL_ RCIOM SG_ 392 BrakePedalPosition_ISig_6 3000;
BA_REL_ "GenSigTimeoutTime" BU_SG_REL_ RCIOM SG_ 392 BrakePedalPosition_ISig_6 60;
BA_REL_ "GenSigFirstTimeoutTime" BU_SG_REL_ APM SG_ 392 BrakePedalPosition_ISig_6 3000;
BA_REL_ "GenSigTimeoutTime" BU_SG_REL_ APM SG_ 392 BrakePedalPosition_ISig_6 60;
BA_REL_ "GenSigFirstTimeoutTime" BU_SG_REL_ APM SG_ 392 AcctrPedalKickDownSw_stat_ISig_6 3000;
BA_REL_ "GenSigTimeoutTime" BU_SG_REL_ APM SG_ 392 AcctrPedalKickDownSw_stat_ISig_6 60;
BA_REL_ "GenSigFirstTimeoutTime" BU_SG_REL_ FCIOM SG_ 392 HeadLightLevel_cmd 3000;
BA_REL_ "GenSigTimeoutTime" BU_SG_REL_ FCIOM SG_ 392 HeadLightLevel_cmd 60;
BA_REL_ "GenSigFirstTimeoutTime" BU_SG_REL_ CCIOM SG_ 392 HeadLightLevel_cmd 3000;
BA_REL_ "GenSigTimeoutTime" BU_SG_REL_ CCIOM SG_ 392 HeadLightLevel_cmd 60;
BA_REL_ "GenSigFirstTimeoutTime" BU_SG_REL_ RCIOM SG_ 392 DRL_cmd 3000;
BA_REL_ "GenSigTimeoutTime" BU_SG_REL_ RCIOM SG_ 392 DRL_cmd 60;
BA_REL_ "GenSigFirstTimeoutTime" BU_SG_REL_ FCIOM SG_ 392 DRL_cmd 3000;
BA_REL_ "GenSigTimeoutTime" BU_SG_REL_ FCIOM SG_ 392 DRL_cmd 60;
BA_REL_ "GenSigFirstTimeoutTime" BU_SG_REL_ APM SG_ 392 AcceleratorPedalLowIdleSwitch_IS 3000;
BA_REL_ "GenSigTimeoutTime" BU_SG_REL_ APM SG_ 392 AcceleratorPedalLowIdleSwitch_IS 60;
BA_REL_ "GenSigFirstTimeoutTime" BU_SG_REL_ FCIOM SG_ 392 MainBeam_cmd_ISig_6 3000;
BA_REL_ "GenSigTimeoutTime" BU_SG_REL_ FCIOM SG_ 392 MainBeam_cmd_ISig_6 60;
BA_REL_ "GenSigFirstTimeoutTime" BU_SG_REL_ RCIOM SG_ 392 MainBeam_cmd_ISig_6 3000;
BA_REL_ "GenSigTimeoutTime" BU_SG_REL_ RCIOM SG_ 392 MainBeam_cmd_ISig_6 60;
BA_REL_ "GenSigFirstTimeoutTime" BU_SG_REL_ FCIOM SG_ 392 Hazard_rqst_ISig_6 3000;
BA_REL_ "GenSigTimeoutTime" BU_SG_REL_ FCIOM SG_ 392 Hazard_rqst_ISig_6 60;
BA_REL_ "GenSigFirstTimeoutTime" BU_SG_REL_ FAS SG_ 392 VehicleMode_ISig_6 3000;
BA_REL_ "GenSigTimeoutTime" BU_SG_REL_ FAS SG_ 392 VehicleMode_ISig_6 500;
BA_REL_ "GenSigFirstTimeoutTime" BU_SG_REL_ CCIOM SG_ 392 VehicleMode_ISig_6 3000;
BA_REL_ "GenSigTimeoutTime" BU_SG_REL_ CCIOM SG_ 392 VehicleMode_ISig_6 500;
BA_REL_ "GenSigFirstTimeoutTime" BU_SG_REL_ TPM SG_ 392 VehicleMode_ISig_6 3000;
BA_REL_ "GenSigTimeoutTime" BU_SG_REL_ TPM SG_ 392 VehicleMode_ISig_6 500;
BA_REL_ "GenSigFirstTimeoutTime" BU_SG_REL_ RCIOM SG_ 392 VehicleMode_ISig_6 3000;
BA_REL_ "GenSigTimeoutTime" BU_SG_REL_ RCIOM SG_ 392 VehicleMode_ISig_6 500;
BA_REL_ "GenSigFirstTimeoutTime" BU_SG_REL_ FCIOM SG_ 392 VehicleMode_ISig_6 3000;
BA_REL_ "GenSigTimeoutTime" BU_SG_REL_ FCIOM SG_ 392 VehicleMode_ISig_6 500;
BA_REL_ "GenSigFirstTimeoutTime" BU_SG_REL_ APM SG_ 392 VehicleMode_ISig_6 3000;
BA_REL_ "GenSigTimeoutTime" BU_SG_REL_ APM SG_ 392 VehicleMode_ISig_6 500;
BA_REL_ "GenSigFirstTimeoutTime" BU_SG_REL_ EAS SG_ 392 VehicleMode_ISig_6 3000;
BA_REL_ "GenSigTimeoutTime" BU_SG_REL_ EAS SG_ 392 VehicleMode_ISig_6 500;
BA_REL_ "GenSigFirstTimeoutTime" BU_SG_REL_ BPMU SG_ 392 VehicleMode_ISig_6 3000;
BA_REL_ "GenSigTimeoutTime" BU_SG_REL_ BPMU SG_ 392 VehicleMode_ISig_6 500;
BA_REL_ "GenSigFirstTimeoutTime" BU_SG_REL_ APM SG_ 392 AcceleratorPedalPosition1_ISig_6 3000;
BA_REL_ "GenSigTimeoutTime" BU_SG_REL_ APM SG_ 392 AcceleratorPedalPosition1_ISig_6 60;
BA_REL_ "GenSigFirstTimeoutTime" BU_SG_REL_ CCIOM SG_ 392 AcceleratorPedalPosition1_ISig_6 3000;
BA_REL_ "GenSigTimeoutTime" BU_SG_REL_ CCIOM SG_ 392 AcceleratorPedalPosition1_ISig_6 60;
BA_REL_ "GenSigFirstTimeoutTime" BU_SG_REL_ RCIOM SG_ 392 AcceleratorPedalPosition1_ISig_6 3000;
BA_REL_ "GenSigTimeoutTime" BU_SG_REL_ RCIOM SG_ 392 AcceleratorPedalPosition1_ISig_6 60;
BA_REL_ "GenSigFirstTimeoutTime" BU_SG_REL_ VMCU SG_ 1248 TPMMateTrailerResp_ISig_6 3000;
BA_REL_ "GenSigTimeoutTime" BU_SG_REL_ VMCU SG_ 1248 TPMMateTrailerResp_ISig_6 600;
BA_REL_ "GenSigFirstTimeoutTime" BU_SG_REL_ VMCU SG_ 1248 TPMAutomaticMating_ISig_6 3000;
BA_REL_ "GenSigTimeoutTime" BU_SG_REL_ VMCU SG_ 1248 TPMAutomaticMating_ISig_6 600;
BA_REL_ "GenSigFirstTimeoutTime" BU_SG_REL_ VMCU SG_ 1248 Trailer1TPMPressureWarning_ISig_ 3000;
BA_REL_ "GenSigTimeoutTime" BU_SG_REL_ VMCU SG_ 1248 Trailer1TPMPressureWarning_ISig_ 600;
BA_REL_ "GenSigFirstTimeoutTime" BU_SG_REL_ VMCU SG_ 1248 Trailer2TPMPressureWarning_ISig_ 3000;
BA_REL_ "GenSigTimeoutTime" BU_SG_REL_ VMCU SG_ 1248 Trailer2TPMPressureWarning_ISig_ 600;
BA_REL_ "GenSigFirstTimeoutTime" BU_SG_REL_ VMCU SG_ 1248 Trailer1TPMMatedStatus_ISig_6 3000;
BA_REL_ "GenSigTimeoutTime" BU_SG_REL_ VMCU SG_ 1248 Trailer1TPMMatedStatus_ISig_6 600;
BA_REL_ "GenSigFirstTimeoutTime" BU_SG_REL_ VMCU SG_ 1248 Trailer1TPMLeakageWarning_ISig_6 3000;
BA_REL_ "GenSigTimeoutTime" BU_SG_REL_ VMCU SG_ 1248 Trailer1TPMLeakageWarning_ISig_6 600;
BA_REL_ "GenSigFirstTimeoutTime" BU_SG_REL_ VMCU SG_ 1248 Trailer2TPMMatedStatus_ISig_6 3000;
BA_REL_ "GenSigTimeoutTime" BU_SG_REL_ VMCU SG_ 1248 Trailer2TPMMatedStatus_ISig_6 600;
BA_REL_ "GenSigFirstTimeoutTime" BU_SG_REL_ VMCU SG_ 1248 TruckTPMPressureWarning_ISig_6 3000;
BA_REL_ "GenSigTimeoutTime" BU_SG_REL_ VMCU SG_ 1248 TruckTPMPressureWarning_ISig_6 600;
BA_REL_ "GenSigFirstTimeoutTime" BU_SG_REL_ VMCU SG_ 1248 TruckTPMLeakageWarning_ISig_6 3000;
BA_REL_ "GenSigTimeoutTime" BU_SG_REL_ VMCU SG_ 1248 TruckTPMLeakageWarning_ISig_6 600;
BA_REL_ "GenSigFirstTimeoutTime" BU_SG_REL_ VMCU SG_ 1248 Trailer2TPMLeakageWarning_ISig_6 3000;
BA_REL_ "GenSigTimeoutTime" BU_SG_REL_ VMCU SG_ 1248 Trailer2TPMLeakageWarning_ISig_6 600;
BA_REL_ "GenSigFirstTimeoutTime" BU_SG_REL_ VMCU SG_ 1342 TruckTPMTireInfo_Temperature_ISi 4800;
BA_REL_ "GenSigTimeoutTime" BU_SG_REL_ VMCU SG_ 1342 TruckTPMTireInfo_Temperature_ISi 1200;
BA_REL_ "GenSigFirstTimeoutTime" BU_SG_REL_ VMCU SG_ 1342 TruckTPMTireInfo_Battery_ISig_6 4800;
BA_REL_ "GenSigTimeoutTime" BU_SG_REL_ VMCU SG_ 1342 TruckTPMTireInfo_Battery_ISig_6 1200;
BA_REL_ "GenSigFirstTimeoutTime" BU_SG_REL_ VMCU SG_ 1342 TruckTPMTireInfo_PresWarn_ISig_6 4800;
BA_REL_ "GenSigTimeoutTime" BU_SG_REL_ VMCU SG_ 1342 TruckTPMTireInfo_PresWarn_ISig_6 1200;
BA_REL_ "GenSigFirstTimeoutTime" BU_SG_REL_ VMCU SG_ 1342 TruckTPMTireInfo_RefPres_ISig_6 4800;
BA_REL_ "GenSigTimeoutTime" BU_SG_REL_ VMCU SG_ 1342 TruckTPMTireInfo_RefPres_ISig_6 1200;
BA_REL_ "GenSigFirstTimeoutTime" BU_SG_REL_ VMCU SG_ 1342 TruckTPMTireInfo_Pressure_ISig_6 4800;
BA_REL_ "GenSigTimeoutTime" BU_SG_REL_ VMCU SG_ 1342 TruckTPMTireInfo_Pressure_ISig_6 1200;
BA_REL_ "GenSigFirstTimeoutTime" BU_SG_REL_ VMCU SG_ 1342 TruckTPMTireInfo_TireId_ISig_6 4800;
BA_REL_ "GenSigTimeoutTime" BU_SG_REL_ VMCU SG_ 1342 TruckTPMTireInfo_TireId_ISig_6 1200;
BA_REL_ "GenSigFirstTimeoutTime" BU_SG_REL_ VMCU SG_ 1342 TruckTPMTireInfo_LeakageWarn_ISi 4800;
BA_REL_ "GenSigTimeoutTime" BU_SG_REL_ VMCU SG_ 1342 TruckTPMTireInfo_LeakageWarn_ISi 1200;
BA_REL_ "GenSigFirstTimeoutTime" BU_SG_REL_ VMCU SG_ 1342 TruckTPMTireInfo_Active_ISig_6 4800;
BA_REL_ "GenSigTimeoutTime" BU_SG_REL_ VMCU SG_ 1342 TruckTPMTireInfo_Active_ISig_6 1200;
BA_REL_ "GenSigFirstTimeoutTime" BU_SG_REL_ VMCU SG_ 1341 Trailer2TPMLostCom_ISig_6 4800;
BA_REL_ "GenSigTimeoutTime" BU_SG_REL_ VMCU SG_ 1341 Trailer2TPMLostCom_ISig_6 1200;
BA_REL_ "GenSigFirstTimeoutTime" BU_SG_REL_ VMCU SG_ 1341 Trailer2TPMTireInfo_RefPres_ISig 4800;
BA_REL_ "GenSigTimeoutTime" BU_SG_REL_ VMCU SG_ 1341 Trailer2TPMTireInfo_RefPres_ISig 1200;
BA_REL_ "GenSigFirstTimeoutTime" BU_SG_REL_ VMCU SG_ 1341 Trailer2TPMTireInfo_PresWarn_ISi 4800;
BA_REL_ "GenSigTimeoutTime" BU_SG_REL_ VMCU SG_ 1341 Trailer2TPMTireInfo_PresWarn_ISi 1200;
BA_REL_ "GenSigFirstTimeoutTime" BU_SG_REL_ VMCU SG_ 1341 TPMTrailerPositionStat_ISig_6 4800;
BA_REL_ "GenSigTimeoutTime" BU_SG_REL_ VMCU SG_ 1341 TPMTrailerPositionStat_ISig_6 1200;
BA_REL_ "GenSigFirstTimeoutTime" BU_SG_REL_ VMCU SG_ 1341 Trailer2TPMTireInfo_Battery_ISig 4800;
BA_REL_ "GenSigTimeoutTime" BU_SG_REL_ VMCU SG_ 1341 Trailer2TPMTireInfo_Battery_ISig 1200;
BA_REL_ "GenSigFirstTimeoutTime" BU_SG_REL_ VMCU SG_ 1341 Trailer2TPMTireInfo_LeakageWarn_ 4800;
BA_REL_ "GenSigTimeoutTime" BU_SG_REL_ VMCU SG_ 1341 Trailer2TPMTireInfo_LeakageWarn_ 1200;
BA_REL_ "GenSigFirstTimeoutTime" BU_SG_REL_ VMCU SG_ 1341 Trailer2TPMTireInfo_Pressure_ISi 4800;
BA_REL_ "GenSigTimeoutTime" BU_SG_REL_ VMCU SG_ 1341 Trailer2TPMTireInfo_Pressure_ISi 1200;
BA_REL_ "GenSigFirstTimeoutTime" BU_SG_REL_ VMCU SG_ 1341 Trailer1TPMFailure_ISig_6 4800;
BA_REL_ "GenSigTimeoutTime" BU_SG_REL_ VMCU SG_ 1341 Trailer1TPMFailure_ISig_6 1200;
BA_REL_ "GenSigFirstTimeoutTime" BU_SG_REL_ VMCU SG_ 1341 TruckTPMFailure_ISig_6 4800;
BA_REL_ "GenSigTimeoutTime" BU_SG_REL_ VMCU SG_ 1341 TruckTPMFailure_ISig_6 1200;
BA_REL_ "GenSigFirstTimeoutTime" BU_SG_REL_ VMCU SG_ 1341 Trailer2TPMTireInfo_Active_ISig_ 4800;
BA_REL_ "GenSigTimeoutTime" BU_SG_REL_ VMCU SG_ 1341 Trailer2TPMTireInfo_Active_ISig_ 1200;
BA_REL_ "GenSigFirstTimeoutTime" BU_SG_REL_ VMCU SG_ 1341 Trailer2TPMFailure_ISig_6 4800;
BA_REL_ "GenSigTimeoutTime" BU_SG_REL_ VMCU SG_ 1341 Trailer2TPMFailure_ISig_6 1200;
BA_REL_ "GenSigFirstTimeoutTime" BU_SG_REL_ VMCU SG_ 1341 Trailer2TPMTireInfo_TireId_ISig_ 4800;
BA_REL_ "GenSigTimeoutTime" BU_SG_REL_ VMCU SG_ 1341 Trailer2TPMTireInfo_TireId_ISig_ 1200;
BA_REL_ "GenSigFirstTimeoutTime" BU_SG_REL_ VMCU SG_ 1341 Trailer2TPMTireInfo_Temperature_ 4800;
BA_REL_ "GenSigTimeoutTime" BU_SG_REL_ VMCU SG_ 1341 Trailer2TPMTireInfo_Temperature_ 1200;
BA_REL_ "GenSigFirstTimeoutTime" BU_SG_REL_ VMCU SG_ 1340 Trailer1TPMTireInfo_PresWarn_ISi 4800;
BA_REL_ "GenSigTimeoutTime" BU_SG_REL_ VMCU SG_ 1340 Trailer1TPMTireInfo_PresWarn_ISi 1200;
BA_REL_ "GenSigFirstTimeoutTime" BU_SG_REL_ VMCU SG_ 1340 Trailer1TPMTireInfo_RefPres_ISig 4800;
BA_REL_ "GenSigTimeoutTime" BU_SG_REL_ VMCU SG_ 1340 Trailer1TPMTireInfo_RefPres_ISig 1200;
BA_REL_ "GenSigFirstTimeoutTime" BU_SG_REL_ VMCU SG_ 1340 Trailer1TPMTireInfo_Active_ISig_ 4800;
BA_REL_ "GenSigTimeoutTime" BU_SG_REL_ VMCU SG_ 1340 Trailer1TPMTireInfo_Active_ISig_ 1200;
BA_REL_ "GenSigFirstTimeoutTime" BU_SG_REL_ VMCU SG_ 1340 TPMPosOfWMResp_TireId_ISig_6 4800;
BA_REL_ "GenSigTimeoutTime" BU_SG_REL_ VMCU SG_ 1340 TPMPosOfWMResp_TireId_ISig_6 1200;
BA_REL_ "GenSigFirstTimeoutTime" BU_SG_REL_ VMCU SG_ 1340 Trailer1TPMLostCom_ISig_6 4800;
BA_REL_ "GenSigTimeoutTime" BU_SG_REL_ VMCU SG_ 1340 Trailer1TPMLostCom_ISig_6 1200;
BA_REL_ "GenSigFirstTimeoutTime" BU_SG_REL_ VMCU SG_ 1340 TPMPosOfWMResp_Status_ISig_6 4800;
BA_REL_ "GenSigTimeoutTime" BU_SG_REL_ VMCU SG_ 1340 TPMPosOfWMResp_Status_ISig_6 1200;
BA_REL_ "GenSigFirstTimeoutTime" BU_SG_REL_ VMCU SG_ 1340 Trailer1TPMTireInfo_TireId_ISig_ 4800;
BA_REL_ "GenSigTimeoutTime" BU_SG_REL_ VMCU SG_ 1340 Trailer1TPMTireInfo_TireId_ISig_ 1200;
BA_REL_ "GenSigFirstTimeoutTime" BU_SG_REL_ VMCU SG_ 1340 Trailer1TPMTireInfo_Pressure_ISi 4800;
BA_REL_ "GenSigTimeoutTime" BU_SG_REL_ VMCU SG_ 1340 Trailer1TPMTireInfo_Pressure_ISi 1200;
BA_REL_ "GenSigFirstTimeoutTime" BU_SG_REL_ VMCU SG_ 1340 Trailer1TPMTireInfo_Battery_ISig 4800;
BA_REL_ "GenSigTimeoutTime" BU_SG_REL_ VMCU SG_ 1340 Trailer1TPMTireInfo_Battery_ISig 1200;
BA_REL_ "GenSigFirstTimeoutTime" BU_SG_REL_ VMCU SG_ 1340 Trailer1TPMTireInfo_Temperature_ 4800;
BA_REL_ "GenSigTimeoutTime" BU_SG_REL_ VMCU SG_ 1340 Trailer1TPMTireInfo_Temperature_ 1200;
BA_REL_ "GenSigFirstTimeoutTime" BU_SG_REL_ VMCU SG_ 1340 TPMPosOfWMResp_VehiclePos_ISig_6 4800;
BA_REL_ "GenSigTimeoutTime" BU_SG_REL_ VMCU SG_ 1340 TPMPosOfWMResp_VehiclePos_ISig_6 1200;
BA_REL_ "GenSigFirstTimeoutTime" BU_SG_REL_ VMCU SG_ 1340 Trailer1TPMTireInfo_LeakageWarn_ 4800;
BA_REL_ "GenSigTimeoutTime" BU_SG_REL_ VMCU SG_ 1340 Trailer1TPMTireInfo_LeakageWarn_ 1200;
BA_REL_ "GenSigFirstTimeoutTime" BU_SG_REL_ VMCU SG_ 1528 TruckTPMAxlTireCfg_Axle1_ISig_6 24000;
BA_REL_ "GenSigTimeoutTime" BU_SG_REL_ VMCU SG_ 1528 TruckTPMAxlTireCfg_Axle1_ISig_6 6000;
BA_REL_ "GenSigFirstTimeoutTime" BU_SG_REL_ VMCU SG_ 1528 TruckTPMThresCfg_ExtUnderPres_IS 24000;
BA_REL_ "GenSigTimeoutTime" BU_SG_REL_ VMCU SG_ 1528 TruckTPMThresCfg_ExtUnderPres_IS 6000;
BA_REL_ "GenSigFirstTimeoutTime" BU_SG_REL_ VMCU SG_ 1528 TruckTPMThresCfg_OverPres_ISig_6 24000;
BA_REL_ "GenSigTimeoutTime" BU_SG_REL_ VMCU SG_ 1528 TruckTPMThresCfg_OverPres_ISig_6 6000;
BA_REL_ "GenSigFirstTimeoutTime" BU_SG_REL_ VMCU SG_ 1528 TruckTPMAxlTireCfg_Axle4_ISig_6 24000;
BA_REL_ "GenSigTimeoutTime" BU_SG_REL_ VMCU SG_ 1528 TruckTPMAxlTireCfg_Axle4_ISig_6 6000;
BA_REL_ "GenSigFirstTimeoutTime" BU_SG_REL_ VMCU SG_ 1528 TruckTPMThresCfg_ExtOverPres_ISi 24000;
BA_REL_ "GenSigTimeoutTime" BU_SG_REL_ VMCU SG_ 1528 TruckTPMThresCfg_ExtOverPres_ISi 6000;
BA_REL_ "GenSigFirstTimeoutTime" BU_SG_REL_ VMCU SG_ 1528 TruckTPMAxlTireCfg_Axle2_ISig_6 24000;
BA_REL_ "GenSigTimeoutTime" BU_SG_REL_ VMCU SG_ 1528 TruckTPMAxlTireCfg_Axle2_ISig_6 6000;
BA_REL_ "GenSigFirstTimeoutTime" BU_SG_REL_ VMCU SG_ 1528 TruckTPMAxlTireCfg_Axle3_ISig_6 24000;
BA_REL_ "GenSigTimeoutTime" BU_SG_REL_ VMCU SG_ 1528 TruckTPMAxlTireCfg_Axle3_ISig_6 6000;
BA_REL_ "GenSigFirstTimeoutTime" BU_SG_REL_ VMCU SG_ 1528 TruckTPMThresCfg_UnderPres_ISig_ 24000;
BA_REL_ "GenSigTimeoutTime" BU_SG_REL_ VMCU SG_ 1528 TruckTPMThresCfg_UnderPres_ISig_ 6000;
BA_REL_ "GenSigFirstTimeoutTime" BU_SG_REL_ VMCU SG_ 1528 TruckTPMAxlTireCfg_Axle5_ISig_6 24000;
BA_REL_ "GenSigTimeoutTime" BU_SG_REL_ VMCU SG_ 1528 TruckTPMAxlTireCfg_Axle5_ISig_6 6000;
BA_REL_ "GenSigFirstTimeoutTime" BU_SG_REL_ VMCU SG_ 1528 TruckTPMThresCfg_AxleNr_ISig_6 24000;
BA_REL_ "GenSigTimeoutTime" BU_SG_REL_ VMCU SG_ 1528 TruckTPMThresCfg_AxleNr_ISig_6 6000;
BA_REL_ "GenSigFirstTimeoutTime" BU_SG_REL_ VMCU SG_ 1525 Trailer2TPMType_ISig_6 24000;
BA_REL_ "GenSigTimeoutTime" BU_SG_REL_ VMCU SG_ 1525 Trailer2TPMType_ISig_6 6000;
BA_REL_ "GenSigFirstTimeoutTime" BU_SG_REL_ VMCU SG_ 1525 Trailer2TPMThresCfg_UnderPres_IS 24000;
BA_REL_ "GenSigTimeoutTime" BU_SG_REL_ VMCU SG_ 1525 Trailer2TPMThresCfg_UnderPres_IS 6000;
BA_REL_ "GenSigFirstTimeoutTime" BU_SG_REL_ VMCU SG_ 1525 Trailer2TPMThresCfg_AxleNr_ISig_ 24000;
BA_REL_ "GenSigTimeoutTime" BU_SG_REL_ VMCU SG_ 1525 Trailer2TPMThresCfg_AxleNr_ISig_ 6000;
BA_REL_ "GenSigFirstTimeoutTime" BU_SG_REL_ VMCU SG_ 1525 Trailer2TPMThresCfg_ExtOverPres_ 24000;
BA_REL_ "GenSigTimeoutTime" BU_SG_REL_ VMCU SG_ 1525 Trailer2TPMThresCfg_ExtOverPres_ 6000;
BA_REL_ "GenSigFirstTimeoutTime" BU_SG_REL_ VMCU SG_ 1525 Trailer2TPMThresCfg_OverPres_ISi 24000;
BA_REL_ "GenSigTimeoutTime" BU_SG_REL_ VMCU SG_ 1525 Trailer2TPMThresCfg_OverPres_ISi 6000;
BA_REL_ "GenSigFirstTimeoutTime" BU_SG_REL_ VMCU SG_ 1525 Trailer2TPMAxlTireCfg_Axle4_ISig 24000;
BA_REL_ "GenSigTimeoutTime" BU_SG_REL_ VMCU SG_ 1525 Trailer2TPMAxlTireCfg_Axle4_ISig 6000;
BA_REL_ "GenSigFirstTimeoutTime" BU_SG_REL_ VMCU SG_ 1525 Trailer2TPMAxlTireCfg_Axle1_ISig 24000;
BA_REL_ "GenSigTimeoutTime" BU_SG_REL_ VMCU SG_ 1525 Trailer2TPMAxlTireCfg_Axle1_ISig 6000;
BA_REL_ "GenSigFirstTimeoutTime" BU_SG_REL_ VMCU SG_ 1525 Trailer2TPMThresCfg_ExtUnderPres 24000;
BA_REL_ "GenSigTimeoutTime" BU_SG_REL_ VMCU SG_ 1525 Trailer2TPMThresCfg_ExtUnderPres 6000;
BA_REL_ "GenSigFirstTimeoutTime" BU_SG_REL_ VMCU SG_ 1525 Trailer2TPMAxlTireCfg_Axle5_ISig 24000;
BA_REL_ "GenSigTimeoutTime" BU_SG_REL_ VMCU SG_ 1525 Trailer2TPMAxlTireCfg_Axle5_ISig 6000;
BA_REL_ "GenSigFirstTimeoutTime" BU_SG_REL_ VMCU SG_ 1525 Trailer2TPMAxlTireCfg_Axle2_ISig 24000;
BA_REL_ "GenSigTimeoutTime" BU_SG_REL_ VMCU SG_ 1525 Trailer2TPMAxlTireCfg_Axle2_ISig 6000;
BA_REL_ "GenSigFirstTimeoutTime" BU_SG_REL_ VMCU SG_ 1525 Trailer2TPMAxlTireCfg_Axle3_ISig 24000;
BA_REL_ "GenSigTimeoutTime" BU_SG_REL_ VMCU SG_ 1525 Trailer2TPMAxlTireCfg_Axle3_ISig 6000;
VAL_ 928 Rear1ClutchRequest 3 "DisengageEngage_NotAvailable" 2 "DisengageEngage_Error" 1 "DisengageEngage_Engage" 0 "DisengageEngage_Disengage" ;
VAL_ 928 LiftAxle1Request 15 "AxleLiftRequest_NotAvailable" 14 "AxleLiftRequest_Error" 13 "AxleLiftRequest_Spare7" 12 "AxleLiftRequest_Spare6" 11 "AxleLiftRequest_Spare5" 10 "AxleLiftRequest_Spare4" 9 "AxleLiftRequest_Spare3" 8 "AxleLiftRequest_Spare2" 7 "AxleLiftRequest_Spare1" 6 "AxleLiftRequest_LowerAxleFallbackCondition" 5 "AxleLiftRequest_LiftDenied" 4 "AxleLiftRequest_TransferLoadToLoweredAxle" 3 "AxleLiftRequest_LowerAxle" 2 "AxleLiftRequest_LiftAxle" 1 "AxleLiftRequest_PrepareLiftAxle" 0 "AxleLiftRequest_Idle" ;
VAL_ 928 FrontWheelDifflockRequest 3 "DisengageEngage_NotAvailable" 2 "DisengageEngage_Error" 1 "DisengageEngage_Engage" 0 "DisengageEngage_Disengage" ;
VAL_ 537 RampLevelStorageRequest_ISig_6 15 "RampLevelRequest_NotAvailable" 14 "RampLevelRequest_ErrorIndicator" 13 "RampLevelRequest_NotDefined_09" 12 "RampLevelRequest_NotDefined_08" 11 "RampLevelRequest_NotDefined_07" 10 "RampLevelRequest_NotDefined_06" 9 "RampLevelRequest_NotDefined_05" 8 "RampLevelRequest_NotDefined_04" 7 "RampLevelRequest_RampLevelM7" 6 "RampLevelRequest_RampLevelM6" 5 "RampLevelRequest_RampLevelM5" 4 "RampLevelRequest_RampLevelM4" 3 "RampLevelRequest_RampLevelM3" 2 "RampLevelRequest_RampLevelM2" 1 "RampLevelRequest_RampLevelM1" 0 "RampLevelRequest_TakeNoAction" ;
VAL_ 537 LevelStrokeRequest_ISig_6 3 "LevelStrokeRequest_NotAvailable" 2 "LevelStrokeRequest_ErrorIndicator" 1 "LevelStrokeRequest_DriveLevelControlStroke" 0 "LevelStrokeRequest_DockingLevelControlStroke" ;
VAL_ 537 BBSystemProhibitControlRequest_I 3 "Request_NotAvailable" 2 "Request_Error" 1 "Request_RequestActive" 0 "Request_NotRequested" ;
VAL_ 537 RideHeightFunctionRequest_ISig_6 15 "RideHeightFunction_NotAvailable" 14 "RideHeightFunction_ErrorIndicator" 13 "RideHeightFunction_NotDefined_05" 12 "RideHeightFunction_NotDefined_04" 11 "RideHeightFunction_NotDefined_03" 10 "RideHeightFunction_NotDefined_02" 9 "RideHeightFunction_NotDefined_01" 8 "RideHeightFunction_NotDefined" 7 "RideHeightFunction_AlternativeDrivePosition2" 6 "RideHeightFunction_AlternativeDrivePosition1" 5 "RideHeightFunction_LowDrivePosition" 4 "RideHeightFunction_HighDrivePosition" 3 "RideHeightFunction_SpeedDependentDrivePosition" 2 "RideHeightFunction_AlternativeDrivePosition" 1 "RideHeightFunction_StandardDrivePosition" 0 "RideHeightFunction_Inactive" ;
VAL_ 537 BBSystemAlternatLoadDistribReq_I 3 "InactiveActive_NotAvailable" 2 "InactiveActive_Error" 1 "InactiveActive_Active" 0 "InactiveActive_Inactive" ;
VAL_ 537 AltLoadDistribution_rqst_ISig_6 7 "AltLoadDistribution_rqst_NotAvailable" 6 "AltLoadDistribution_rqst_Error" 5 "AltLoadDistribution_rqst_Reserved_3" 4 "AltLoadDistribution_rqst_Reserved_2" 3 "AltLoadDistribution_rqst_Reserved_1" 2 "AltLoadDistribution_rqst_ALDOff" 1 "AltLoadDistribution_rqst_ALDOn" 0 "AltLoadDistribution_rqst_Idle" ;
VAL_ 537 FerryFunctionRequest_ISig_6 3 "Request_NotAvailable" 2 "Request_Error" 1 "Request_RequestActive" 0 "Request_NotRequested" ;
VAL_ 537 FerryFunctionSwitchChangeReq_ISi 3 "ChangeRequest2Bit_NotAvailable" 2 "ChangeRequest2Bit_Error" 1 "ChangeRequest2Bit_Change" 0 "ChangeRequest2Bit_TakeNoAction" ;
VAL_ 537 FirstAxleLowerPrioRequested_ISig 7 "FirstAxleLowerPrio_NotAvailable" 6 "FirstAxleLowerPrio_Error" 5 "FirstAxleLowerPrio_Reserved_03" 4 "FirstAxleLowerPrio_Reserved_02" 3 "FirstAxleLowerPrio_Reserved_01" 2 "FirstAxleLowerPrio_Reserved" 1 "FirstAxleLowerPrio_LowerPusher" 0 "FirstAxleLowerPrio_LowerTag" ;
VAL_ 537 BBSystemSpeedDepDriveLevelReq_IS 3 "BBSystemSpeedDepDriveLevelReq_NotAvailable" 2 "BBSystemSpeedDepDriveLevelReq_ErrorIndicator" 1 "BBSystemSpeedDepDriveLevelReq_SpeedDependentDrivePosition" 0 "BBSystemSpeedDepDriveLevelReq_TakeNoAction" ;
VAL_ 537 LoadDistributionChangeRequest_IS 3 "LoadDistributionChangeRequest_NotAvailable" 2 "LoadDistributionChangeRequest_Error" 1 "LoadDistributionChangeRequest_ChangeLoadDistribution" 0 "LoadDistributionChangeRequest_Idle" ;
VAL_ 537 BBSystemKneelRequest_ISig_6 3 "Request_NotAvailable" 2 "Request_Error" 1 "Request_RequestActive" 0 "Request_NotRequested" ;
VAL_ 537 LiftAxle1LiftPositionRequest_ISi 7 "LiftAxleLiftPositionRequest_NotAvailable" 6 "LiftAxleLiftPositionRequest_Error" 5 "LiftAxleLiftPositionRequest_Reserved_02" 4 "LiftAxleLiftPositionRequest_Reserved_01" 3 "LiftAxleLiftPositionRequest_Reserved" 2 "LiftAxleLiftPositionRequest_Up" 1 "LiftAxleLiftPositionRequest_Down" 0 "LiftAxleLiftPositionRequest_Idle" ;
VAL_ 537 LiftAxle2AutoLiftRequest_ISig_6 3 "InactiveActive_NotAvailable" 2 "InactiveActive_Error" 1 "InactiveActive_Active" 0 "InactiveActive_Inactive" ;
VAL_ 537 StopLevelChangeRequest_ISig_6 3 "Request_NotAvailable" 2 "Request_Error" 1 "Request_RequestActive" 0 "Request_NotRequested" ;
VAL_ 537 RideHeightStorageRequest_ISig_6 15 "RideHeightStorageRequest_NotAvailable" 14 "RideHeightStorageRequest_ErrorIndicator" 13 "RideHeightStorageRequest_NotDefined_06" 12 "RideHeightStorageRequest_NotDefined_05" 11 "RideHeightStorageRequest_NotDefined_04" 10 "RideHeightStorageRequest_NotDefined_03" 9 "RideHeightStorageRequest_NotDefined_02" 8 "RideHeightStorageRequest_NotDefined_01" 7 "RideHeightStorageRequest_NotDefined" 6 "RideHeightStorageRequest_ResetHighDrivePosition" 5 "RideHeightStorageRequest_ResetLowDrivePosition" 4 "RideHeightStorageRequest_StoreHighDrivePosition" 3 "RideHeightStorageRequest_StoreLowDrivePosition" 2 "RideHeightStorageRequest_StoreStandardUserDrivePosition" 1 "RideHeightStorageRequest_ResetToStoreFactoryDrivePosition" 0 "RideHeightStorageRequest_TakeNoAction" ;
VAL_ 537 RampLevelRequest_ISig_6 15 "RampLevelRequest_NotAvailable" 14 "RampLevelRequest_ErrorIndicator" 13 "RampLevelRequest_NotDefined_09" 12 "RampLevelRequest_NotDefined_08" 11 "RampLevelRequest_NotDefined_07" 10 "RampLevelRequest_NotDefined_06" 9 "RampLevelRequest_NotDefined_05" 8 "RampLevelRequest_NotDefined_04" 7 "RampLevelRequest_RampLevelM7" 6 "RampLevelRequest_RampLevelM6" 5 "RampLevelRequest_RampLevelM5" 4 "RampLevelRequest_RampLevelM4" 3 "RampLevelRequest_RampLevelM3" 2 "RampLevelRequest_RampLevelM2" 1 "RampLevelRequest_RampLevelM1" 0 "RampLevelRequest_TakeNoAction" ;
VAL_ 537 LiftAxle1AutoLiftRequest_ISig_6 3 "InactiveActive_NotAvailable" 2 "InactiveActive_Error" 1 "InactiveActive_Active" 0 "InactiveActive_Inactive" ;
VAL_ 537 LiftAxle2LiftPositionRequest_ISi 7 "LiftAxleLiftPositionRequest_NotAvailable" 6 "LiftAxleLiftPositionRequest_Error" 5 "LiftAxleLiftPositionRequest_Reserved_02" 4 "LiftAxleLiftPositionRequest_Reserved_01" 3 "LiftAxleLiftPositionRequest_Reserved" 2 "LiftAxleLiftPositionRequest_Up" 1 "LiftAxleLiftPositionRequest_Down" 0 "LiftAxleLiftPositionRequest_Idle" ;
VAL_ 531 WS_Washing_cmd 3 "InactiveActive_NotAvailable" 2 "InactiveActive_Error" 1 "InactiveActive_Active" 0 "InactiveActive_Inactive" ;
VAL_ 531 FrAxleDiffLockActvnDriverRqst_IS 3 "DisengageEngage_NotAvailable" 2 "DisengageEngage_Error" 1 "DisengageEngage_Engage" 0 "DisengageEngage_Disengage" ;
VAL_ 531 FuncIndIlluminationLevel_ISig_6 7 "FuncIndIlluminationLevel_NotAvailable" 6 "FuncIndIlluminationLevel_Error" 5 "FuncIndIlluminationLevel_Spare" 4 "FuncIndIlluminationLevel_IlluminationLevel4" 3 "FuncIndIlluminationLevel_IlluminationLevel3" 2 "FuncIndIlluminationLevel_IlluminationLevel2" 1 "FuncIndIlluminationLevel_IlluminationLevel1" 0 "FuncIndIlluminationLevel_IlluminationOff" ;
VAL_ 531 ASREngineControlActive_ISig_6 3 "PassiveActive2_DontCareTakeNoAction" 2 "PassiveActive2_Reserved" 1 "PassiveActive2_Active" 0 "PassiveActive2_PassiveButInstalled" ;
VAL_ 531 TransmissionDrivelineEngaged_ISi 3 "DisengageEngage_NotAvailable" 2 "DisengageEngage_Error" 1 "DisengageEngage_Engage" 0 "DisengageEngage_Disengage" ;
VAL_ 531 ReverseWarning_rqst_ISig_6 3 "ReverseWarning_rqst_NotAvailable" 2 "ReverseWarning_rqst_Error" 1 "ReverseWarning_rqst_SoundOn" 0 "ReverseWarning_rqst_SoundOff" ;
VAL_ 531 FogLight_Rear_cmd 3 "InactiveActive_NotAvailable" 2 "InactiveActive_Error" 1 "InactiveActive_Active" 0 "InactiveActive_Inactive" ;
VAL_ 531 FogLight_Front_cmd_ISig_6 3 "InactiveActive_NotAvailable" 2 "InactiveActive_Error" 1 "InactiveActive_Active" 0 "InactiveActive_Inactive" ;
VAL_ 531 SplitBoxDifflockActvnDrvrRqst_IS 3 "DisengageEngage_NotAvailable" 2 "DisengageEngage_Error" 1 "DisengageEngage_Engage" 0 "DisengageEngage_Disengage" ;
VAL_ 531 AntiLockBrakingActive_ISig_6 3 "AntiLockBrakingActive_NotAvailable" 2 "AntiLockBrakingActive_Reserved" 1 "AntiLockBrakingActive_ABSActive" 0 "AntiLockBrakingActive_ABSPassiveButInstalled" ;
VAL_ 531 ASRBrakeControlActive_ISig_6 3 "PassiveActive2_DontCareTakeNoAction" 2 "PassiveActive2_Reserved" 1 "PassiveActive2_Active" 0 "PassiveActive2_PassiveButInstalled" ;
VAL_ 531 GearLeverPosition_ISig_6 15 "GearLeverPosition_NotAvailable" 14 "GearLeverPosition_Error" 13 "GearLeverPosition_SpareValue_06" 12 "GearLeverPosition_SpareValue_05" 11 "GearLeverPosition_SpareValue_04" 10 "GearLeverPosition_SpareValue_03" 9 "GearLeverPosition_SpareValue_02" 8 "GearLeverPosition_SpareValue_01" 7 "GearLeverPosition_SpareValue" 6 "GearLeverPosition_SEG6" 5 "GearLeverPosition_LowGear" 4 "GearLeverPosition_Manual" 3 "GearLeverPosition_Automatic" 2 "GearLeverPosition_Neutral" 1 "GearLeverPosition_Reverse" 0 "GearLeverPosition_GearFoldedAway" ;
VAL_ 531 BackToDriveReq_ISig_6 3 "Requested_NotAvailable" 2 "Requested_Error" 1 "BackToDriveReq_B2DRequested" 0 "BackToDriveReq_Idle" ;
VAL_ 531 TransmissionShiftInProcess_ISig_ 3 "TransmissionShiftInProcess_NotAvailable" 2 "TransmissionShiftInProcess_Error" 1 "TransmissionShiftInProcess_ShiftInProcess" 0 "TransmissionShiftInProcess_ShiftNotInProcess" ;
VAL_ 531 EngineTorqueMode_ISig_6 15 "EngineTorqueMode_NotAvailable" 14 "EngineTorqueMode_Other" 13 "EngineTorqueMode_AirManagement" 12 "EngineTorqueMode_ServiceProcedure" 11 "EngineTorqueMode_RemoteAccelerator" 10 "EngineTorqueMode_BrakingSystem" 9 "EngineTorqueMode_HighSpeedGovernor" 8 "EngineTorqueMode_TorqueLimiting" 7 "EngineTorqueMode_ABSControl" 6 "EngineTorqueMode_TransmissionControl" 5 "EngineTorqueMode_ASRControl" 4 "EngineTorqueMode_RoadSpeedGovernor" 3 "EngineTorqueMode_PTOGovernor" 2 "EngineTorqueMode_CruiseControl" 1 "EngineTorqueMode_AcceleratorPedalOperatorSelection" 0 "EngineTorqueMode_LowIdleGovernorNoRequestDefaultMode" ;
VAL_ 392 WorkingLightChassisOutp_cmd 3 "OffOn_NotAvailable" 2 "OffOn_Error" 1 "OffOn_On" 0 "OffOn_Off" ;
VAL_ 392 PositionLight_cmd 3 "InactiveActive_NotAvailable" 2 "InactiveActive_Error" 1 "InactiveActive_Active" 0 "InactiveActive_Inactive" ;
VAL_ 392 StaticCornerLight_cmd 7 "StaticCornerLight_cmd_NotAvailable" 6 "StaticCornerLight_cmd_SpareValue_02" 5 "StaticCornerLight_cmd_SpareValue_01" 4 "StaticCornerLight_cmd_SpareValue" 3 "StaticCornerLight_cmd_LeftAndRightStaticCornerLightActive" 2 "StaticCornerLight_cmd_LeftStaticCornerLightActive" 1 "StaticCornerLight_cmd_RightStaticCornerLightActive" 0 "StaticCornerLight_cmd_Off" ;
VAL_ 392 ExtraMainBeam_cmd 3 "InactiveActive_NotAvailable" 2 "InactiveActive_Error" 1 "InactiveActive_Active" 0 "InactiveActive_Inactive" ;
VAL_ 392 BacklightCmd_ISig_6 31 "BacklightCmd_NotAvailable" 30 "BacklightCmd_Error" 16 "BacklightCmd_BacklightLevel16" 15 "BacklightCmd_BacklightLevel15" 14 "BacklightCmd_BacklightLevel14" 13 "BacklightCmd_BacklightLevel13" 12 "BacklightCmd_BacklightLevel12" 11 "BacklightCmd_BacklightLevel11" 10 "BacklightCmd_BacklightLevel10" 9 "BacklightCmd_BacklightLevel9" 8 "BacklightCmd_BacklightLevel8" 7 "BacklightCmd_BacklightLevel7" 6 "BacklightCmd_BacklightLevel6" 5 "BacklightCmd_BacklightLevel5" 4 "BacklightCmd_BacklightLevel4" 3 "BacklightCmd_BacklightLevel3" 2 "BacklightCmd_BacklightLevel2" 1 "BacklightCmd_BacklightLevel1" 0 "BacklightCmd_BacklightOff" ;
VAL_ 392 DirectionIndicatorLights_cmd 7 "DirectionIndicatorLights_cmd_NotAvailable" 6 "DirectionIndicatorLights_cmd_SpareValue_02" 5 "DirectionIndicatorLights_cmd_SpareValue_01" 4 "DirectionIndicatorLights_cmd_SpareValue" 3 "DirectionIndicatorLights_cmd_RightAndLeftActiveHazard" 2 "DirectionIndicatorLights_cmd_RightDirectionIndicatorActive" 1 "DirectionIndicatorLights_cmd_LeftDirectionIndicatorActive" 0 "DirectionIndicatorLights_cmd_NotActive" ;
VAL_ 392 DirectionIndicatorLights_rqst 7 "DirectionIndicatorLights_rqst_NotAvailable" 6 "DirectionIndicatorLights_rqst_Error" 5 "DirectionIndicatorLights_rqst_SpareValue_02" 4 "DirectionIndicatorLights_rqst_SpareValue_01" 3 "DirectionIndicatorLights_rqst_SpareValue" 2 "DirectionIndicatorLights_rqst_RightDirectionIndicatorActive" 1 "DirectionIndicatorLights_rqst_LeftDirectionIndicatorActive" 0 "DirectionIndicatorLights_rqst_NotActive" ;
VAL_ 392 DriverEngineShutOff_rqst 3 "Request_NotAvailable" 2 "Request_Error" 1 "Request_RequestActive" 0 "Request_NotRequested" ;
VAL_ 392 DippedBeam_cmd 3 "InactiveActive_NotAvailable" 2 "InactiveActive_Error" 1 "InactiveActive_Active" 0 "InactiveActive_Inactive" ;
VAL_ 392 AcctrPedalKickDownSw_stat_ISig_6 3 "PassiveActive_NotAvailable" 2 "PassiveActive_Error" 1 "PassiveActive_Active" 0 "PassiveActive_Passive" ;
VAL_ 392 DRL_cmd 3 "InactiveActive_NotAvailable" 2 "InactiveActive_Error" 1 "InactiveActive_Active" 0 "InactiveActive_Inactive" ;
VAL_ 392 AcceleratorPedalLowIdleSwitch_IS 3 "AcceleratorPedalLowIdleSwitch_NotAvailable" 2 "AcceleratorPedalLowIdleSwitch_Error" 1 "AcceleratorPedalLowIdleSwitch_INLowIdleCondition" 0 "AcceleratorPedalLowIdleSwitch_NotInLowIdleCondition" ;
VAL_ 392 MainBeam_cmd_ISig_6 7 "MainBeam_cmd_NotAvailable" 6 "MainBeam_cmd_SpareValue_03" 5 "MainBeam_cmd_SpareValue_02" 4 "MainBeam_cmd_SpareValue_01" 3 "MainBeam_cmd_SpareValue" 2 "MainBeam_cmd_MainBeamFlashOn" 1 "MainBeam_cmd_MainBeamOn" 0 "MainBeam_cmd_MainBeamOff" ;
VAL_ 392 Hazard_rqst_ISig_6 3 "InactiveActive_NotAvailable" 2 "InactiveActive_Error" 1 "InactiveActive_Active" 0 "InactiveActive_Inactive" ;
VAL_ 392 VehicleMode_ISig_6 15 "VehicleMode_NotAvailable" 14 "VehicleMode_Error" 13 "VehicleMode_Spare_7" 12 "VehicleMode_Spare_6" 11 "VehicleMode_Spare_5" 10 "VehicleMode_Spare_4" 9 "VehicleMode_Spare_3" 8 "VehicleMode_Spare_2" 7 "VehicleMode_Spare_1" 6 "VehicleMode_Running" 5 "VehicleMode_Cranking" 4 "VehicleMode_PreRunning" 3 "VehicleMode_Accessory" 2 "VehicleMode_Living" 1 "VehicleMode_Parked" 0 "VehicleMode_Hibernate" ;
VAL_ 1248 TPMMateTrailerResp_ISig_6 7 "TPMMateTrailerResp_NotAvailable" 6 "TPMMateTrailerResp_Error" 5 "TPMMateTrailerResp_Spare2" 4 "TPMMateTrailerResp_Spare1" 3 "TPMMateTrailerResp_MatedOK" 2 "TPMMateTrailerResp_Timeout" 1 "TPMMateTrailerResp_Progressing" 0 "TPMMateTrailerResp_NotActive" ;
VAL_ 1248 TPMAutomaticMating_ISig_6 3 "ActiveStatus_NotAvailable" 2 "ActiveStatus_Error" 1 "ActiveStatus_Active" 0 "ActiveStatus_NotActive" ;
VAL_ 1248 Trailer1TPMPressureWarning_ISig_ 7 "TPMPressureWarning_NotAvailable" 6 "TPMPressureWarning_Error" 5 "TPMPressureWarning_Spare" 4 "TPMPressureWarning_ExtremeUnderPressure" 3 "TPMPressureWarning_UnderPressure" 2 "TPMPressureWarning_NoWarningPressure" 1 "TPMPressureWarning_OverPressure" 0 "TPMPressureWarning_ExtremeOverPressure" ;
VAL_ 1248 Trailer2TPMPressureWarning_ISig_ 7 "TPMPressureWarning_NotAvailable" 6 "TPMPressureWarning_Error" 5 "TPMPressureWarning_Spare" 4 "TPMPressureWarning_ExtremeUnderPressure" 3 "TPMPressureWarning_UnderPressure" 2 "TPMPressureWarning_NoWarningPressure" 1 "TPMPressureWarning_OverPressure" 0 "TPMPressureWarning_ExtremeOverPressure" ;
VAL_ 1248 Trailer1TPMMatedStatus_ISig_6 3 "NoMatedMated_NotAvailable" 2 "NoMatedMated_Error" 1 "NoMatedMated_Mated" 0 "NoMatedMated_NoMated" ;
VAL_ 1248 Trailer1TPMLeakageWarning_ISig_6 7 "TPMTireLeakageWarn_NotAvailable" 6 "TPMTireLeakageWarn_Error" 5 "TPMTireLeakageWarn_Spare3" 4 "TPMTireLeakageWarn_Spare2" 3 "TPMTireLeakageWarn_Spare1" 2 "TPMTireLeakageWarn_FastLeakageDetected" 1 "TPMTireLeakageWarn_SlowLeakageDetected" 0 "TPMTireLeakageWarn_NoLeakageDetected" ;
VAL_ 1248 Trailer2TPMMatedStatus_ISig_6 3 "NoMatedMated_NotAvailable" 2 "NoMatedMated_Error" 1 "NoMatedMated_Mated" 0 "NoMatedMated_NoMated" ;
VAL_ 1248 TruckTPMPressureWarning_ISig_6 7 "TPMPressureWarning_NotAvailable" 6 "TPMPressureWarning_Error" 5 "TPMPressureWarning_Spare" 4 "TPMPressureWarning_ExtremeUnderPressure" 3 "TPMPressureWarning_UnderPressure" 2 "TPMPressureWarning_NoWarningPressure" 1 "TPMPressureWarning_OverPressure" 0 "TPMPressureWarning_ExtremeOverPressure" ;
VAL_ 1248 TruckTPMLeakageWarning_ISig_6 7 "TPMTireLeakageWarn_NotAvailable" 6 "TPMTireLeakageWarn_Error" 5 "TPMTireLeakageWarn_Spare3" 4 "TPMTireLeakageWarn_Spare2" 3 "TPMTireLeakageWarn_Spare1" 2 "TPMTireLeakageWarn_FastLeakageDetected" 1 "TPMTireLeakageWarn_SlowLeakageDetected" 0 "TPMTireLeakageWarn_NoLeakageDetected" ;
VAL_ 1248 Trailer2TPMLeakageWarning_ISig_6 7 "TPMTireLeakageWarn_NotAvailable" 6 "TPMTireLeakageWarn_Error" 5 "TPMTireLeakageWarn_Spare3" 4 "TPMTireLeakageWarn_Spare2" 3 "TPMTireLeakageWarn_Spare1" 2 "TPMTireLeakageWarn_FastLeakageDetected" 1 "TPMTireLeakageWarn_SlowLeakageDetected" 0 "TPMTireLeakageWarn_NoLeakageDetected" ;
VAL_ 1342 TruckTPMTireInfo_Battery_ISig_6 7 "TPMBatteryStatus_NotAvailable" 6 "TPMBatteryStatus_Error" 5 "TPMBatteryStatus_Spare3" 4 "TPMBatteryStatus_Spare2" 3 "TPMBatteryStatus_Spare1" 2 "TPMBatteryStatus_BatteryVeryLow" 1 "TPMBatteryStatus_BatteryLow" 0 "TPMBatteryStatus_BatteryOK" ;
VAL_ 1342 TruckTPMTireInfo_PresWarn_ISig_6 7 "TPMPressureWarning_NotAvailable" 6 "TPMPressureWarning_Error" 5 "TPMPressureWarning_Spare" 4 "TPMPressureWarning_ExtremeUnderPressure" 3 "TPMPressureWarning_UnderPressure" 2 "TPMPressureWarning_NoWarningPressure" 1 "TPMPressureWarning_OverPressure" 0 "TPMPressureWarning_ExtremeOverPressure" ;
VAL_ 1342 TruckTPMTireInfo_LeakageWarn_ISi 7 "TPMTireLeakageWarn_NotAvailable" 6 "TPMTireLeakageWarn_Error" 5 "TPMTireLeakageWarn_Spare3" 4 "TPMTireLeakageWarn_Spare2" 3 "TPMTireLeakageWarn_Spare1" 2 "TPMTireLeakageWarn_FastLeakageDetected" 1 "TPMTireLeakageWarn_SlowLeakageDetected" 0 "TPMTireLeakageWarn_NoLeakageDetected" ;
VAL_ 1342 TruckTPMTireInfo_Active_ISig_6 3 "TPMTireActive_NotAvailable" 2 "TPMTireActive_Error" 1 "TPMTireActive_TireActivePositioned" 0 "TPMTireActive_TireNotActive" ;
VAL_ 1341 Trailer2TPMLostCom_ISig_6 3 "NoYes_NotAvailable" 2 "NoYes_Error" 1 "NoYes_Yes" 0 "NoYes_No" ;
VAL_ 1341 Trailer2TPMTireInfo_PresWarn_ISi 7 "TPMPressureWarning_NotAvailable" 6 "TPMPressureWarning_Error" 5 "TPMPressureWarning_Spare" 4 "TPMPressureWarning_ExtremeUnderPressure" 3 "TPMPressureWarning_UnderPressure" 2 "TPMPressureWarning_NoWarningPressure" 1 "TPMPressureWarning_OverPressure" 0 "TPMPressureWarning_ExtremeOverPressure" ;
VAL_ 1341 TPMTrailerPositionStat_ISig_6 3 "TrailerPositionsConfirmed_NotAvailable" 2 "TrailerPositionsConfirmed_Error" 1 "TPMTrailerPositionStat_TrailerPositionsConfirmed" 0 "TPMTrailerPositionStat_TrailerPositionsNotConfirmed" ;
VAL_ 1341 Trailer2TPMTireInfo_Battery_ISig 7 "TPMBatteryStatus_NotAvailable" 6 "TPMBatteryStatus_Error" 5 "TPMBatteryStatus_Spare3" 4 "TPMBatteryStatus_Spare2" 3 "TPMBatteryStatus_Spare1" 2 "TPMBatteryStatus_BatteryVeryLow" 1 "TPMBatteryStatus_BatteryLow" 0 "TPMBatteryStatus_BatteryOK" ;
VAL_ 1341 Trailer2TPMTireInfo_LeakageWarn_ 7 "TPMTireLeakageWarn_NotAvailable" 6 "TPMTireLeakageWarn_Error" 5 "TPMTireLeakageWarn_Spare3" 4 "TPMTireLeakageWarn_Spare2" 3 "TPMTireLeakageWarn_Spare1" 2 "TPMTireLeakageWarn_FastLeakageDetected" 1 "TPMTireLeakageWarn_SlowLeakageDetected" 0 "TPMTireLeakageWarn_NoLeakageDetected" ;
VAL_ 1341 Trailer1TPMFailure_ISig_6 3 "InactiveActive_NotAvailable" 2 "InactiveActive_Error" 1 "InactiveActive_Active" 0 "InactiveActive_Inactive" ;
VAL_ 1341 TruckTPMFailure_ISig_6 3 "InactiveActive_NotAvailable" 2 "InactiveActive_Error" 1 "InactiveActive_Active" 0 "InactiveActive_Inactive" ;
VAL_ 1341 Trailer2TPMTireInfo_Active_ISig_ 3 "TPMTireActive_NotAvailable" 2 "TPMTireActive_Error" 1 "TPMTireActive_TireActivePositioned" 0 "TPMTireActive_TireNotActive" ;
VAL_ 1341 Trailer2TPMFailure_ISig_6 3 "InactiveActive_NotAvailable" 2 "InactiveActive_Error" 1 "InactiveActive_Active" 0 "InactiveActive_Inactive" ;
VAL_ 1340 Trailer1TPMTireInfo_PresWarn_ISi 7 "TPMPressureWarning_NotAvailable" 6 "TPMPressureWarning_Error" 5 "TPMPressureWarning_Spare" 4 "TPMPressureWarning_ExtremeUnderPressure" 3 "TPMPressureWarning_UnderPressure" 2 "TPMPressureWarning_NoWarningPressure" 1 "TPMPressureWarning_OverPressure" 0 "TPMPressureWarning_ExtremeOverPressure" ;
VAL_ 1340 Trailer1TPMTireInfo_Active_ISig_ 3 "TPMTireActive_NotAvailable" 2 "TPMTireActive_Error" 1 "TPMTireActive_TireActivePositioned" 0 "TPMTireActive_TireNotActive" ;
VAL_ 1340 Trailer1TPMLostCom_ISig_6 3 "NoYes_NotAvailable" 2 "NoYes_Error" 1 "NoYes_Yes" 0 "NoYes_No" ;
VAL_ 1340 TPMPosOfWMResp_Status_ISig_6 7 "TPMPosStatusResp_NotAvailable" 6 "TPMPosStatusResp_Error" 5 "TPMPosStatusResp_Spare2" 4 "TPMPosStatusResp_Spare1" 3 "TPMPosStatusResp_PositionedOK" 2 "TPMPosStatusResp_Timeout" 1 "TPMPosStatusResp_Progressing" 0 "TPMPosStatusResp_NotActive" ;
VAL_ 1340 Trailer1TPMTireInfo_Battery_ISig 7 "TPMBatteryStatus_NotAvailable" 6 "TPMBatteryStatus_Error" 5 "TPMBatteryStatus_Spare3" 4 "TPMBatteryStatus_Spare2" 3 "TPMBatteryStatus_Spare1" 2 "TPMBatteryStatus_BatteryVeryLow" 1 "TPMBatteryStatus_BatteryLow" 0 "TPMBatteryStatus_BatteryOK" ;
VAL_ 1340 TPMPosOfWMResp_VehiclePos_ISig_6 7 "TPMVehiclePos_NotAvailable" 6 "TPMVehiclePos_Error" 5 "TPMVehiclePos_Trailer5Vehicle" 4 "TPMVehiclePos_Trailer4Vehicle" 3 "TPMVehiclePos_Trailer3Vehicle" 2 "TPMVehiclePos_Trailer2Vehicle" 1 "TPMVehiclePos_Trailer1Vehicle" 0 "TPMVehiclePos_TruckVehicle" ;
VAL_ 1340 Trailer1TPMTireInfo_LeakageWarn_ 7 "TPMTireLeakageWarn_NotAvailable" 6 "TPMTireLeakageWarn_Error" 5 "TPMTireLeakageWarn_Spare3" 4 "TPMTireLeakageWarn_Spare2" 3 "TPMTireLeakageWarn_Spare1" 2 "TPMTireLeakageWarn_FastLeakageDetected" 1 "TPMTireLeakageWarn_SlowLeakageDetected" 0 "TPMTireLeakageWarn_NoLeakageDetected" ;
VAL_ 1528 TruckTPMAxlTireCfg_Axle1_ISig_6 7 "TPMAxleConfig_NotAvailable" 6 "TPMAxleConfig_Error" 5 "TPMAxleConfig_Spare" 4 "TPMAxleConfig_RearAxleWith4Tires" 3 "TPMAxleConfig_RearAxleWith2Tires" 2 "TPMAxleConfig_FrontAxleWith4Tires" 1 "TPMAxleConfig_FrontAxleWith2Tires" 0 "TPMAxleConfig_NotPresent" ;
VAL_ 1528 TruckTPMAxlTireCfg_Axle4_ISig_6 7 "TPMAxleConfig_NotAvailable" 6 "TPMAxleConfig_Error" 5 "TPMAxleConfig_Spare" 4 "TPMAxleConfig_RearAxleWith4Tires" 3 "TPMAxleConfig_RearAxleWith2Tires" 2 "TPMAxleConfig_FrontAxleWith4Tires" 1 "TPMAxleConfig_FrontAxleWith2Tires" 0 "TPMAxleConfig_NotPresent" ;
VAL_ 1528 TruckTPMAxlTireCfg_Axle2_ISig_6 7 "TPMAxleConfig_NotAvailable" 6 "TPMAxleConfig_Error" 5 "TPMAxleConfig_Spare" 4 "TPMAxleConfig_RearAxleWith4Tires" 3 "TPMAxleConfig_RearAxleWith2Tires" 2 "TPMAxleConfig_FrontAxleWith4Tires" 1 "TPMAxleConfig_FrontAxleWith2Tires" 0 "TPMAxleConfig_NotPresent" ;
VAL_ 1528 TruckTPMAxlTireCfg_Axle3_ISig_6 7 "TPMAxleConfig_NotAvailable" 6 "TPMAxleConfig_Error" 5 "TPMAxleConfig_Spare" 4 "TPMAxleConfig_RearAxleWith4Tires" 3 "TPMAxleConfig_RearAxleWith2Tires" 2 "TPMAxleConfig_FrontAxleWith4Tires" 1 "TPMAxleConfig_FrontAxleWith2Tires" 0 "TPMAxleConfig_NotPresent" ;
VAL_ 1528 TruckTPMAxlTireCfg_Axle5_ISig_6 7 "TPMAxleConfig_NotAvailable" 6 "TPMAxleConfig_Error" 5 "TPMAxleConfig_Spare" 4 "TPMAxleConfig_RearAxleWith4Tires" 3 "TPMAxleConfig_RearAxleWith2Tires" 2 "TPMAxleConfig_FrontAxleWith4Tires" 1 "TPMAxleConfig_FrontAxleWith2Tires" 0 "TPMAxleConfig_NotPresent" ;
VAL_ 1528 TruckTPMThresCfg_AxleNr_ISig_6 7 "TPMAxleNr_NotAvailable" 6 "TPMAxleNr_Error" 5 "TPMAxleNr_Axle5" 4 "TPMAxleNr_Axle4" 3 "TPMAxleNr_Axle3" 2 "TPMAxleNr_Axle2" 1 "TPMAxleNr_Axle1" 0 "TPMAxleNr_NoRequest" ;
VAL_ 1525 Trailer2TPMType_ISig_6 3 "TPMTrailerType_NotAvailable" 2 "TPMTrailerType_Error" 1 "TPMTrailerType_ISO11992Trailer" 0 "TPMTrailerType_SKFWirelessTrailer" ;
VAL_ 1525 Trailer2TPMThresCfg_AxleNr_ISig_ 7 "TPMAxleNr_NotAvailable" 6 "TPMAxleNr_Error" 5 "TPMAxleNr_Axle5" 4 "TPMAxleNr_Axle4" 3 "TPMAxleNr_Axle3" 2 "TPMAxleNr_Axle2" 1 "TPMAxleNr_Axle1" 0 "TPMAxleNr_NoRequest" ;
VAL_ 1525 Trailer2TPMAxlTireCfg_Axle4_ISig 7 "TPMAxleConfig_NotAvailable" 6 "TPMAxleConfig_Error" 5 "TPMAxleConfig_Spare" 4 "TPMAxleConfig_RearAxleWith4Tires" 3 "TPMAxleConfig_RearAxleWith2Tires" 2 "TPMAxleConfig_FrontAxleWith4Tires" 1 "TPMAxleConfig_FrontAxleWith2Tires" 0 "TPMAxleConfig_NotPresent" ;
VAL_ 1525 Trailer2TPMAxlTireCfg_Axle1_ISig 7 "TPMAxleConfig_NotAvailable" 6 "TPMAxleConfig_Error" 5 "TPMAxleConfig_Spare" 4 "TPMAxleConfig_RearAxleWith4Tires" 3 "TPMAxleConfig_RearAxleWith2Tires" 2 "TPMAxleConfig_FrontAxleWith4Tires" 1 "TPMAxleConfig_FrontAxleWith2Tires" 0 "TPMAxleConfig_NotPresent" ;
VAL_ 1525 Trailer2TPMAxlTireCfg_Axle5_ISig 7 "TPMAxleConfig_NotAvailable" 6 "TPMAxleConfig_Error" 5 "TPMAxleConfig_Spare" 4 "TPMAxleConfig_RearAxleWith4Tires" 3 "TPMAxleConfig_RearAxleWith2Tires" 2 "TPMAxleConfig_FrontAxleWith4Tires" 1 "TPMAxleConfig_FrontAxleWith2Tires" 0 "TPMAxleConfig_NotPresent" ;
VAL_ 1525 Trailer2TPMAxlTireCfg_Axle2_ISig 7 "TPMAxleConfig_NotAvailable" 6 "TPMAxleConfig_Error" 5 "TPMAxleConfig_Spare" 4 "TPMAxleConfig_RearAxleWith4Tires" 3 "TPMAxleConfig_RearAxleWith2Tires" 2 "TPMAxleConfig_FrontAxleWith4Tires" 1 "TPMAxleConfig_FrontAxleWith2Tires" 0 "TPMAxleConfig_NotPresent" ;
VAL_ 1525 Trailer2TPMAxlTireCfg_Axle3_ISig 7 "TPMAxleConfig_NotAvailable" 6 "TPMAxleConfig_Error" 5 "TPMAxleConfig_Spare" 4 "TPMAxleConfig_RearAxleWith4Tires" 3 "TPMAxleConfig_RearAxleWith2Tires" 2 "TPMAxleConfig_FrontAxleWith4Tires" 1 "TPMAxleConfig_FrontAxleWith2Tires" 0 "TPMAxleConfig_NotPresent" ;
SIG_GROUP_ 1342 TruckTPMTireInfo_sg_ISig_6 1 : TruckTPMTireInfo_Temperature_ISi TruckTPMTireInfo_Battery_ISig_6 TruckTPMTireInfo_PresWarn_ISig_6 TruckTPMTireInfo_RefPres_ISig_6 TruckTPMTireInfo_Pressure_ISig_6 TruckTPMTireInfo_TireId_ISig_6 TruckTPMTireInfo_LeakageWarn_ISi TruckTPMTireInfo_Active_ISig_6;
SIG_GROUP_ 1341 Trailer2TPMTireInfo_sg_ISig_6 1 : Trailer2TPMTireInfo_RefPres_ISig Trailer2TPMTireInfo_PresWarn_ISi Trailer2TPMTireInfo_Battery_ISig Trailer2TPMTireInfo_LeakageWarn_ Trailer2TPMTireInfo_Pressure_ISi Trailer2TPMTireInfo_Active_ISig_ Trailer2TPMTireInfo_TireId_ISig_ Trailer2TPMTireInfo_Temperature_;
SIG_GROUP_ 1340 TPMPosOfWMResp_sg_ISig_6 1 : TPMPosOfWMResp_TireId_ISig_6 TPMPosOfWMResp_Status_ISig_6 TPMPosOfWMResp_VehiclePos_ISig_6;
SIG_GROUP_ 1340 Trailer1TPMTireInfo_sg_ISig_6 1 : Trailer1TPMTireInfo_PresWarn_ISi Trailer1TPMTireInfo_RefPres_ISig Trailer1TPMTireInfo_Active_ISig_ Trailer1TPMTireInfo_TireId_ISig_ Trailer1TPMTireInfo_Pressure_ISi Trailer1TPMTireInfo_Battery_ISig Trailer1TPMTireInfo_Temperature_ Trailer1TPMTireInfo_LeakageWarn_;
SIG_GROUP_ 1528 TruckTPMThresCfg_sg_ISig_6 1 : TruckTPMThresCfg_ExtUnderPres_IS TruckTPMThresCfg_OverPres_ISig_6 TruckTPMThresCfg_ExtOverPres_ISi TruckTPMThresCfg_UnderPres_ISig_ TruckTPMThresCfg_AxleNr_ISig_6;
SIG_GROUP_ 1528 TruckTPMAxlTireCfg_sg_ISig_6 1 : TruckTPMAxlTireCfg_Axle1_ISig_6 TruckTPMAxlTireCfg_Axle4_ISig_6 TruckTPMAxlTireCfg_Axle2_ISig_6 TruckTPMAxlTireCfg_Axle3_ISig_6 TruckTPMAxlTireCfg_Axle5_ISig_6;
SIG_GROUP_ 1525 Trailer2TPMAxlTireCfg_sg_ISig_6 1 : Trailer2TPMAxlTireCfg_Axle4_ISig Trailer2TPMAxlTireCfg_Axle1_ISig Trailer2TPMAxlTireCfg_Axle5_ISig Trailer2TPMAxlTireCfg_Axle2_ISig Trailer2TPMAxlTireCfg_Axle3_ISig;
SIG_GROUP_ 1525 Trailer2TPMThresCfg_sg_ISig_6 1 : Trailer2TPMThresCfg_UnderPres_IS Trailer2TPMThresCfg_AxleNr_ISig_ Trailer2TPMThresCfg_ExtOverPres_ Trailer2TPMThresCfg_OverPres_ISi Trailer2TPMThresCfg_ExtUnderPres;
